VERSION ""

NS_ :

BS_:

BU_: RLPSU DPSU APSU PSB SHVU_RR vHS_B2 FCS EMCU SLB RCM CGW_CCU vDummy_HS_B ATS RLHV PFSU SGU ALBCU DSAU SWRC SHVU_FR RCS RRPSU BLTN_CAM SCM DLBCU OHCL RWPC RRHV WPC HOD ASAU

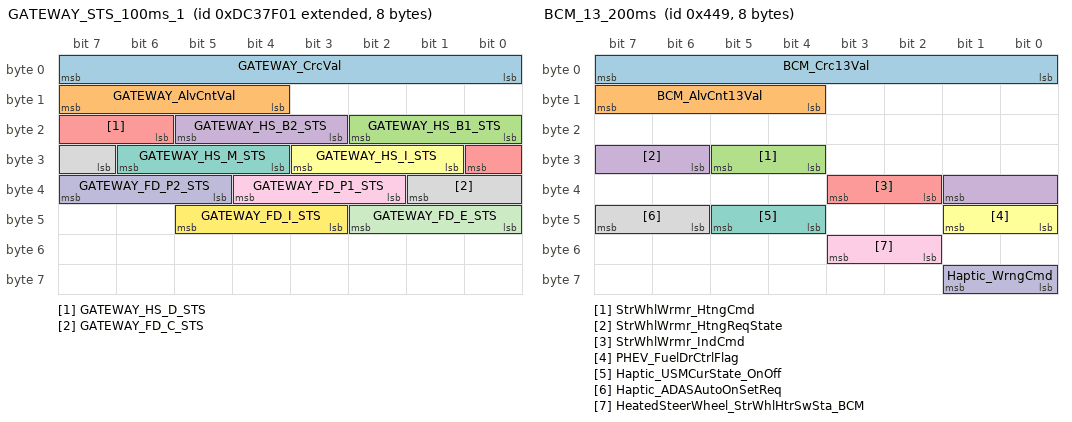
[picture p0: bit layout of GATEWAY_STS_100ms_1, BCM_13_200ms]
BO_ 2378399489 GATEWAY_STS_100ms_1: 8 CGW_CCU
 SG_ GATEWAY_CrcVal : 0|8@1+ (1,0) [0|0] ""  vHS_B2
 SG_ GATEWAY_AlvCntVal : 12|4@1+ (1,0) [0|0] ""  Vector__XXX
 SG_ GATEWAY_HS_B1_STS : 16|3@1+ (1,0) [0|0] ""  vHS_B2
 SG_ GATEWAY_HS_B2_STS : 19|3@1+ (1,0) [0|0] ""  vHS_B2
 SG_ GATEWAY_HS_D_STS : 22|3@1+ (1,0) [0|0] ""  vHS_B2
 SG_ GATEWAY_HS_I_STS : 25|3@1+ (1,0) [0|0] ""  Vector__XXX
 SG_ GATEWAY_HS_M_STS : 28|3@1+ (1,0) [0|0] ""  Vector__XXX
 SG_ GATEWAY_FD_C_STS : 31|3@1+ (1,0) [0|0] ""  Vector__XXX
 SG_ GATEWAY_FD_P1_STS : 34|3@1+ (1,0) [0|0] ""  Vector__XXX
 SG_ GATEWAY_FD_P2_STS : 37|3@1+ (1,0) [0|0] ""  Vector__XXX
 SG_ GATEWAY_FD_E_STS : 40|3@1+ (1,0) [0|0] ""  Vector__XXX
 SG_ GATEWAY_FD_I_STS : 43|3@1+ (1,0) [0|0] ""  vHS_B2

BO_ 1096 SWRC_01_200ms: 8 SWRC
 SG_ SWRC_Crc1Val : 0|8@1+ (1,0) [0|0] ""  Vector__XXX
 SG_ SWRC_AlvCnt1Val : 12|4@1+ (1,0) [0|0] ""  CGW_CCU
 SG_ Audio_VcRecSwSta : 16|2@1+ (1,0) [0|0] ""  CGW_CCU
 SG_ Audio_BluetoothPhnClSwSta : 18|2@1+ (1,0) [0|0] ""  CGW_CCU
 SG_ Audio_BluetoothPhnHangUpSwSta : 20|2@1+ (1,0) [0|0] ""  CGW_CCU
 SG_ Audio_ModSwSta : 22|2@1+ (1,0) [0|0] ""  CGW_CCU
 SG_ Audio_MutSwSta : 24|2@1+ (1,0) [0|0] ""  CGW_CCU
 SG_ Audio_SeekDnSwSta : 26|2@1+ (1,0) [0|0] ""  CGW_CCU
 SG_ Audio_SeekUpSwSta : 28|2@1+ (1,0) [0|0] ""  CGW_CCU
 SG_ Audio_VolDnSwSta : 30|2@1+ (1,0) [0|0] ""  CGW_CCU
 SG_ Audio_VolUpSwSta : 32|2@1+ (1,0) [0|0] ""  CGW_CCU
 SG_ Cluster_ModeSwSta : 34|2@1+ (1,0) [0|0] ""  CGW_CCU
 SG_ Cluster_ScrlDnSwSta : 36|2@1+ (1,0) [0|0] ""  CGW_CCU
 SG_ Cluster_ScrlOkSwSta : 38|2@1+ (1,0) [0|0] ""  CGW_CCU
 SG_ Cluster_ScrlUpSwSta : 40|2@1+ (1,0) [0|0] ""  CGW_CCU
 SG_ Audio_CustomSwSta : 44|2@1+ (1,0) [0|0] ""  CGW_CCU
 SG_ Cluster_ModeCCW : 46|2@1+ (1,0) [0|0] ""  CGW_CCU
 SG_ Cluster_TripDnSwSta : 48|2@1+ (1,0) [0|0] ""  CGW_CCU
 SG_ Cluster_TripUpSwSta : 50|2@1+ (1,0) [0|0] ""  CGW_CCU
 SG_ Cluster_TripOkSwSta : 52|2@1+ (1,0) [0|0] ""  CGW_CCU
 SG_ SWRC_OpticalSwSnstvtSta : 54|2@1+ (1,0) [0|0] ""  CGW_CCU
 SG_ SWRC_RhOpticalSwSta : 56|4@1+ (1,0) [0|0] ""  CGW_CCU
 SG_ Audio_CustomSw3Sta : 8|2@1+ (1,0) [0|0] ""  CGW_CCU

BO_ 1097 BCM_13_200ms: 8 CGW_CCU
 SG_ BCM_Crc13Val : 0|8@1+ (1,0) [0|0] ""  Vector__XXX
 SG_ BCM_AlvCnt13Val : 12|4@1+ (1,0) [0|0] ""  Vector__XXX
 SG_ StrWhlWrmr_HtngCmd : 28|2@1+ (1,0) [0|0] ""  Vector__XXX
 SG_ StrWhlWrmr_HtngReqState : 30|4@1+ (1,0) [0|0] ""  FCS
 SG_ StrWhlWrmr_IndCmd : 34|2@1+ (1,0) [0|0] ""  FCS
 SG_ PHEV_FuelDrCtrlFlag : 40|2@1+ (1,0) [0|0] ""  Vector__XXX
 SG_ Haptic_USMCurState_OnOff : 44|2@1+ (1,0) [0|0] ""  Vector__XXX
 SG_ Haptic_ADASAutoOnSetReq : 46|2@1+ (1,0) [0|0] ""  Vector__XXX
 SG_ HeatedSteerWheel_StrWhlHtrSwSta_BCM : 50|2@1+ (1,0) [0|0] ""  Vector__XXX
 SG_ Haptic_WrngCmd : 56|2@1+ (1,0) [0|0] ""  Vector__XXX

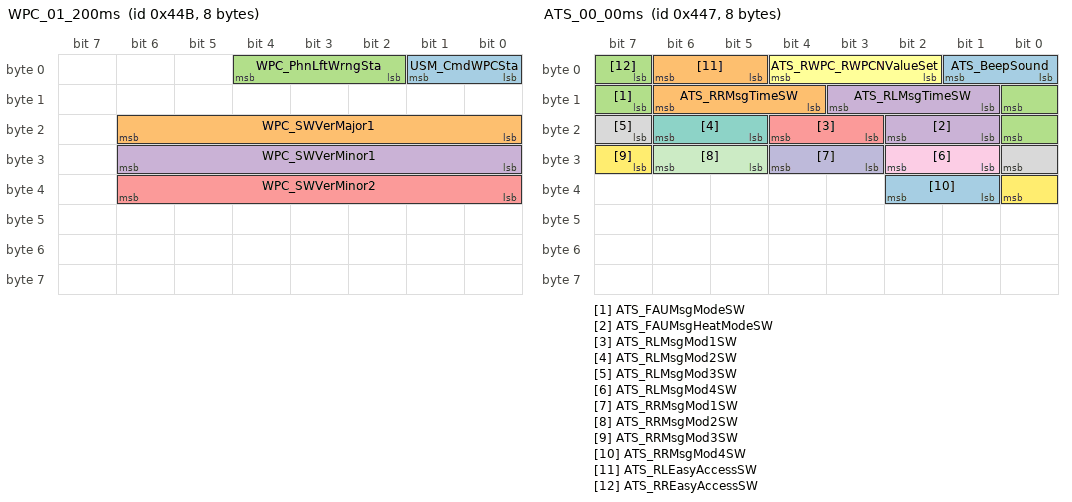
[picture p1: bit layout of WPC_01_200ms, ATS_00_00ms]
BO_ 1099 WPC_01_200ms: 8 WPC
 SG_ USM_CmdWPCSta : 0|2@1+ (1,0) [0|0] ""  CGW_CCU
 SG_ WPC_SWVerMajor1 : 16|7@1+ (1,0) [0|0] ""  CGW_CCU
 SG_ WPC_PhnLftWrngSta : 2|3@1+ (1,0) [0|0] ""  CGW_CCU
 SG_ WPC_SWVerMinor1 : 24|7@1+ (1,0) [0|0] ""  CGW_CCU
 SG_ WPC_SWVerMinor2 : 32|7@1+ (1,0) [0|0] ""  CGW_CCU

BO_ 1092 SMK_02_200ms: 8 CGW_CCU
 SG_ SMK_Crc2Val : 0|8@1+ (1,0) [0|0] ""  Vector__XXX
 SG_ SMK_AlvCnt2Val : 12|4@1+ (1,0) [0|0] ""  Vector__XXX
 SG_ SSB_StrtStpBtnSw1Sta : 16|2@1+ (1,0) [0|0] ""  Vector__XXX
 SG_ SSB_StrtStpBtnSw2Sta : 18|2@1+ (1,0) [0|0] ""  Vector__XXX
 SG_ SMK_TrmnlCtrlSta : 20|4@1+ (1,0) [0|0] ""  BLTN_CAM
 SG_ SMK_TrmnlMngrSta : 24|5@1+ (1,0) [0|0] ""  Vector__XXX
 SG_ SMK_AuthSta : 29|3@1+ (1,0) [0|0] ""  APSU,DPSU
 SG_ SMK_Ign1InSta : 32|2@1+ (1,0) [0|0] ""  Vector__XXX
 SG_ SMK_Ign1RlySta : 34|2@1+ (1,0) [0|0] ""  Vector__XXX
 SG_ SMK_Ign2InSta : 36|2@1+ (1,0) [0|0] ""  Vector__XXX
 SG_ SMK_Ign2RlySta : 38|2@1+ (1,0) [0|0] ""  Vector__XXX
 SG_ SMK_StrtFdbckSta : 40|2@1+ (1,0) [0|0] ""  Vector__XXX
 SG_ SMK_StrtrRlyOutSta : 42|2@1+ (1,0) [0|0] ""  Vector__XXX
 SG_ SMK_AccInSta : 44|2@1+ (1,0) [0|0] ""  Vector__XXX
 SG_ SMK_AccRlySta : 46|2@1+ (1,0) [0|0] ""  Vector__XXX
 SG_ SMK_CLUAccIndOnReq : 48|2@1+ (1,0) [0|0] ""  Vector__XXX
 SG_ SMK_VDModeActSta : 52|2@1+ (1,0) [0|0] ""  Vector__XXX
 SG_ SMK_TlEngRunSta : 56|2@1+ (1,0) [0|0] ""  APSU,RLHV,RRHV,SHVU_FR,SHVU_RR,DPSU,RRPSU,RLPSU,ATS,DSAU,ASAU
 SG_ SMK_TlCrnkModSta : 58|2@1+ (1,0) [0|0] ""  SCM,APSU,DPSU,RRPSU,RLPSU,ATS,DSAU,ASAU
 SG_ SMK_RmtKeyEngRunSta : 60|2@1+ (1,0) [0|0] ""  Vector__XXX
 SG_ SMK_RmtKeyCrnkModSta : 62|2@1+ (1,0) [0|0] ""  Vector__XXX

BO_ 1093 SMK_06_200ms: 8 CGW_CCU
 SG_ SMK_Crc6Val : 0|8@1+ (1,0) [0|0] ""  Vector__XXX
 SG_ SMK_AlvCnt6Val : 12|4@1+ (1,0) [0|0] ""  Vector__XXX
 SG_ Lamp_HzrdBlnkngSta : 16|3@1+ (1,0) [0|0] ""  Vector__XXX
 SG_ RSPA_LearntSta : 19|2@1+ (1,0) [0|0] ""  Vector__XXX
 SG_ Lamp_SmrtWlcmLtOnReq : 21|2@1+ (1,0) [0|0] ""  Vector__XXX
 SG_ Fob_BattStaInfo : 24|2@1+ (1,0) [0|0] ""  Vector__XXX
 SG_ Fob_FoundDrvWlcmArea : 26|2@1+ (1,0) [0|0] ""  Vector__XXX
 SG_ Fob_FoundAsstWlcmArea : 28|2@1+ (1,0) [0|0] ""  Vector__XXX
 SG_ Fob_FoundExtrnlArea : 30|2@1+ (1,0) [0|0] ""  Vector__XXX
 SG_ Fob_FoundIntArea : 32|2@1+ (1,0) [0|0] ""  Vector__XXX
 SG_ Fob_LearntSta : 34|2@1+ (1,0) [0|0] ""  Vector__XXX
 SG_ RSPA_RFSigErrSta : 36|2@1+ (1,0) [0|0] ""  Vector__XXX
 SG_ RSPA_CanErrSta : 38|2@1+ (1,0) [0|0] ""  Vector__XXX
 SG_ LFAnt_FltSta : 40|2@1+ (1,0) [0|0] ""  Vector__XXX
 SG_ LFAnt_SrchSta : 42|2@1+ (1,0) [0|0] ""  WPC,RWPC
 SG_ Auth_ISKLearnSta : 44|3@1+ (1,0) [0|0] ""  Vector__XXX
 SG_ RSPA_ModSta_SMK : 48|3@1+ (1,0) [0|0] ""  DPSU
 SG_ RSPA_FobBattSta : 51|3@1+ (1,0) [0|0] ""  Vector__XXX
 SG_ Fob_BtnReleasedSta : 54|2@1+ (1,0) [0|0] ""  Vector__XXX
 SG_ USM_SmrtTrnkTlgtModSta : 56|3@1+ (1,0) [0|0] ""  Vector__XXX
 SG_ USM_WALModSta : 59|3@1+ (1,0) [0|0] ""  Vector__XXX
 SG_ Fob_FoundWlcmArea : 62|2@1+ (1,0) [0|0] ""  Vector__XXX

BO_ 1094 SLB_01_200ms: 8 SLB
 SG_ SLB_PlyBckSta : 0|2@1+ (1,0) [0|0] ""  Vector__XXX

BO_ 1095 ATS_00_00ms: 8 ATS
 SG_ ATS_BeepSound : 0|2@1+ (1,0) [0|0] ""  CGW_CCU
 SG_ ATS_RRMsgTimeSW : 12|3@1+ (1,0) [0|0] ""  Vector__XXX
 SG_ ATS_FAUMsgModeSW : 15|2@1+ (1,0) [0|0] ""  ASAU
 SG_ ATS_FAUMsgHeatModeSW : 17|2@1+ (1,0) [0|0] ""  ASAU
 SG_ ATS_RLMsgMod1SW : 19|2@1+ (1,0) [0|0] ""  Vector__XXX
 SG_ ATS_RWPC_RWPCNValueSet : 2|3@1+ (1,0) [0|0] ""  RWPC
 SG_ ATS_RLMsgMod2SW : 21|2@1+ (1,0) [0|0] ""  Vector__XXX
 SG_ ATS_RLMsgMod3SW : 23|2@1+ (1,0) [0|0] ""  Vector__XXX
 SG_ ATS_RLMsgMod4SW : 25|2@1+ (1,0) [0|0] ""  Vector__XXX
 SG_ ATS_RRMsgMod1SW : 27|2@1+ (1,0) [0|0] ""  Vector__XXX
 SG_ ATS_RRMsgMod2SW : 29|2@1+ (1,0) [0|0] ""  Vector__XXX
 SG_ ATS_RRMsgMod3SW : 31|2@1+ (1,0) [0|0] ""  Vector__XXX
 SG_ ATS_RRMsgMod4SW : 33|2@1+ (1,0) [0|0] ""  Vector__XXX
 SG_ ATS_RLEasyAccessSW : 5|2@1+ (1,0) [0|0] ""  Vector__XXX
 SG_ ATS_RREasyAccessSW : 7|2@1+ (1,0) [0|0] ""  Vector__XXX
 SG_ ATS_RLMsgTimeSW : 9|3@1+ (1,0) [0|0] ""  Vector__XXX

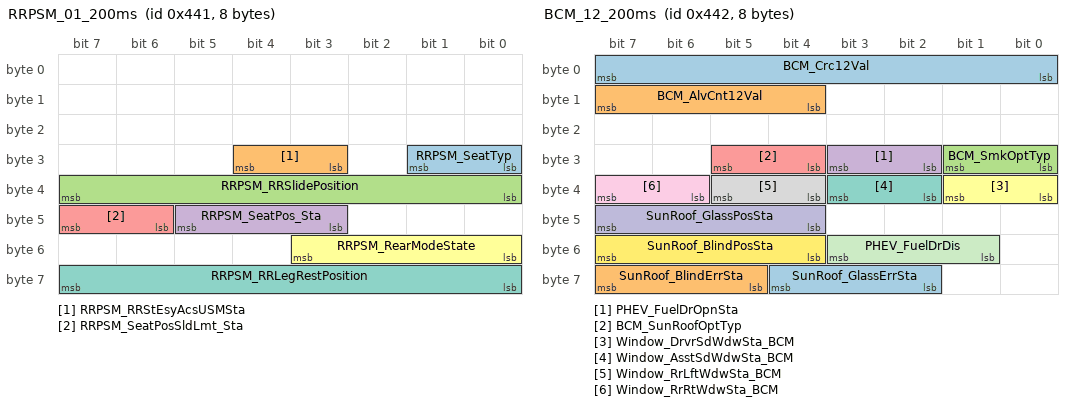
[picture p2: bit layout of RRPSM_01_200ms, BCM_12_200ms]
BO_ 1089 RRPSM_01_200ms: 8 RRPSU
 SG_ RRPSM_SeatTyp : 24|2@1+ (1,0) [0|0] ""  DPSU
 SG_ RRPSM_RRStEsyAcsUSMSta : 27|2@1+ (1,0) [0|0] ""  ATS,CGW_CCU
 SG_ RRPSM_RRSlidePosition : 32|8@1+ (1,0) [0|0] ""  Vector__XXX
 SG_ RRPSM_SeatPos_Sta : 43|3@1+ (1,0) [0|0] ""  Vector__XXX
 SG_ RRPSM_SeatPosSldLmt_Sta : 46|2@1+ (1,0) [0|0] ""  Vector__XXX
 SG_ RRPSM_RearModeState : 48|4@1+ (1,0) [0|0] ""  ATS,OHCL,CGW_CCU
 SG_ RRPSM_RRLegRestPosition : 56|8@1+ (1,0) [0|0] ""  Vector__XXX

BO_ 1090 BCM_12_200ms: 8 CGW_CCU
 SG_ BCM_Crc12Val : 0|8@1+ (1,0) [0|0] ""  Vector__XXX
 SG_ BCM_AlvCnt12Val : 12|4@1+ (1,0) [0|0] ""  Vector__XXX
 SG_ BCM_SmkOptTyp : 24|2@1+ (1,0) [0|0] ""  WPC,RWPC
 SG_ PHEV_FuelDrOpnSta : 26|2@1+ (1,0) [0|0] ""  Vector__XXX
 SG_ BCM_SunRoofOptTyp : 28|2@1+ (1,0) [0|0] ""  ATS
 SG_ Window_DrvrSdWdwSta_BCM : 32|2@1+ (1,0) [0|0] ""  Vector__XXX
 SG_ Window_AsstSdWdwSta_BCM : 34|2@1+ (1,0) [0|0] ""  Vector__XXX
 SG_ Window_RrLftWdwSta_BCM : 36|2@1+ (1,0) [0|0] ""  ATS
 SG_ Window_RrRtWdwSta_BCM : 38|2@1+ (1,0) [0|0] ""  ATS
 SG_ SunRoof_GlassPosSta : 44|4@1+ (1,0) [0|0] ""  Vector__XXX
 SG_ PHEV_FuelDrDis : 49|3@1+ (1,0) [0|0] ""  Vector__XXX
 SG_ SunRoof_BlindPosSta : 52|4@1+ (1,0) [0|0] ""  Vector__XXX
 SG_ SunRoof_GlassErrSta : 58|3@1+ (1,0) [0|0] ""  Vector__XXX
 SG_ SunRoof_BlindErrSta : 61|3@1+ (1,0) [0|0] ""  Vector__XXX

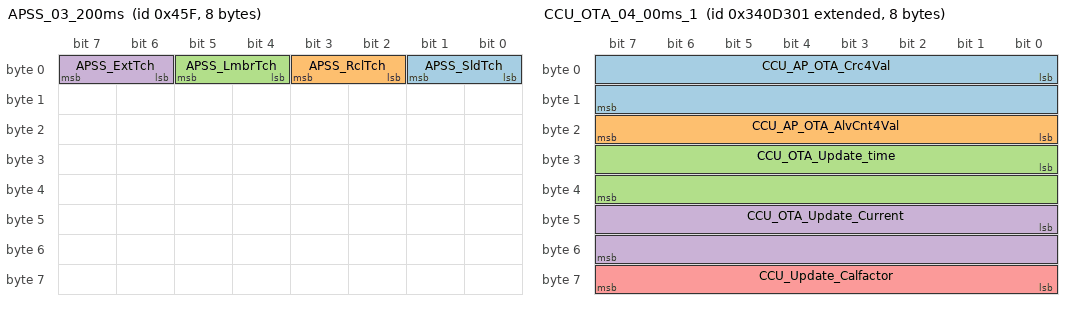
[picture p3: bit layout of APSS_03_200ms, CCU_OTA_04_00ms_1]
BO_ 1119 APSS_03_200ms: 8 APSU
 SG_ APSS_SldTch : 0|2@1+ (1,0) [0|0] ""  Vector__XXX
 SG_ APSS_RclTch : 2|2@1+ (1,0) [0|0] ""  Vector__XXX
 SG_ APSS_LmbrTch : 4|2@1+ (1,0) [0|0] ""  ALBCU,CGW_CCU
 SG_ APSS_ExtTch : 6|2@1+ (1,0) [0|0] ""  Vector__XXX

BO_ 1113 PFSU_01_00ms: 8 PFSU
 SG_ C_LH_Folding_State_PopUp : 0|3@1+ (1,0) [0|0] ""  APSU,CGW_CCU
 SG_ C_RH_Folding_State_PopUp : 3|3@1+ (1,0) [0|0] ""  APSU,CGW_CCU

BO_ 2202063617 CCU_OTA_04_00ms_1: 8 CGW_CCU
 SG_ CCU_AP_OTA_Crc4Val : 0|16@1+ (1,0) [0|0] ""  vDummy_HS_B
 SG_ CCU_AP_OTA_AlvCnt4Val : 16|8@1+ (1,0) [0|0] ""  vDummy_HS_B
 SG_ CCU_OTA_Update_time : 24|16@1+ (1,0) [0|0] ""  Vector__XXX
 SG_ CCU_OTA_Update_Current : 40|16@1+ (1,0) [0|0] ""  Vector__XXX
 SG_ CCU_Update_Calfactor : 56|8@1+ (1,0) [0|0] ""  Vector__XXX

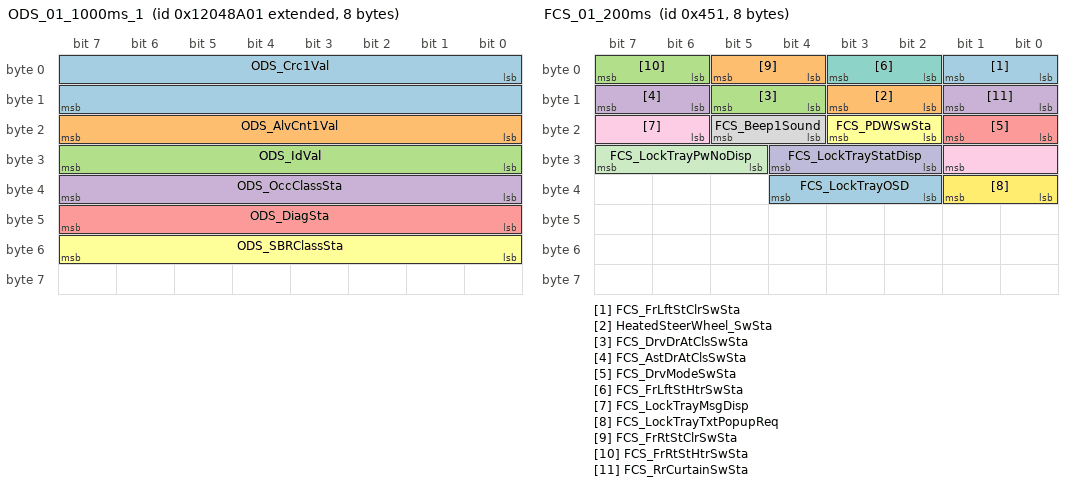
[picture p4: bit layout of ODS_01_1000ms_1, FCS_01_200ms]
BO_ 2449771009 ODS_01_1000ms_1: 8 CGW_CCU
 SG_ ODS_Crc1Val : 0|16@1+ (1,0) [0|0] ""  Vector__XXX
 SG_ ODS_AlvCnt1Val : 16|8@1+ (1,0) [0|0] ""  Vector__XXX
 SG_ ODS_IdVal : 24|8@1+ (1,0) [0|0] ""  Vector__XXX
 SG_ ODS_OccClassSta : 32|8@1+ (1,0) [0|0] ""  APSU,DPSU,ATS
 SG_ ODS_DiagSta : 40|8@1+ (1,0) [0|0] ""  Vector__XXX
 SG_ ODS_SBRClassSta : 48|8@1+ (1,0) [0|0] ""  Vector__XXX

BO_ 1111 PFSU_02_200ms: 8 PFSU
 SG_ C_LH_Folding_Position : 0|3@1+ (1,0) [0|0] ""  APSU,RLPSU,CGW_CCU
 SG_ PFSU_RH_ReclMtrPos : 10|2@1+ (1,0) [0|0] ""  Vector__XXX
 SG_ PFSU_RL_Folding_SW : 16|2@1+ (1,0) [0|0] ""  RLPSU
 SG_ PFSU_RR_Folding_SW : 18|2@1+ (1,0) [0|0] ""  RRPSU
 SG_ PFSU_RL_Unfolding_SW : 20|2@1+ (1,0) [0|0] ""  RLPSU
 SG_ PFSU_RR_Unfolding_SW : 22|2@1+ (1,0) [0|0] ""  RRPSU
 SG_ C_RH_Folding_Position : 3|3@1+ (1,0) [0|0] ""  APSU,RRPSU,CGW_CCU
 SG_ PFSU_RR_FoldingDis : 32|2@1+ (1,0) [0|0] ""  Vector__XXX
 SG_ PFSU_RR_UnfoldingDis : 34|2@1+ (1,0) [0|0] ""  Vector__XXX
 SG_ PFSU_RL_FoldingDis : 36|2@1+ (1,0) [0|0] ""  Vector__XXX
 SG_ PFSU_RL_UnfoldingDis : 38|2@1+ (1,0) [0|0] ""  Vector__XXX
 SG_ PFSU_RR_HrstFoldingDis : 40|2@1+ (1,0) [0|0] ""  Vector__XXX
 SG_ PFSU_RL_HrstFoldingDis : 42|2@1+ (1,0) [0|0] ""  CGW_CCU
 SG_ PFSU_RR_SlideFwdDis : 44|2@1+ (1,0) [0|0] ""  Vector__XXX
 SG_ PFSU_RR_SlidBwdDis : 46|2@1+ (1,0) [0|0] ""  Vector__XXX
 SG_ PFSU_RL_SlideFwdDis : 48|2@1+ (1,0) [0|0] ""  Vector__XXX
 SG_ PFSU_RL_SlideBwdDis : 50|2@1+ (1,0) [0|0] ""  Vector__XXX
 SG_ PFSU_Opt : 56|2@1+ (1,0) [0|0] ""  CGW_CCU
 SG_ PFSU_LH_ReclMtrPos : 8|2@1+ (1,0) [0|0] ""  Vector__XXX

BO_ 2449771010 ODS_01_1000ms_2: 8 CGW_CCU

BO_ 1105 FCS_01_200ms: 8 FCS
 SG_ FCS_FrLftStClrSwSta : 0|2@1+ (1,0) [0|0] ""  APSU,SHVU_FR
 SG_ HeatedSteerWheel_SwSta : 10|2@1+ (1,0) [0|0] ""  CGW_CCU
 SG_ FCS_DrvDrAtClsSwSta : 12|2@1+ (1,0) [0|0] ""  SHVU_FR,CGW_CCU
 SG_ FCS_AstDrAtClsSwSta : 14|2@1+ (1,0) [0|0] ""  SHVU_FR,CGW_CCU
 SG_ FCS_DrvModeSwSta : 16|2@1+ (1,0) [0|0] ""  SHVU_FR,CGW_CCU
 SG_ FCS_PDWSwSta : 18|2@1+ (1,0) [0|0] ""  CGW_CCU
 SG_ FCS_FrLftStHtrSwSta : 2|2@1+ (1,0) [0|0] ""  APSU,SHVU_FR
 SG_ FCS_Beep1Sound : 20|2@1+ (1,0) [0|0] ""  CGW_CCU
 SG_ FCS_LockTrayMsgDisp : 22|4@1+ (1,0) [0|0] ""  ATS
 SG_ FCS_LockTrayStatDisp : 26|3@1+ (1,0) [0|0] ""  ATS
 SG_ FCS_LockTrayPwNoDisp : 29|3@1+ (1,0) [0|0] ""  ATS
 SG_ FCS_LockTrayTxtPopupReq : 32|2@1+ (1,0) [0|0] ""  ATS
 SG_ FCS_LockTrayOSD : 34|3@1+ (1,0) [0|0] ""  ATS
 SG_ FCS_FrRtStClrSwSta : 4|2@1+ (1,0) [0|0] ""  APSU,SHVU_FR
 SG_ FCS_FrRtStHtrSwSta : 6|2@1+ (1,0) [0|0] ""  APSU,SHVU_FR
 SG_ FCS_RrCurtainSwSta : 8|2@1+ (1,0) [0|0] ""  Vector__XXX

BO_ 1107 RR_SHVU_01_200ms: 8 SHVU_FR
 SG_ RR_SHVU_SeatOptSta : 0|3@1+ (1,0) [0|0] ""  ASAU,ATS,CGW_CCU,ATS,CGW_CCU
 SG_ RR_SHVU_SeatHtOperSta : 3|4@1+ (1,0) [0|0] ""  ASAU,ATS,CGW_CCU,ATS,CGW_CCU

BO_ 1134 APSU_03_200ms: 8 APSU
 SG_ APSU_AstStSldFwdDis : 0|2@1+ (1,0) [0|0] ""  CGW_CCU
 SG_ APSU_AstStTiltDnDis : 10|2@1+ (1,0) [0|0] ""  CGW_CCU
 SG_ APSU_AstStHghtUpDis : 12|2@1+ (1,0) [0|0] ""  CGW_CCU
 SG_ APSU_AstStHghtDnDis : 14|2@1+ (1,0) [0|0] ""  CGW_CCU
 SG_ APSU_AstStLegUpDis : 16|2@1+ (1,0) [0|0] ""  Vector__XXX
 SG_ APSU_AstStLegtDnDis : 18|2@1+ (1,0) [0|0] ""  Vector__XXX
 SG_ APSU_AstStSldBckwdDis : 2|2@1+ (1,0) [0|0] ""  CGW_CCU
 SG_ APSU_AstStRlxTiltUpDis : 20|2@1+ (1,0) [0|0] ""  CGW_CCU
 SG_ APSU_AstStRlxTiltDnDis : 22|2@1+ (1,0) [0|0] ""  CGW_CCU
 SG_ APSU_AstStCushExtBckwdDis : 24|2@1+ (1,0) [0|0] ""  Vector__XXX
 SG_ APSU_AstStCushExtFwdDis : 26|2@1+ (1,0) [0|0] ""  Vector__XXX
 SG_ APSU_AstStLmbrDefDis : 32|2@1+ (1,0) [0|0] ""  ALBCU,CGW_CCU
 SG_ APSU_AstStLmbrLoDis : 34|2@1+ (1,0) [0|0] ""  ALBCU,CGW_CCU
 SG_ APSU_AstStLmbrMdlDis : 36|2@1+ (1,0) [0|0] ""  ALBCU,CGW_CCU
 SG_ APSU_AstStLmbrUpDis : 38|2@1+ (1,0) [0|0] ""  ALBCU,CGW_CCU
 SG_ APSU_AstStReclneFwdDis : 4|2@1+ (1,0) [0|0] ""  CGW_CCU
 SG_ APSU_LmbrSigSrcTyp : 44|2@1+ (1,0) [0|0] ""  ALBCU
 SG_ APSU_APSUOpt : 46|2@1+ (1,0) [0|0] ""  RLPSU,RRPSU
 SG_ APSU_AstStReclneBckwdDis : 6|2@1+ (1,0) [0|0] ""  CGW_CCU
 SG_ APSU_AstStTiltUpDis : 8|2@1+ (1,0) [0|0] ""  CGW_CCU

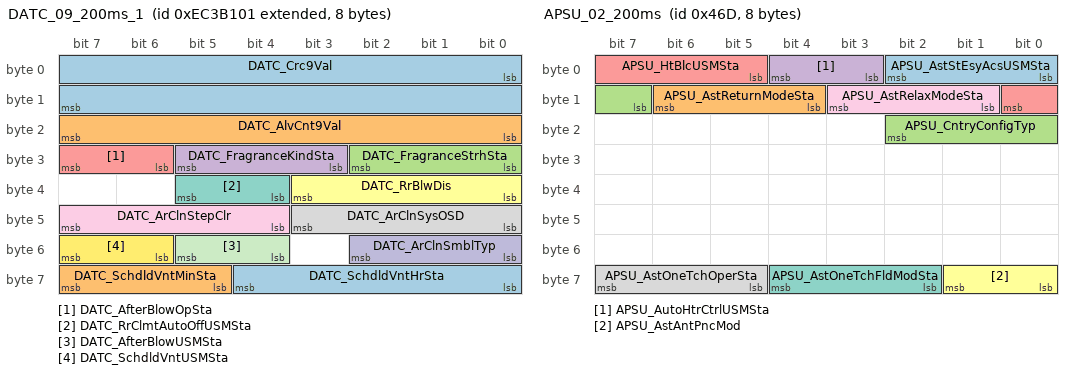
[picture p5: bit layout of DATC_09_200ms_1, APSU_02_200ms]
BO_ 2395189505 DATC_09_200ms_1: 8 CGW_CCU
 SG_ DATC_Crc9Val : 0|16@1+ (1,0) [0|0] ""  Vector__XXX
 SG_ DATC_AlvCnt9Val : 16|8@1+ (1,0) [0|0] ""  Vector__XXX
 SG_ DATC_FragranceStrhSta : 24|3@1+ (1,0) [0|0] ""  ATS
 SG_ DATC_FragranceKindSta : 27|3@1+ (1,0) [0|0] ""  ATS
 SG_ DATC_AfterBlowOpSta : 30|2@1+ (1,0) [0|0] ""  Vector__XXX
 SG_ DATC_RrBlwDis : 32|4@1+ (1,0) [0|0] ""  ATS
 SG_ DATC_RrClmtAutoOffUSMSta : 36|2@1+ (1,0) [0|0] ""  Vector__XXX
 SG_ DATC_ArClnSysOSD : 40|4@1+ (1,0) [0|0] ""  Vector__XXX
 SG_ DATC_ArClnStepClr : 44|4@1+ (1,0) [0|0] ""  ATS
 SG_ DATC_ArClnSmblTyp : 48|3@1+ (1,0) [0|0] ""  ATS
 SG_ DATC_AfterBlowUSMSta : 52|2@1+ (1,0) [0|0] ""  Vector__XXX
 SG_ DATC_SchdldVntUSMSta : 54|2@1+ (1,0) [0|0] ""  Vector__XXX
 SG_ DATC_SchdldVntHrSta : 56|5@1+ (1,0) [0|0] ""  Vector__XXX
 SG_ DATC_SchdldVntMinSta : 61|3@1+ (1,0) [0|0] ""  Vector__XXX

BO_ 1132 DLBCU_03_200ms: 8 DLBCU
 SG_ DLBCU_CushInfDis : 0|2@1+ (1,0) [0|0] ""  DPSU,CGW_CCU
 SG_ DLBCU_CushDefDis : 2|2@1+ (1,0) [0|0] ""  DPSU,CGW_CCU

BO_ 1133 APSU_02_200ms: 8 APSU
 SG_ APSU_AstStEsyAcsUSMSta : 0|3@1+ (1,0) [0|0] ""  ALBCU,CGW_CCU
 SG_ APSU_AstReturnModeSta : 12|3@1+ (1,0) [0|0] ""  CGW_CCU
 SG_ APSU_CntryConfigTyp : 15|4@1+ (1,0) [0|0] ""  Vector__XXX
 SG_ APSU_AutoHtrCtrlUSMSta : 3|2@1+ (1,0) [0|0] ""  Vector__XXX
 SG_ APSU_HtBlcUSMSta : 5|4@1+ (1,0) [0|0] ""  Vector__XXX
 SG_ APSU_AstAntPncMod : 56|2@1+ (1,0) [0|0] ""  RLPSU,RRPSU
 SG_ APSU_AstOneTchFldModSta : 58|3@1+ (1,0) [0|0] ""  RLPSU,RRPSU
 SG_ APSU_AstOneTchOperSta : 61|3@1+ (1,0) [0|0] ""  RLPSU,RRPSU
 SG_ APSU_AstRelaxModeSta : 9|3@1+ (1,0) [0|0] ""  CGW_CCU

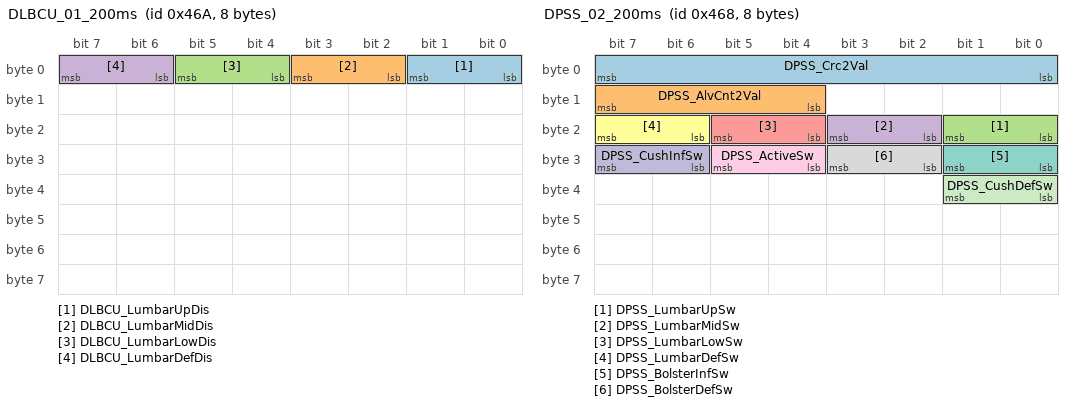
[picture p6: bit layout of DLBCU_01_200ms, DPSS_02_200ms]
BO_ 1130 DLBCU_01_200ms: 8 DLBCU
 SG_ DLBCU_LumbarUpDis : 0|2@1+ (1,0) [0|0] ""  DPSU,CGW_CCU
 SG_ DLBCU_LumbarMidDis : 2|2@1+ (1,0) [0|0] ""  DPSU,CGW_CCU
 SG_ DLBCU_LumbarLowDis : 4|2@1+ (1,0) [0|0] ""  DPSU,CGW_CCU
 SG_ DLBCU_LumbarDefDis : 6|2@1+ (1,0) [0|0] ""  DPSU,CGW_CCU

BO_ 1131 DLBCU_02_200ms: 8 DLBCU
 SG_ DLBCU_BolsterInfDis : 0|2@1+ (1,0) [0|0] ""  DPSU,CGW_CCU
 SG_ DLBCU_BolsterDefDis : 2|2@1+ (1,0) [0|0] ""  DPSU,CGW_CCU

BO_ 1128 DPSS_02_200ms: 8 DPSU
 SG_ DPSS_Crc2Val : 0|8@1+ (1,0) [0|0] ""  DLBCU
 SG_ DPSS_AlvCnt2Val : 12|4@1+ (1,0) [0|0] ""  DLBCU
 SG_ DPSS_LumbarUpSw : 16|2@1+ (1,0) [0|0] ""  DLBCU
 SG_ DPSS_LumbarMidSw : 18|2@1+ (1,0) [0|0] ""  DLBCU
 SG_ DPSS_LumbarLowSw : 20|2@1+ (1,0) [0|0] ""  DLBCU
 SG_ DPSS_LumbarDefSw : 22|2@1+ (1,0) [0|0] ""  DLBCU
 SG_ DPSS_BolsterInfSw : 24|2@1+ (1,0) [0|0] ""  DLBCU
 SG_ DPSS_BolsterDefSw : 26|2@1+ (1,0) [0|0] ""  DLBCU
 SG_ DPSS_ActiveSw : 28|2@1+ (1,0) [0|0] ""  DLBCU
 SG_ DPSS_CushInfSw : 30|2@1+ (1,0) [0|0] ""  DLBCU
 SG_ DPSS_CushDefSw : 32|2@1+ (1,0) [0|0] ""  DLBCU

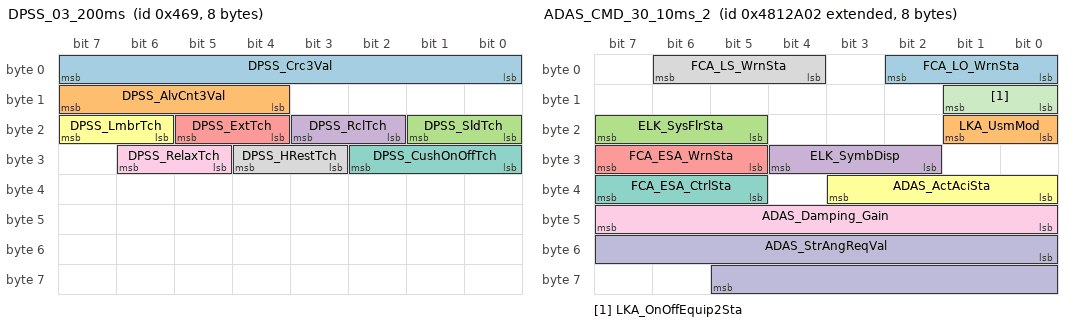
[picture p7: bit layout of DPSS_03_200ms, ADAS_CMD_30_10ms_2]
BO_ 1129 DPSS_03_200ms: 8 DPSU
 SG_ DPSS_Crc3Val : 0|8@1+ (1,0) [0|0] ""  CGW_CCU
 SG_ DPSS_AlvCnt3Val : 12|4@1+ (1,0) [0|0] ""  Vector__XXX
 SG_ DPSS_SldTch : 16|2@1+ (1,0) [0|0] ""  CGW_CCU
 SG_ DPSS_RclTch : 18|2@1+ (1,0) [0|0] ""  CGW_CCU
 SG_ DPSS_ExtTch : 20|2@1+ (1,0) [0|0] ""  CGW_CCU
 SG_ DPSS_LmbrTch : 22|2@1+ (1,0) [0|0] ""  CGW_CCU
 SG_ DPSS_CushOnOffTch : 24|3@1+ (1,0) [0|0] ""  CGW_CCU
 SG_ DPSS_HRestTch : 27|2@1+ (1,0) [0|0] ""  CGW_CCU
 SG_ DPSS_RelaxTch : 29|2@1+ (1,0) [0|0] ""  CGW_CCU

BO_ 2223057410 ADAS_CMD_30_10ms_2: 8 CGW_CCU
 SG_ FCA_LO_WrnSta : 0|3@1+ (1,0) [0|0] ""  SWRC
 SG_ LKA_UsmMod : 16|2@1+ (1,0) [0|0] ""  Vector__XXX
 SG_ ELK_SysFlrSta : 21|3@1+ (1,0) [0|0] ""  Vector__XXX
 SG_ ELK_SymbDisp : 26|3@1+ (1,0) [0|0] ""  Vector__XXX
 SG_ FCA_ESA_WrnSta : 29|3@1+ (1,0) [0|0] ""  SWRC
 SG_ ADAS_ActAciSta : 32|4@1+ (1,0) [0|0] ""  Vector__XXX
 SG_ FCA_ESA_CtrlSta : 37|3@1+ (1,0) [0|0] ""  Vector__XXX
 SG_ FCA_LS_WrnSta : 4|3@1+ (1,0) [0|0] ""  SWRC
 SG_ ADAS_Damping_Gain : 40|8@1+ (1,0) [0|0] ""  Vector__XXX
 SG_ ADAS_StrAngReqVal : 48|14@1- (0.1,0) [0|0] "Deg"  Vector__XXX
 SG_ LKA_OnOffEquip2Sta : 8|2@1+ (1,0) [0|0] ""  Vector__XXX

BO_ 1127 DPSS_01_200ms: 8 DPSU
 SG_ DPSS_Crc1Val : 0|8@1+ (1,0) [0|0] ""  Vector__XXX
 SG_ DPSS_AlvCnt1Val : 12|4@1+ (1,0) [0|0] ""  Vector__XXX
 SG_ DPSS_StExtFwdMvBtn : 16|2@1+ (1,0) [0|0] ""  Vector__XXX
 SG_ DPSS_StExtBwdMvBtn : 18|2@1+ (1,0) [0|0] ""  Vector__XXX
 SG_ DPSS_StSldFwdMvBtn : 20|2@1+ (1,0) [0|0] ""  Vector__XXX
 SG_ DPSS_StSldBwdMvBtn : 24|2@1+ (1,0) [0|0] ""  Vector__XXX
 SG_ DPSS_StRclFwdMvBtn : 26|2@1+ (1,0) [0|0] ""  Vector__XXX
 SG_ DPSS_StRclBwdMvBtn : 28|2@1+ (1,0) [0|0] ""  Vector__XXX
 SG_ DPSS_StHgtUpMvBtn : 30|2@1+ (1,0) [0|0] ""  Vector__XXX
 SG_ DPSS_StHgtDnMvBtn : 32|2@1+ (1,0) [0|0] ""  Vector__XXX
 SG_ DPSS_StTltUpMvBtn : 34|2@1+ (1,0) [0|0] ""  Vector__XXX
 SG_ DPSS_StTltDnMvBtn : 36|2@1+ (1,0) [0|0] ""  Vector__XXX
 SG_ DPSS_StHRestUpMvBtn : 38|2@1+ (1,0) [0|0] ""  Vector__XXX
 SG_ DPSS_StHRestDnMvBtn : 40|2@1+ (1,0) [0|0] ""  Vector__XXX
 SG_ DPSS_StHRestFwdMvBtn : 42|2@1+ (1,0) [0|0] ""  Vector__XXX
 SG_ DPSS_StHRestBwdMvBtn : 44|2@1+ (1,0) [0|0] ""  Vector__XXX
 SG_ DPSS_StLegUpMvBtn : 46|2@1+ (1,0) [0|0] ""  Vector__XXX
 SG_ DPSS_StLegDnMvBtn : 48|2@1+ (1,0) [0|0] ""  Vector__XXX
 SG_ DPSS_StRlxModeBtn : 50|2@1+ (1,0) [0|0] ""  Vector__XXX
 SG_ DPSS_StRlxReturnBtn : 52|2@1+ (1,0) [0|0] ""  Vector__XXX
 SG_ DPSS_StRlxTltUpMvBtn : 54|2@1+ (1,0) [0|0] ""  Vector__XXX
 SG_ DPSS_StRlxTltDnMvBtn : 56|2@1+ (1,0) [0|0] ""  Vector__XXX

BO_TX_BU_ 1107 : SHVU_FR,SHVU_RR,RRHV,RRPSU;
CM_ BO_ 2223057410 "[P] Periodic";
CM_ SG_ 2223057410 FCA_LO_WrnSta "FCA_LO_WarningStatus";
CM_ SG_ 2223057410 LKA_UsmMod "LKA_USM Mode ##2G##LDW_LKA-LKA11-CF_LKA_USM_Mode";
CM_ SG_ 2223057410 ELK_SysFlrSta "ELK System Failure State";
CM_ SG_ 2223057410 ELK_SymbDisp "ELK Symbol Display";
CM_ SG_ 2223057410 FCA_ESA_WrnSta "FCA w/ ESA HMI";
CM_ SG_ 2223057410 ADAS_ActAciSta "ADAS_ActiveAngleControlInterfaceStatus";
CM_ SG_ 2223057410 FCA_ESA_CtrlSta "FCA w/ ESA Control Status";
CM_ SG_ 2223057410 FCA_LS_WrnSta "FCA_LS_WarningStatus";
CM_ SG_ 2223057410 ADAS_Damping_Gain "ADAS_Damping_Gain";
CM_ SG_ 2223057410 ADAS_StrAngReqVal "ADAS_SteeringAngleRequestValue";
CM_ SG_ 2223057410 LKA_OnOffEquip2Sta "LKA On Off Equipment 2 State";
CM_ BO_ 1119 "[PE] Periodic and On Event";
CM_ SG_ 1119 APSS_SldTch "APSS_SlideTouch";
CM_ SG_ 1119 APSS_RclTch "APSS_ReclinerTouch";
CM_ SG_ 1119 APSS_LmbrTch "APSS_LumbarTouch";
CM_ SG_ 1119 APSS_ExtTch "APSS_ExtensionTouch";
CM_ BO_ 1133 "[PE] Periodic and On Event";
CM_ SG_ 1133 APSU_AstStEsyAcsUSMSta "USM_MovingValue";
CM_ SG_ 1133 APSU_CntryConfigTyp "APSU_ContryConfigurationType";
CM_ SG_ 1133 APSU_AutoHtrCtrlUSMSta "Auto Down Seat Heater (USM Setting)";
CM_ SG_ 1133 APSU_HtBlcUSMSta "Hetaer Balance Assistant USM R vaule";
CM_ BO_ 1134 "[PE] Periodic and On Event";
CM_ SG_ 1134 APSU_AstStSldFwdDis "APSU_AssistSlideForwardDisplay";
CM_ SG_ 1134 APSU_AstStTiltDnDis "APSU_AssistTiltDownSwitchDisplay";
CM_ SG_ 1134 APSU_AstStHghtUpDis "APSU_AssistHeightUpSwitchDisplay";
CM_ SG_ 1134 APSU_AstStHghtDnDis "APSU_AssistHeightDownSwitchDisplay";
CM_ SG_ 1134 APSU_AstStLegUpDis "APSU_AssistLegUpSwitchDisplay";
CM_ SG_ 1134 APSU_AstStLegtDnDis "APSU_AssistLegDownSwitchDisplay";
CM_ SG_ 1134 APSU_AstStSldBckwdDis "APSU_AssistSlideBackwardSwitchDisplay";
CM_ SG_ 1134 APSU_AstStRlxTiltUpDis "APSU_AssistRelaxTiltUpSwitchDisplay";
CM_ SG_ 1134 APSU_AstStRlxTiltDnDis "APSU_AssistRelaxTiltDownSwitchDisplay";
CM_ SG_ 1134 APSU_AstStCushExtBckwdDis "APSU_AssistCushionExtendedBackwardSwitchDisplay";
CM_ SG_ 1134 APSU_AstStCushExtFwdDis "APSU_AssistCushionExtendedForwardSwitchDisplay";
CM_ SG_ 1134 APSU_AstStLmbrDefDis "APSU_AssistLumbarDeFlateSwitchDisplay";
CM_ SG_ 1134 APSU_AstStLmbrLoDis "APSU_AssistLumbarLowSwitchDisplay";
CM_ SG_ 1134 APSU_AstStLmbrMdlDis "APSU_AssistLumbarMiddleSwitchDisplay";
CM_ SG_ 1134 APSU_AstStLmbrUpDis "APSU_AssistLumbarUpSwitchDisplay";
CM_ SG_ 1134 APSU_AstStReclneFwdDis "APSU_AssistSeatReclineForwardSwitchDisplay";
CM_ SG_ 1134 APSU_LmbrSigSrcTyp "Lumbar Switch Signal Source(TX)";
CM_ SG_ 1134 APSU_AstStReclneBckwdDis "APSU_AssistSeatReclineBackwardSwitchDisplay";
CM_ SG_ 1134 APSU_AstStTiltUpDis "APSU_AssistTiltUpSwitchDisplay";
CM_ BO_ 1095 "[EC] On Event and On Change";
CM_ SG_ 1095 ATS_BeepSound "ATS to AMP BEEP sound trigger";
CM_ SG_ 1095 ATS_RRMsgTimeSW "Rear Right Massage Time Button";
CM_ SG_ 1095 ATS_FAUMsgModeSW "Rear Right Foot Massage Mode Button";
CM_ SG_ 1095 ATS_FAUMsgHeatModeSW "Rear Right Foot Massage Heat Mode Button";
CM_ SG_ 1095 ATS_RLMsgMod1SW "Rear Left Massage Mode 1 Button";
CM_ SG_ 1095 ATS_RWPC_RWPCNValueSet "Rear Wireless Phone Charger ON/OFF Request";
CM_ SG_ 1095 ATS_RLMsgMod2SW "Rear Left Massage Mode 2 Button";
CM_ SG_ 1095 ATS_RLMsgMod3SW "Rear Left Massage Mode 3 Button";
CM_ SG_ 1095 ATS_RLMsgMod4SW "Rear Left Massage Mode 4 Button";
CM_ SG_ 1095 ATS_RRMsgMod1SW "Rear Right Massage Mode 1 Button";
CM_ SG_ 1095 ATS_RRMsgMod2SW "Rear Right Massage Mode 2 Button";
CM_ SG_ 1095 ATS_RRMsgMod3SW "Rear Right Massage Mode 3 Button";
CM_ SG_ 1095 ATS_RRMsgMod4SW "Rear Right Massage Mode 4 Button";
CM_ SG_ 1095 ATS_RLEasyAccessSW "ATS touch command for seat easy access (For Rear Left)";
CM_ SG_ 1095 ATS_RREasyAccessSW "ATS touch command for seat easy access (For Rear Right)";
CM_ SG_ 1095 ATS_RLMsgTimeSW "Rear Left Massage Time Button";
CM_ BO_ 1090 "[PE] Periodic and On Event";
CM_ SG_ 1090 BCM_Crc12Val "BCM_CyclicRedundancyCheck12Value";
CM_ SG_ 1090 BCM_AlvCnt12Val "BCM_AliveCounter12Value";
CM_ SG_ 1090 BCM_SmkOptTyp "BCM_SmkOptionType ##2G##BCM - BCMmsg17 - C_SMKOption";
CM_ SG_ 1090 PHEV_FuelDrOpnSta "PHEV_FuelDoorOpenStatus ##2G##BCM - BCMmsg20 - C_FuelDrSw";
CM_ SG_ 1090 BCM_SunRoofOptTyp "BCM_SunRoofOptionType";
CM_ SG_ 1090 Window_DrvrSdWdwSta_BCM "Window_DriverSideWindowStatus ##2G##BCM - BCMmsg22 - C_DrvWindowOpenState";
CM_ SG_ 1090 Window_AsstSdWdwSta_BCM "Window_AssistantSideWindowStatus ##2G##BCM - BCMmsg22 - C_AstWindowOpenState";
CM_ SG_ 1090 Window_RrLftWdwSta_BCM "Window_RearLeftWindowStatus ##2G##BCM - BCMmsg22 - C_RLWindowOpenState";
CM_ SG_ 1090 Window_RrRtWdwSta_BCM "Window_RearRightPowerWindowStatus ##2G##BCM - BCMmsg22 - C_RRWindowOpenState";
CM_ SG_ 1090 SunRoof_GlassPosSta "SunRoof_GlassPositionStatus";
CM_ SG_ 1090 PHEV_FuelDrDis "PHEV_FuelDoorDisplay ##2G##BCM - BCMmsg19 - C_PHEVFuelDrDisp";
CM_ SG_ 1090 SunRoof_BlindPosSta "SunRoof_BlindPositionStatus";
CM_ SG_ 1090 SunRoof_GlassErrSta "SunRoof_GlassErrorStatus";
CM_ SG_ 1090 SunRoof_BlindErrSta "SunRoof_BlindErrorStatus";
CM_ BO_ 1097 "[PE] Periodic and On Event";
CM_ SG_ 1097 BCM_Crc13Val "BCM_CyclicRedundancyCheck13Value";
CM_ SG_ 1097 BCM_AlvCnt13Val "BCM_AliveCounter13Value";
CM_ SG_ 1097 PHEV_FuelDrCtrlFlag "PHEV_FuelDoorOpenStatus ##2G##BCM - BCMmsg20 - C_FuelDrSw";
CM_ SG_ 1097 HeatedSteerWheel_StrWhlHtrSwSta_BCM "HeatedSteerWheel_SwitchStatus ##2G##BCM - BCMmsg24 - C_StrgWhlHeatedState";
CM_ BO_ 2202063617 "[EC] On Event and On Change";
CM_ SG_ 2202063617 CCU_OTA_Update_time "¾÷µ¥ÀÌÆ® ¿¹»ó½Ã°£";
CM_ SG_ 2202063617 CCU_OTA_Update_Current "Current consumption expected";
CM_ SG_ 2202063617 CCU_Update_Calfactor "Determination SOC setting";
CM_ BO_ 2395189505 "[PE] Periodic and On Event";
CM_ SG_ 2395189505 DATC_Crc9Val "DATC_CyclicRedundancyCheck9Value";
CM_ SG_ 2395189505 DATC_AlvCnt9Val "DATC_AliveCounter9Value";
CM_ SG_ 2395189505 DATC_FragranceStrhSta "Fragrance Strength State";
CM_ SG_ 2395189505 DATC_FragranceKindSta "Fragrance Kind State";
CM_ SG_ 2395189505 DATC_AfterBlowOpSta "DATC_AfterBlow Operation Status";
CM_ SG_ 2395189505 DATC_RrBlwDis "DATC_RearBlowerDisplay";
CM_ SG_ 2395189505 DATC_RrClmtAutoOffUSMSta "DATC_RearClimateAutoOffUSMState";
CM_ SG_ 2395189505 DATC_ArClnSysOSD "DATC_AirCleaningSystemOSD";
CM_ SG_ 2395189505 DATC_ArClnStepClr "DATC_AirCleaningStepColor";
CM_ SG_ 2395189505 DATC_ArClnSmblTyp "DATC_AirCleaningSymbolType";
CM_ SG_ 2395189505 DATC_AfterBlowUSMSta "DATC_AfterBlowUSMStatus";
CM_ SG_ 2395189505 DATC_SchdldVntUSMSta "DATC_ScheduledVentilationUSMStatus";
CM_ SG_ 2395189505 DATC_SchdldVntHrSta "DATC_ScheduledVentilationHourStatus";
CM_ SG_ 2395189505 DATC_SchdldVntMinSta "DATC_ScheduledVentilationMinutesStatus";
CM_ BO_ 1130 "[PE] Periodic and On Event";
CM_ SG_ 1130 DLBCU_LumbarUpDis "DLBCU_LumbarUppperDisplay";
CM_ SG_ 1130 DLBCU_LumbarMidDis "DLBCU_LumbarMidDisplay";
CM_ SG_ 1130 DLBCU_LumbarLowDis "DLBCU_LumbarLowerDisplay";
CM_ SG_ 1130 DLBCU_LumbarDefDis "DLBCU_LumbarDeflationDisplay";
CM_ BO_ 1131 "[PE] Periodic and On Event";
CM_ SG_ 1131 DLBCU_BolsterInfDis "DLBCU_BolsterInflationDisplay";
CM_ SG_ 1131 DLBCU_BolsterDefDis "DLBCU_BolsterDeflationDisplay";
CM_ BO_ 1132 "[PE] Periodic and On Event";
CM_ SG_ 1132 DLBCU_CushInfDis "DLBCU_CushionInflationDisplay";
CM_ SG_ 1132 DLBCU_CushDefDis "DLBCU_CushionDeflationDisplay";
CM_ BO_ 1127 "[PE] Periodic and On Event";
CM_ SG_ 1127 DPSS_Crc1Val "DPSS_CyclicRedundancyCheck1Value";
CM_ SG_ 1127 DPSS_AlvCnt1Val "DPSS_AliveCounter1Value";
CM_ SG_ 1127 DPSS_StExtFwdMvBtn "DPSS_ExtensionForwardMoveButton";
CM_ SG_ 1127 DPSS_StExtBwdMvBtn "DPSS_ExtensionBackwardMoveButton";
CM_ SG_ 1127 DPSS_StSldFwdMvBtn "DPSS_SlideForwardMoveButton";
CM_ SG_ 1127 DPSS_StSldBwdMvBtn "DPSS_SlideBackwardMoveButton";
CM_ SG_ 1127 DPSS_StRclFwdMvBtn "DPSS_ReclinerForwardMoveButton";
CM_ SG_ 1127 DPSS_StRclBwdMvBtn "DPSS_ReclinerBackwardMoveButton";
CM_ SG_ 1127 DPSS_StHgtUpMvBtn "DPSS_HeightUpMoveButton";
CM_ SG_ 1127 DPSS_StHgtDnMvBtn "DPSS_HeightDownMoveButton";
CM_ SG_ 1127 DPSS_StTltUpMvBtn "DPSS_TiltUpMoveButton";
CM_ SG_ 1127 DPSS_StTltDnMvBtn "DPSS_TiltDownMoveButton";
CM_ SG_ 1127 DPSS_StHRestUpMvBtn "DPSS_StHRestUpMvBtn";
CM_ SG_ 1127 DPSS_StHRestDnMvBtn "DPSS_StHRestDnMvBtn";
CM_ SG_ 1127 DPSS_StHRestFwdMvBtn "DPSS_StHRestFwdMvBtn";
CM_ SG_ 1127 DPSS_StHRestBwdMvBtn "DPSS_StHRestBwdMvBtn";
CM_ SG_ 1127 DPSS_StLegUpMvBtn "DPSS_LegUpMoveButton";
CM_ SG_ 1127 DPSS_StLegDnMvBtn "DPSS_LegDownMoveButton";
CM_ SG_ 1127 DPSS_StRlxModeBtn "DPSS_RelaxModeButton";
CM_ SG_ 1127 DPSS_StRlxReturnBtn "DPSS_RelaxReturnButton";
CM_ SG_ 1127 DPSS_StRlxTltUpMvBtn "DPSS_RelaxTiltUpMoveButton";
CM_ SG_ 1127 DPSS_StRlxTltDnMvBtn "DPSS_RelaxTiltDownMoveButton";
CM_ BO_ 1128 "[PE] Periodic and On Event";
CM_ SG_ 1128 DPSS_Crc2Val "DPSS_CyclicRedundancyCheck2Value";
CM_ SG_ 1128 DPSS_AlvCnt2Val "DPSS_AliveCounter2Value";
CM_ SG_ 1128 DPSS_LumbarUpSw "DPSS_LumbarUpMoveSwitch";
CM_ SG_ 1128 DPSS_LumbarMidSw "DPSS_LumbarMiddleSwitch";
CM_ SG_ 1128 DPSS_LumbarLowSw "DPSS_LumbarLowerSwitch";
CM_ SG_ 1128 DPSS_LumbarDefSw "DPSS_LumbarDeflationSwitch";
CM_ SG_ 1128 DPSS_BolsterInfSw "DPSS_BolsterInflationSwitch";
CM_ SG_ 1128 DPSS_BolsterDefSw "DPSS_BolsterDeflationSwitch";
CM_ SG_ 1128 DPSS_ActiveSw "DPSS_ActiveSwitch";
CM_ SG_ 1128 DPSS_CushInfSw "DPSS_Cush Support Inflation Switch";
CM_ SG_ 1128 DPSS_CushDefSw "DPSS_Cush Support Deflation Switch";
CM_ BO_ 1129 "[PE] Periodic and On Event";
CM_ SG_ 1129 DPSS_Crc3Val "DPSS_CyclicRedundancyCheck3Value";
CM_ SG_ 1129 DPSS_AlvCnt3Val "DPSS_AliveCounter3Value";
CM_ SG_ 1129 DPSS_SldTch "DPSS_SlideTouch";
CM_ SG_ 1129 DPSS_RclTch "DPSS_ReclinerTouch";
CM_ SG_ 1129 DPSS_ExtTch "DPSS_ExtensionTouch";
CM_ SG_ 1129 DPSS_LmbrTch "DPSS_LumbarTouch";
CM_ SG_ 1129 DPSS_CushOnOffTch "DPSS_CushOnOffTouch";
CM_ SG_ 1129 DPSS_HRestTch "DPSS_HeadResetTouch";
CM_ SG_ 1129 DPSS_RelaxTch "DPSS_RelaxTouch";
CM_ BO_ 1105 "[PE] Periodic and On Event";
CM_ SG_ 1105 FCS_FrLftStClrSwSta "FCS_FrontLeftSeatCoolerSwitchStatus";
CM_ SG_ 1105 HeatedSteerWheel_SwSta "HeatedSteerWheel_SwitchStatus";
CM_ SG_ 1105 FCS_FrLftStHtrSwSta "FCS_FrontLeftSeatHeaterSwitchStatus";
CM_ SG_ 1105 FCS_LockTrayMsgDisp "FCS_LockTrayMessageDisplacement";
CM_ SG_ 1105 FCS_LockTrayStatDisp "FCS_LockTrayStateDisplacement";
CM_ SG_ 1105 FCS_LockTrayPwNoDisp "FCS_LockTrayPasswordNumberDisplacement";
CM_ SG_ 1105 FCS_LockTrayTxtPopupReq "FCS_LockTrayTextPopupRequest";
CM_ SG_ 1105 FCS_LockTrayOSD "FCS_LockTrayOnScreenDisplacement";
CM_ SG_ 1105 FCS_FrRtStClrSwSta "FCS_FrontRightSeatCoolerSwitchStatus";
CM_ SG_ 1105 FCS_FrRtStHtrSwSta "FCS_FrontRightSeatHeaterSwitchStatus";
CM_ SG_ 1105 FCS_RrCurtainSwSta "FCS_RearCurtainSwitchFcsStatus";
CM_ BO_ 2378399489 "[P] Periodic";
CM_ SG_ 2378399489 GATEWAY_CrcVal "GATEWAY_CyclicRedundancyCheckValue";
CM_ SG_ 2378399489 GATEWAY_AlvCntVal "GATEWAY_AliveCounterValue";
CM_ BO_ 2449771009 "[P] Periodic";
CM_ SG_ 2449771009 ODS_Crc1Val "ODS_CyclicRedundancyCheck1Value";
CM_ SG_ 2449771009 ODS_AlvCnt1Val "ODS_AliveCounter1Value";
CM_ SG_ 2449771009 ODS_IdVal "ODS_IdValue ##2G##ODS - ODS13 - CR_Ods_ID";
CM_ SG_ 2449771009 ODS_OccClassSta "ODS_OccupantClassificationStatus ##2G##ODS - ODS11 - CR_Wcs_ClassStat";
CM_ SG_ 2449771009 ODS_DiagSta "ODS_SelfDiagnosticStatus ##2G##ODS - ODS11 - CR_Wcs_ErrStat";
CM_ SG_ 2449771009 ODS_SBRClassSta "ODS_SBRClassSta";
CM_ BO_ 2449771010 "[P] Periodic";
CM_ BO_ 1113 "[EC] On Event and On Change";
CM_ BO_ 1111 "[PE] Periodic and On Event";
CM_ SG_ 1111 PFSU_RH_ReclMtrPos "PFSU Rear Right Recliner Motor Posion Information";
CM_ SG_ 1111 PFSU_RL_Folding_SW "PFSU Rear Left Folding Switch";
CM_ SG_ 1111 PFSU_RR_Folding_SW "PFSU Rear Right Folding Switch";
CM_ SG_ 1111 PFSU_RL_Unfolding_SW "PFSU Rear Left Unfolding Switch";
CM_ SG_ 1111 PFSU_RR_Unfolding_SW "PFSU Rear Right Unfolding Switch";
CM_ SG_ 1111 PFSU_RR_FoldingDis "Third LH PSU Folding moving state: Folding";
CM_ SG_ 1111 PFSU_RR_UnfoldingDis "Third LH PSU Unfolding moving state: Unfolding";
CM_ SG_ 1111 PFSU_RL_FoldingDis "Third RH PSU Folding moving state: Folding";
CM_ SG_ 1111 PFSU_RL_UnfoldingDis "Third RH PSU Unfolding moving state: Unfolding";
CM_ SG_ 1111 PFSU_RR_HrstFoldingDis "Third RH H/rest Folding moving state: H/rest folding";
CM_ SG_ 1111 PFSU_RL_HrstFoldingDis "Third LH H/rest Folding moving state: H/rest folding";
CM_ SG_ 1111 PFSU_RR_SlideFwdDis "Third LH PSU Recliner FWD moving state";
CM_ SG_ 1111 PFSU_RR_SlidBwdDis "Third LH PSU Recliner BWD moving state";
CM_ SG_ 1111 PFSU_RL_SlideFwdDis "Third RH PSU Recliner FWD moving state";
CM_ SG_ 1111 PFSU_RL_SlideBwdDis "Third RH PSU Recliner BWD moving state";
CM_ SG_ 1111 PFSU_Opt "PFSU Option Information";
CM_ SG_ 1111 PFSU_LH_ReclMtrPos "PFSU Rear Left Recliner Motor Posion Information";
CM_ BO_ 1089 "[PE] Periodic and On Event";
CM_ SG_ 1089 RRPSM_RRStEsyAcsUSMSta "USM_MovingValue";
CM_ SG_ 1089 RRPSM_SeatPos_Sta "RRPSM_SeatPosition_State";
CM_ SG_ 1089 RRPSM_SeatPosSldLmt_Sta "RRPSM_SeatPositionSlideLimitState";
CM_ BO_ 1107 "[PE] Periodic and On Event";
CM_ SG_ 1107 RR_SHVU_SeatOptSta "Rear RH Seat Heater/Vent option info";
CM_ SG_ 1107 RR_SHVU_SeatHtOperSta "Rear RH Seat Heater/Vent current operation state";
CM_ BO_ 1094 "[PE] Periodic and On Event";
CM_ SG_ 1094 SLB_PlyBckSta "SLB_PlayBackStatus";
CM_ BO_ 1092 "[PE] Periodic and On Event";
CM_ SG_ 1092 SMK_Crc2Val "SMK_CyclicRedundancyCheck2Value";
CM_ SG_ 1092 SMK_AlvCnt2Val "SMK_AliveCounter2Value";
CM_ SG_ 1092 SSB_StrtStpBtnSw1Sta "SSB_StartStopButtonSwitch1Status ##2G##SMK - SMKmsg19 - C_SSBSW1";
CM_ SG_ 1092 SSB_StrtStpBtnSw2Sta "SSB_StartStopButtonSwitch2Status ##2G##SMK - SMKmsg19 - C_SSBSW2";
CM_ SG_ 1092 SMK_TrmnlCtrlSta "SMK_TerminalControlStatus ##2G##SMK - SMKmsg19 - C_TerminalControlState";
CM_ SG_ 1092 SMK_TrmnlMngrSta "SMK_TerminalManagerStatus ##2G##SMK - SMKmsg19 - C_TerminalsManagerState";
CM_ SG_ 1092 SMK_AuthSta "SMK_AuthentificationStatus ##2G##SMK - SMKmsg18 - C_AuthState";
CM_ SG_ 1092 SMK_Ign1InSta "SMK_Ign1InputStatus ##2G##SMK - SMKmsg19 - C_Ign1SMK";
CM_ SG_ 1092 SMK_Ign1RlySta "SMK_Ign1RelayStatus ##2G##SMK - SMKmsg19 - C_Ign1RelayState";
CM_ SG_ 1092 SMK_Ign2InSta "SMK_Ign2InputStatus ##2G##SMK - SMKmsg19 - C_Ign2SMK";
CM_ SG_ 1092 SMK_Ign2RlySta "SMK_Ign2RelayStatus ##2G##SMK - SMKmsg19 - C_Ign2RelayState";
CM_ SG_ 1092 SMK_StrtFdbckSta "SMK_StartFeedbackStatus ##2G##SMK - SMKmsg19 - C_StartFeedback";
CM_ SG_ 1092 SMK_StrtrRlyOutSta "SMK_StarterRelayOutputStatus ##2G##SMK - SMKmsg18 - C_StarterRlyState";
CM_ SG_ 1092 SMK_AccInSta "SMK_AccInputStatus ##2G##SMK - SMKmsg19 - C_AccSMK";
CM_ SG_ 1092 SMK_AccRlySta "SMK_AccRelayStatus ##2G##SMK - SMKmsg19 - C_AccRelayStatus";
CM_ SG_ 1092 SMK_CLUAccIndOnReq "SMK_ClusterACCIndicatorOnRequest ##2G##SMK - SMKmsg19 - C_AccINDforCLU";
CM_ SG_ 1092 SMK_VDModeActSta "SMK_VirtualDriverModeActState";
CM_ SG_ 1092 SMK_TlEngRunSta "SMK_TeleEngineRunStatus ##2G##SMK - SMKmsg18 - C_SMKTeleEngineRunning";
CM_ SG_ 1092 SMK_TlCrnkModSta "SMK_TeleCrankingModeStatus ##2G##SMK - SMKmsg18 - C_SMKTeleCrankingState";
CM_ SG_ 1092 SMK_RmtKeyEngRunSta "SMK_RemoteKeyEngineRunStatus";
CM_ SG_ 1092 SMK_RmtKeyCrnkModSta "SMK_RemoteKeyCrankingModeStatus";
CM_ BO_ 1093 "[PE] Periodic and On Event";
CM_ SG_ 1093 SMK_Crc6Val "SMK_CyclicRedundancyCheck6Value";
CM_ SG_ 1093 SMK_AlvCnt6Val "SMK_AliveCounter6Value";
CM_ SG_ 1093 Lamp_HzrdBlnkngSta "Lamp_HazardBlinkingStatus ##2G##SMK - SMKmsg17 - C_HazardFromSMK";
CM_ SG_ 1093 Lamp_SmrtWlcmLtOnReq "Lamp_SmartWelcomeLightOnRequest ##2G##SMK - SMKmsg17 - C_WlightOn";
CM_ SG_ 1093 Fob_BattStaInfo "Fob_BatteryStatusInformation ##2G##SMK - SMKmsg17 - C_FOBBatteryStatusInfo";
CM_ SG_ 1093 Fob_FoundDrvWlcmArea "Fob_FoundDriverWelcomeArea ##2G##SMK - SMKmsg17 - C_WelcomeFobFoundDrv";
CM_ SG_ 1093 Fob_FoundAsstWlcmArea "Fob_FoundAssistWelcomeArea ##2G##SMK - SMKmsg17 - C_WelcomeFobFoundAst";
CM_ SG_ 1093 Fob_FoundExtrnlArea "Fob_FoundExternalArea ##2G##SMK - SMKmsg18 - C_ExtFobPos";
CM_ SG_ 1093 Fob_FoundIntArea "Fob_FoundInternalArea ##2G##SMK - SMKmsg18 - C_IntFobPos";
CM_ SG_ 1093 Fob_LearntSta "Fob_LearntStatus ##2G##SMK - SMKmsg18 - C_FobLearntState";
CM_ SG_ 1093 RSPA_RFSigErrSta "RSPA_RFSignalErrorState";
CM_ SG_ 1093 RSPA_CanErrSta "RSPA_CANErrorState";
CM_ SG_ 1093 LFAnt_FltSta "LFAntenna_FaultSatus ##2G##SMK - SMKmsg18 - C_LFANTState";
CM_ SG_ 1093 LFAnt_SrchSta "LFAntenna_SearchingStatus ##2G##SMK - SMKmsg19 - C_LFSearchingOn";
CM_ SG_ 1093 Auth_ISKLearnSta "Fob_FoundAssistWelcomeArea ##2G##SMK - SMKmsg178 - C_IBUISKLearnState";
CM_ SG_ 1093 RSPA_ModSta_SMK "RSPA_ModeStatus ##2G##SMK - SMKmsg18 - C_SMKRSPAMode";
CM_ SG_ 1093 RSPA_FobBattSta "RSPA_FobBatteryStatus ##2G##SMK - SMKmsg18 - C_FobBATState";
CM_ SG_ 1093 USM_SmrtTrnkTlgtModSta "USM_SmartTunkTailgateModeStatus ##2G##SMK - SMKmsg20 - C_HfreeTrunkTgRValue";
CM_ SG_ 1093 USM_WALModSta "USM_WalkAwayLockModeStatus ##2G##SMK - SMKmsg20 - C_WALRValue";
CM_ SG_ 1093 Fob_FoundWlcmArea "Fob_FoundWlcmArea ##2G##SMK - SMKmsg17 -C_FobFoundWlcmArea";
CM_ BO_ 1096 "[PE] Periodic and On Event";
CM_ SG_ 1096 SWRC_Crc1Val "SWRC_CyclicRedundancyCheck1Value";
CM_ SG_ 1096 SWRC_AlvCnt1Val "SWRC_AliveCounter1Value";
CM_ SG_ 1096 Audio_VcRecSwSta "Audio_VoiceReconitionSwitchStatus";
CM_ SG_ 1096 Audio_BluetoothPhnClSwSta "Audio_BluetoothPhoneCallSwitchStatus";
CM_ SG_ 1096 Audio_BluetoothPhnHangUpSwSta "Audio_BluetoothPhoneHangUpSwitchStatus";
CM_ SG_ 1096 Audio_ModSwSta "Audio_ModeSwitchStatus";
CM_ SG_ 1096 Audio_MutSwSta "Audio_MuteSwitchStatus";
CM_ SG_ 1096 Audio_SeekDnSwSta "Audio_SeekDownSwitchStatus";
CM_ SG_ 1096 Audio_SeekUpSwSta "Audio_SeekUpSwitchStatus";
CM_ SG_ 1096 Audio_VolDnSwSta "Audio_VolumeDownSwitchStatus";
CM_ SG_ 1096 Audio_VolUpSwSta "Audio_VolumeUpSwitchStatus";
CM_ SG_ 1096 Cluster_ModeSwSta "Cluster_ModeSwitchStatus";
CM_ SG_ 1096 Cluster_ScrlDnSwSta "Cluster_ScrollDownSwitchStatus";
CM_ SG_ 1096 Cluster_ScrlOkSwSta "Cluster_ScrollOkSwitchStatus";
CM_ SG_ 1096 Cluster_ScrlUpSwSta "Cluster_ScrollUpSwitchStatus";
CM_ SG_ 1096 Audio_CustomSwSta "Audio_CustomSwitchStatus";
CM_ SG_ 1096 Cluster_ModeCCW "Cluster Menu Control (Back Key)";
CM_ SG_ 1096 Cluster_TripDnSwSta "Cluster_TripDnSwSta";
CM_ SG_ 1096 Cluster_TripUpSwSta "Cluster Menu Control (Up)";
CM_ SG_ 1096 Cluster_TripOkSwSta "Cluster_TripOkSwSta";
CM_ SG_ 1096 SWRC_OpticalSwSnstvtSta "SWRC_OpticalSwitchSensitivityStatus";
CM_ SG_ 1096 SWRC_RhOpticalSwSta "SWRC_RhOpticalSwitchStatus";
CM_ SG_ 1096 Audio_CustomSw3Sta "Audio_CustomSwitch 3rd Status";
CM_ BO_ 1099 "[PE] Periodic and On Event";
CM_ SG_ 1099 USM_CmdWPCSta "USM_CommandWPCStatus";
CM_ SG_ 1099 WPC_SWVerMajor1 "First Word(ASCII) in WPC S/W Ver";
CM_ SG_ 1099 WPC_PhnLftWrngSta "WPC_PhoneLeftWarningStatus";
CM_ SG_ 1099 WPC_SWVerMinor1 "Second Word(ASCII) in WPC S/W Ver";
CM_ SG_ 1099 WPC_SWVerMinor2 "Third Word(ASCII) in WPC S/W Ver";
BA_DEF_ BO_ "DiagState" ENUM "No","Yes" ;
BA_DEF_ BO_ "DiagResponse" ENUM "No","Yes" ;
BA_DEF_ BO_ "DiagRequest" ENUM "No","Yes" ;
BA_DEF_ BO_ "TpMessage" ENUM "No","Yes" ;
BA_DEF_ BO_ "UsrMsgIDSforwardDeviation" INT 0 100 ;
BA_DEF_ BO_ "UsrMsgIDSbackwardDeviation" INT 50 1000 ;
BA_DEF_ "BusType" STRING ;
BA_DEF_ "DBName" STRING ;
BA_DEF_ "Baudrate" INT 50000 1000000 ;
BA_DEF_ "GenEnvVarEndingDsp" STRING ;
BA_DEF_ "GenEnvVarEndingSnd" STRING ;
BA_DEF_ "GenEnvVarPrefix" STRING ;
BA_DEF_ "GenNWMApBusSleep" STRING ;
BA_DEF_ "GenNWMApCanNormal" STRING ;
BA_DEF_ "GenNWMApCanOff" STRING ;
BA_DEF_ "GenNWMApCanOn" STRING ;
BA_DEF_ "GenNWMApCanSleep" STRING ;
BA_DEF_ "GenNWMApCanWakeUp" STRING ;
BA_DEF_ "GenNWMGotoMode_Awake" STRING ;
BA_DEF_ "GenNWMGotoMode_BusSleep" STRING ;
BA_DEF_ "GenNWMSleepTime" INT 1375 1650 ;
BA_DEF_ "GenNWMTalkNM" STRING ;
BA_DEF_ "Manufacturer" STRING ;
BA_DEF_ "NmBaseAddress" HEX 0 2047 ;
BA_DEF_ "NmMessageCount" INT 0 128 ;
BA_DEF_ "NmType" STRING ;
BA_DEF_ "SamplePointMax" INT 50 85 ;
BA_DEF_ "SamplePointMin" INT 55 85 ;
BA_DEF_ "SyncJumpWidthMax" INT 1 8 ;
BA_DEF_ "SyncJumpWidthMin" INT 1 4 ;
BA_DEF_ "VersionDay" INT 1 31 ;
BA_DEF_ "VersionMonth" INT 1 12 ;
BA_DEF_ "VersionNumber" INT 0 999999 ;
BA_DEF_ "VersionNumberInternal" INT 0 9999 ;
BA_DEF_ "VersionWeek" INT 1 53 ;
BA_DEF_ "VersionYear" INT 0 9999 ;
BA_DEF_ BU_ "NmStationAddress" HEX 0 127 ;
BA_DEF_ BU_ "NmNode" ENUM "No","Yes" ;
BA_DEF_ BU_ "GenNodSleepTime" INT 1375 1650 ;
BA_DEF_ BU_ "ILUsed" ENUM "No","Yes" ;
BA_DEF_ BU_ "NmCAN" INT 1 2 ;
BA_DEF_ BU_ "NodeLayerModules" STRING ;
BA_DEF_ BU_ "NWM_Knoten" ENUM "No","Yes" ;
BA_DEF_ BO_ "GenMsgCycleTime" INT 0 2000 ;
BA_DEF_ BO_ "GenMsgStartDelayTime" INT 0 2000 ;
BA_DEF_ BO_ "GenMsgSendType" ENUM "Cyclic","NoMsgSendType" ;
BA_DEF_ BO_ "GenMsgCycleTimeFast" INT 0 500 ;
BA_DEF_ BO_ "GenMsgDelayTime" INT 0 20 ;
BA_DEF_ BO_ "GenMsgILSupport" ENUM "No","Yes" ;
BA_DEF_ BO_ "GenMsgNrOfRepetition" INT 0 3 ;
BA_DEF_ BO_ "NmMessage" ENUM "No","Yes" ;
BA_DEF_ BO_ "NWM-Botschaft" ENUM "No","Yes" ;
BA_DEF_ BO_ "TpTxIndex" INT 0 255 ;
BA_DEF_ BO_ "VFrameFormat" ENUM "StandardCAN","ExtendedCAN","reserved","reserved","reserved","reserved","reserved","reserved","reserved","reserved","reserved","reserved","reserved","reserved","StandardCAN_FD","ExtendedCAN_FD" ;
BA_DEF_ SG_ "UserSigValidity" ENUM "B+","ACC","IG","IG1","IG2","IG3","IG1 or IG2","IG1 or IG3","Undef" ;
BA_DEF_ SG_ "TimeoutValue" STRING ;
BA_DEF_ SG_ "UsrSigPurpose" ENUM "Undef","FN","DIAG","DIAG(Req)","DIAG(Res)","DIAG(Phy)","DEV","CCP(Req)","CCP(Res)","NM","TP" ;
BA_DEF_ SG_ "GenSigStartValue" INT 0 1215752192 ;
BA_DEF_ SG_ "NetworkRequest" ENUM "Yes","No" ;
BA_DEF_ SG_ "NetworkRequestHoldingTime" INT 0 65535 ;
BA_DEF_ SG_ "Description" STRING ;
BA_DEF_ SG_ "Version" STRING ;
BA_DEF_ SG_ "GenSigEnvVarType" ENUM "Int","Float","Undef" ;
BA_DEF_ SG_ "GenSigSendType" ENUM "Cyclic","OnWrite","OnWriteWithRepetition","OnChange","OnChangeWithRepetition","IfActive","IfActiveWithRepetition","NoSigSendType","OnChangeAndIfActive","OnChangeAndIfActiveWithRepetition" ;
BA_DEF_ SG_ "GwSigLatencyTime" INT 0 65536 ;
BA_DEF_ SG_ "GwSigMissingSourceType" ENUM "Undef","OldValue","DefaultValue","InitialValue" ;
BA_DEF_ SG_ "NWM-WakeupAllowed" ENUM "<n.a.>" ;
BA_DEF_ SG_ "RoutingFactor" INT 1 1215752192 ;
BA_DEF_REL_ BU_SG_REL_ "GenSigTimeoutTime" INT 0 7000 ;
BA_DEF_DEF_ "DiagState" "No" ;
BA_DEF_DEF_ "DiagResponse" "No" ;
BA_DEF_DEF_ "DiagRequest" "No" ;
BA_DEF_DEF_ "TpMessage" "No" ;
BA_DEF_DEF_ "UsrMsgIDSforwardDeviation" 10 ;
BA_DEF_DEF_ "UsrMsgIDSbackwardDeviation" 100 ;
BA_DEF_DEF_ "BusType" "CAN" ;
BA_DEF_DEF_ "DBName" "" ;
BA_DEF_DEF_ "Baudrate" 500000 ;
BA_DEF_DEF_ "GenEnvVarEndingDsp" "Dsp_" ;
BA_DEF_DEF_ "GenEnvVarEndingSnd" "_" ;
BA_DEF_DEF_ "GenEnvVarPrefix" "Env" ;
BA_DEF_DEF_ "GenNWMApBusSleep" "AppNmCanBusSleep()" ;
BA_DEF_DEF_ "GenNWMApCanNormal" "AppNmCanNormal()" ;
BA_DEF_DEF_ "GenNWMApCanOff" "ApplCanOffline()" ;
BA_DEF_DEF_ "GenNWMApCanOn" "ApplCanOnline()" ;
BA_DEF_DEF_ "GenNWMApCanSleep" "ApplNmCanSleep()" ;
BA_DEF_DEF_ "GenNWMApCanWakeUp" "ApplCanWakeUp()" ;
BA_DEF_DEF_ "GenNWMGotoMode_Awake" "GotoMode_Awake()" ;
BA_DEF_DEF_ "GenNWMGotoMode_BusSleep" "GotoMode_BusSleep()" ;
BA_DEF_DEF_ "GenNWMSleepTime" 1500 ;
BA_DEF_DEF_ "GenNWMTalkNM" "TalkNM()" ;
BA_DEF_DEF_ "Manufacturer" "HMC" ;
BA_DEF_DEF_ "NmBaseAddress" 1280 ;
BA_DEF_DEF_ "NmMessageCount" 128 ;
BA_DEF_DEF_ "NmType" "Vector" ;
BA_DEF_DEF_ "SamplePointMax" 80 ;
BA_DEF_DEF_ "SamplePointMin" 80 ;
BA_DEF_DEF_ "SyncJumpWidthMax" 3 ;
BA_DEF_DEF_ "SyncJumpWidthMin" 2 ;
BA_DEF_DEF_ "VersionDay" 1 ;
BA_DEF_DEF_ "VersionMonth" 1 ;
BA_DEF_DEF_ "VersionNumber" 0 ;
BA_DEF_DEF_ "VersionNumberInternal" 0 ;
BA_DEF_DEF_ "VersionWeek" 1 ;
BA_DEF_DEF_ "VersionYear" 0 ;
BA_DEF_DEF_ "NmStationAddress" 0 ;
BA_DEF_DEF_ "NmNode" "Yes" ;
BA_DEF_DEF_ "GenNodSleepTime" 1500 ;
BA_DEF_DEF_ "ILUsed" "Yes" ;
BA_DEF_DEF_ "NmCAN" 1 ;
BA_DEF_DEF_ "NodeLayerModules" "oseknm01.dll,CANoeILNLVector.dll" ;
BA_DEF_DEF_ "NWM_Knoten" "Yes" ;
BA_DEF_DEF_ "GenMsgCycleTime" 200 ;
BA_DEF_DEF_ "GenMsgStartDelayTime" 0 ;
BA_DEF_DEF_ "GenMsgSendType" "NoMsgSendType" ;
BA_DEF_DEF_ "GenMsgCycleTimeFast" 40 ;
BA_DEF_DEF_ "GenMsgDelayTime" 20 ;
BA_DEF_DEF_ "GenMsgILSupport" "Yes" ;
BA_DEF_DEF_ "GenMsgNrOfRepetition" 3 ;
BA_DEF_DEF_ "NmMessage" "No" ;
BA_DEF_DEF_ "NWM-Botschaft" "No" ;
BA_DEF_DEF_ "TpTxIndex" 0 ;
BA_DEF_DEF_ "VFrameFormat" "StandardCAN" ;
BA_DEF_DEF_ "UserSigValidity" "IG" ;
BA_DEF_DEF_ "TimeoutValue" "" ;
BA_DEF_DEF_ "UsrSigPurpose" "FN" ;
BA_DEF_DEF_ "GenSigStartValue" 0 ;
BA_DEF_DEF_ "NetworkRequest" "No" ;
BA_DEF_DEF_ "NetworkRequestHoldingTime" 0 ;
BA_DEF_DEF_ "Description" "" ;
BA_DEF_DEF_ "Version" "" ;
BA_DEF_DEF_ "GenSigEnvVarType" "Undef" ;
BA_DEF_DEF_ "GenSigSendType" "NoSigSendType" ;
BA_DEF_DEF_ "GwSigLatencyTime" 40 ;
BA_DEF_DEF_ "GwSigMissingSourceType" "Undef" ;
BA_DEF_DEF_ "NWM-WakeupAllowed" "<n.a.>" ;
BA_DEF_DEF_ "RoutingFactor" 1 ;
BA_DEF_DEF_REL_ "GenSigTimeoutTime" 500 ;
BA_ "DBName" "HS_B2";
BA_ "VersionYear" 1;
BA_ "VersionNumber" 211204;
BA_ "NmStationAddress" BU_ CGW_CCU 112;
BA_ "NmStationAddress" BU_ OHCL 84;
BA_ "NmStationAddress" BU_ PSB 65;
BA_ "NmStationAddress" BU_ APSU 49;
BA_ "NmStationAddress" BU_ ATS 80;
BA_ "NmStationAddress" BU_ RRPSU 29;
BA_ "NmStationAddress" BU_ RLPSU 28;
BA_ "NmStationAddress" BU_ SWRC 8;
BA_ "GenMsgSendType" BO_ 2223057410 0;
BA_ "GenMsgCycleTime" BO_ 2223057410 50;
BA_ "GenMsgCycleTimeFast" BO_ 2223057410 0;
BA_ "GenMsgNrOfRepetition" BO_ 2223057410 0;
BA_ "VFrameFormat" BO_ 2223057410 1;
BA_ "Description" SG_ 2223057410 FCA_LO_WrnSta "This signal indicates FCA-LO warning for display and sound.";
BA_ "UserSigValidity" SG_ 2223057410 FCA_LO_WrnSta 3;
BA_ "RoutingFactor" SG_ 2223057410 FCA_LO_WrnSta 5;
BA_ "Version" SG_ 2223057410 FCA_LO_WrnSta "17.11.00";
BA_ "Description" SG_ 2223057410 LKA_UsmMod "This signal indicates LKA USM Mode";
BA_ "UserSigValidity" SG_ 2223057410 LKA_UsmMod 3;
BA_ "RoutingFactor" SG_ 2223057410 LKA_UsmMod 5;
BA_ "Version" SG_ 2223057410 LKA_UsmMod "19.05.00";
BA_ "Description" SG_ 2223057410 ELK_SysFlrSta "ELK ÀÛµ¿ Á¦ÇÑ, °íÀå ÆË¾÷ ½ÅÈ£";
BA_ "UserSigValidity" SG_ 2223057410 ELK_SysFlrSta 3;
BA_ "RoutingFactor" SG_ 2223057410 ELK_SysFlrSta 5;
BA_ "Version" SG_ 2223057410 ELK_SysFlrSta "20.09.00";
BA_ "Description" SG_ 2223057410 ELK_SymbDisp "This signal describes warning symbol about ELK system (FCA-LO/LS, w/ ESA).";
BA_ "UserSigValidity" SG_ 2223057410 ELK_SymbDisp 3;
BA_ "RoutingFactor" SG_ 2223057410 ELK_SymbDisp 5;
BA_ "Version" SG_ 2223057410 ELK_SymbDisp "20.12.04";
BA_ "Description" SG_ 2223057410 FCA_ESA_WrnSta "FCA w/ ESA HMI";
BA_ "UserSigValidity" SG_ 2223057410 FCA_ESA_WrnSta 3;
BA_ "RoutingFactor" SG_ 2223057410 FCA_ESA_WrnSta 5;
BA_ "Version" SG_ 2223057410 FCA_ESA_WrnSta "18.08.06";
BA_ "Description" SG_ 2223057410 ADAS_ActAciSta "State for angle control";
BA_ "UserSigValidity" SG_ 2223057410 ADAS_ActAciSta 3;
BA_ "RoutingFactor" SG_ 2223057410 ADAS_ActAciSta 5;
BA_ "Version" SG_ 2223057410 ADAS_ActAciSta "19.11.03";
BA_ "Description" SG_ 2223057410 FCA_ESA_CtrlSta "FCA w/ ESA Control Status for ECS Control";
BA_ "UserSigValidity" SG_ 2223057410 FCA_ESA_CtrlSta 3;
BA_ "RoutingFactor" SG_ 2223057410 FCA_ESA_CtrlSta 5;
BA_ "Version" SG_ 2223057410 FCA_ESA_CtrlSta "18.10.00";
BA_ "Description" SG_ 2223057410 FCA_LS_WrnSta "This signal indicates FCA-LS warning for display and sound.";
BA_ "UserSigValidity" SG_ 2223057410 FCA_LS_WrnSta 3;
BA_ "RoutingFactor" SG_ 2223057410 FCA_LS_WrnSta 5;
BA_ "Version" SG_ 2223057410 FCA_LS_WrnSta "17.11.00";
BA_ "Description" SG_ 2223057410 ADAS_Damping_Gain "ADAS Damping Gain for MDPS";
BA_ "GenSigStartValue" SG_ 2223057410 ADAS_Damping_Gain 100;
BA_ "UserSigValidity" SG_ 2223057410 ADAS_Damping_Gain 3;
BA_ "RoutingFactor" SG_ 2223057410 ADAS_Damping_Gain 5;
BA_ "Version" SG_ 2223057410 ADAS_Damping_Gain "18.12.01";
BA_ "Description" SG_ 2223057410 ADAS_StrAngReqVal "Request angle control value";
BA_ "UserSigValidity" SG_ 2223057410 ADAS_StrAngReqVal 3;
BA_ "RoutingFactor" SG_ 2223057410 ADAS_StrAngReqVal 5;
BA_ "Version" SG_ 2223057410 ADAS_StrAngReqVal "19.08.05";
BA_ "Description" SG_ 2223057410 LKA_OnOffEquip2Sta "Signal to turn LKA function on and off in USM. When USM content for LKA function is just a toggle button, this signal can be used.";
BA_ "UserSigValidity" SG_ 2223057410 LKA_OnOffEquip2Sta 3;
BA_ "RoutingFactor" SG_ 2223057410 LKA_OnOffEquip2Sta 5;
BA_ "Version" SG_ 2223057410 LKA_OnOffEquip2Sta "20.12.00";
BA_ "NmStationAddress" BU_ HOD 74;
BA_ "NmStationAddress" BU_ FCS 33;
BA_ "NmStationAddress" BU_ DPSU 56;
BA_ "NmStationAddress" BU_ SHVU_FR 42;
BA_ "NmStationAddress" BU_ ALBCU 68;
BA_ "GenMsgSendType" BO_ 1119 0;
BA_ "GenSigSendType" SG_ 1119 APSS_SldTch 4;
BA_ "UserSigValidity" SG_ 1119 APSS_SldTch 3;
BA_ "NetworkRequest" SG_ 1119 APSS_SldTch 0;
BA_ "NetworkRequestHoldingTime" SG_ 1119 APSS_SldTch 5000;
BA_ "Version" SG_ 1119 APSS_SldTch "19.03.08";
BA_ "GenSigSendType" SG_ 1119 APSS_RclTch 4;
BA_ "UserSigValidity" SG_ 1119 APSS_RclTch 3;
BA_ "NetworkRequest" SG_ 1119 APSS_RclTch 0;
BA_ "NetworkRequestHoldingTime" SG_ 1119 APSS_RclTch 5000;
BA_ "Version" SG_ 1119 APSS_RclTch "19.03.08";
BA_ "GenSigSendType" SG_ 1119 APSS_LmbrTch 4;
BA_ "UserSigValidity" SG_ 1119 APSS_LmbrTch 3;
BA_REL_ "GenSigTimeoutTime" BU_SG_REL_ ALBCU SG_ 1119 APSS_LmbrTch 1500;
BA_REL_ "GenSigTimeoutTime" BU_SG_REL_ CGW_CCU SG_ 1119 APSS_LmbrTch 1500;
BA_ "NetworkRequest" SG_ 1119 APSS_LmbrTch 0;
BA_ "NetworkRequestHoldingTime" SG_ 1119 APSS_LmbrTch 5000;
BA_ "Version" SG_ 1119 APSS_LmbrTch "19.03.08";
BA_ "Description" SG_ 1119 APSS_ExtTch "ÅÍÄ¡ ½ºÀ§Ä¡ Á¤º¸";
BA_ "GenSigSendType" SG_ 1119 APSS_ExtTch 4;
BA_ "UserSigValidity" SG_ 1119 APSS_ExtTch 3;
BA_ "NetworkRequest" SG_ 1119 APSS_ExtTch 0;
BA_ "NetworkRequestHoldingTime" SG_ 1119 APSS_ExtTch 5000;
BA_ "Version" SG_ 1119 APSS_ExtTch "20.11.02";
BA_ "GenMsgSendType" BO_ 1133 0;
BA_ "GenSigSendType" SG_ 1133 APSU_AstStEsyAcsUSMSta 4;
BA_ "UserSigValidity" SG_ 1133 APSU_AstStEsyAcsUSMSta 0;
BA_REL_ "GenSigTimeoutTime" BU_SG_REL_ ALBCU SG_ 1133 APSU_AstStEsyAcsUSMSta 1500;
BA_REL_ "GenSigTimeoutTime" BU_SG_REL_ CGW_CCU SG_ 1133 APSU_AstStEsyAcsUSMSta 1500;
BA_ "NetworkRequest" SG_ 1133 APSU_AstStEsyAcsUSMSta 0;
BA_ "NetworkRequestHoldingTime" SG_ 1133 APSU_AstStEsyAcsUSMSta 5000;
BA_ "Version" SG_ 1133 APSU_AstStEsyAcsUSMSta "18.02.01";
BA_ "Description" SG_ 1133 APSU_AstReturnModeSta "APSU_AssistReturnModeState";
BA_ "GenSigSendType" SG_ 1133 APSU_AstReturnModeSta 4;
BA_ "UserSigValidity" SG_ 1133 APSU_AstReturnModeSta 0;
BA_REL_ "GenSigTimeoutTime" BU_SG_REL_ CGW_CCU SG_ 1133 APSU_AstReturnModeSta 1500;
BA_ "NetworkRequest" SG_ 1133 APSU_AstReturnModeSta 0;
BA_ "NetworkRequestHoldingTime" SG_ 1133 APSU_AstReturnModeSta 5000;
BA_ "Version" SG_ 1133 APSU_AstReturnModeSta "19.12.00";
BA_ "GenSigSendType" SG_ 1133 APSU_CntryConfigTyp 4;
BA_ "UserSigValidity" SG_ 1133 APSU_CntryConfigTyp 0;
BA_ "NetworkRequest" SG_ 1133 APSU_CntryConfigTyp 0;
BA_ "NetworkRequestHoldingTime" SG_ 1133 APSU_CntryConfigTyp 5000;
BA_ "Version" SG_ 1133 APSU_CntryConfigTyp "21.07.06";
BA_ "Description" SG_ 1133 APSU_AutoHtrCtrlUSMSta "-(Old)C_AstAutoHeatRValue";
BA_ "GenSigSendType" SG_ 1133 APSU_AutoHtrCtrlUSMSta 4;
BA_ "UserSigValidity" SG_ 1133 APSU_AutoHtrCtrlUSMSta 0;
BA_ "NetworkRequest" SG_ 1133 APSU_AutoHtrCtrlUSMSta 0;
BA_ "NetworkRequestHoldingTime" SG_ 1133 APSU_AutoHtrCtrlUSMSta 5000;
BA_ "Version" SG_ 1133 APSU_AutoHtrCtrlUSMSta "18.02.01";
BA_ "Description" SG_ 1133 APSU_HtBlcUSMSta "Hetaer Balance Assistant USM R vaule";
BA_ "GenSigSendType" SG_ 1133 APSU_HtBlcUSMSta 4;
BA_ "UserSigValidity" SG_ 1133 APSU_HtBlcUSMSta 0;
BA_ "Version" SG_ 1133 APSU_HtBlcUSMSta "18.07.03";
BA_ "Description" SG_ 1133 APSU_AstAntPncMod "¾ÈÆ¼-ÇÉÄ¡ µ¿ÀÛ »óÅÂ Á¤º¸

Anti-Pinch Mode Operating Status Information";
BA_ "GenSigSendType" SG_ 1133 APSU_AstAntPncMod 4;
BA_ "UserSigValidity" SG_ 1133 APSU_AstAntPncMod 0;
BA_REL_ "GenSigTimeoutTime" BU_SG_REL_ RLPSU SG_ 1133 APSU_AstAntPncMod 1500;
BA_REL_ "GenSigTimeoutTime" BU_SG_REL_ RRPSU SG_ 1133 APSU_AstAntPncMod 1500;
BA_ "Version" SG_ 1133 APSU_AstAntPncMod "20.12.04";
BA_ "Description" SG_ 1133 APSU_AstOneTchFldModSta "¸®Å¬¶óÀÌ´× / ¿øÅÍÄ¡Æúµå ¸ðµå Á¤º¸

Assist Reclining / One-Touch Folding Mode Status Information";
BA_ "GenSigSendType" SG_ 1133 APSU_AstOneTchFldModSta 4;
BA_ "UserSigValidity" SG_ 1133 APSU_AstOneTchFldModSta 0;
BA_REL_ "GenSigTimeoutTime" BU_SG_REL_ RLPSU SG_ 1133 APSU_AstOneTchFldModSta 1500;
BA_REL_ "GenSigTimeoutTime" BU_SG_REL_ RRPSU SG_ 1133 APSU_AstOneTchFldModSta 1500;
BA_ "Version" SG_ 1133 APSU_AstOneTchFldModSta "20.12.04";
BA_ "Description" SG_ 1133 APSU_AstOneTchOperSta "¿øÅÍÄ¡ µ¿ÀÛ °¡´É ¿©ºÎ ¹× µ¿ÀÛ ¿Ï·á »óÅÂ Á¤º¸

One-Touch Operating Status Information";
BA_ "GenSigSendType" SG_ 1133 APSU_AstOneTchOperSta 4;
BA_ "UserSigValidity" SG_ 1133 APSU_AstOneTchOperSta 0;
BA_REL_ "GenSigTimeoutTime" BU_SG_REL_ RLPSU SG_ 1133 APSU_AstOneTchOperSta 1500;
BA_REL_ "GenSigTimeoutTime" BU_SG_REL_ RRPSU SG_ 1133 APSU_AstOneTchOperSta 1500;
BA_ "Version" SG_ 1133 APSU_AstOneTchOperSta "20.12.04";
BA_ "Description" SG_ 1133 APSU_AstRelaxModeSta "APSU_AssistRelaxModeState";
BA_ "GenSigSendType" SG_ 1133 APSU_AstRelaxModeSta 4;
BA_ "UserSigValidity" SG_ 1133 APSU_AstRelaxModeSta 0;
BA_REL_ "GenSigTimeoutTime" BU_SG_REL_ CGW_CCU SG_ 1133 APSU_AstRelaxModeSta 1500;
BA_ "NetworkRequest" SG_ 1133 APSU_AstRelaxModeSta 0;
BA_ "NetworkRequestHoldingTime" SG_ 1133 APSU_AstRelaxModeSta 5000;
BA_ "Version" SG_ 1133 APSU_AstRelaxModeSta "19.12.00";
BA_ "GenMsgSendType" BO_ 1134 0;
BA_ "Description" SG_ 1134 APSU_AstStSldFwdDis "This signal is used to display the seat movement to AVN";
BA_ "GenSigSendType" SG_ 1134 APSU_AstStSldFwdDis 4;
BA_ "UserSigValidity" SG_ 1134 APSU_AstStSldFwdDis 1;
BA_REL_ "GenSigTimeoutTime" BU_SG_REL_ CGW_CCU SG_ 1134 APSU_AstStSldFwdDis 1500;
BA_ "NetworkRequest" SG_ 1134 APSU_AstStSldFwdDis 0;
BA_ "NetworkRequestHoldingTime" SG_ 1134 APSU_AstStSldFwdDis 5000;
BA_ "Version" SG_ 1134 APSU_AstStSldFwdDis "18.02.01";
BA_ "Description" SG_ 1134 APSU_AstStTiltDnDis "This signal is used to display the seat movement to AVN";
BA_ "GenSigSendType" SG_ 1134 APSU_AstStTiltDnDis 4;
BA_ "UserSigValidity" SG_ 1134 APSU_AstStTiltDnDis 1;
BA_REL_ "GenSigTimeoutTime" BU_SG_REL_ CGW_CCU SG_ 1134 APSU_AstStTiltDnDis 1500;
BA_ "NetworkRequest" SG_ 1134 APSU_AstStTiltDnDis 0;
BA_ "NetworkRequestHoldingTime" SG_ 1134 APSU_AstStTiltDnDis 5000;
BA_ "Version" SG_ 1134 APSU_AstStTiltDnDis "18.02.01";
BA_ "Description" SG_ 1134 APSU_AstStHghtUpDis "This signal is used to display the seat movement to AVN";
BA_ "GenSigSendType" SG_ 1134 APSU_AstStHghtUpDis 4;
BA_ "UserSigValidity" SG_ 1134 APSU_AstStHghtUpDis 1;
BA_REL_ "GenSigTimeoutTime" BU_SG_REL_ CGW_CCU SG_ 1134 APSU_AstStHghtUpDis 1500;
BA_ "NetworkRequest" SG_ 1134 APSU_AstStHghtUpDis 0;
BA_ "NetworkRequestHoldingTime" SG_ 1134 APSU_AstStHghtUpDis 5000;
BA_ "Version" SG_ 1134 APSU_AstStHghtUpDis "18.02.01";
BA_ "Description" SG_ 1134 APSU_AstStHghtDnDis "This signal is used to display the seat movement to AVN";
BA_ "GenSigSendType" SG_ 1134 APSU_AstStHghtDnDis 4;
BA_ "UserSigValidity" SG_ 1134 APSU_AstStHghtDnDis 1;
BA_REL_ "GenSigTimeoutTime" BU_SG_REL_ CGW_CCU SG_ 1134 APSU_AstStHghtDnDis 1500;
BA_ "NetworkRequest" SG_ 1134 APSU_AstStHghtDnDis 0;
BA_ "NetworkRequestHoldingTime" SG_ 1134 APSU_AstStHghtDnDis 5000;
BA_ "Version" SG_ 1134 APSU_AstStHghtDnDis "18.02.01";
BA_ "Description" SG_ 1134 APSU_AstStLegUpDis "This signal is used to display the seat movement to AVN";
BA_ "GenSigSendType" SG_ 1134 APSU_AstStLegUpDis 4;
BA_ "UserSigValidity" SG_ 1134 APSU_AstStLegUpDis 1;
BA_ "NetworkRequest" SG_ 1134 APSU_AstStLegUpDis 0;
BA_ "NetworkRequestHoldingTime" SG_ 1134 APSU_AstStLegUpDis 5000;
BA_ "Version" SG_ 1134 APSU_AstStLegUpDis "19.12.00";
BA_ "Description" SG_ 1134 APSU_AstStLegtDnDis "This signal is used to display the seat movement to AVN";
BA_ "GenSigSendType" SG_ 1134 APSU_AstStLegtDnDis 4;
BA_ "UserSigValidity" SG_ 1134 APSU_AstStLegtDnDis 1;
BA_ "NetworkRequest" SG_ 1134 APSU_AstStLegtDnDis 0;
BA_ "NetworkRequestHoldingTime" SG_ 1134 APSU_AstStLegtDnDis 5000;
BA_ "Version" SG_ 1134 APSU_AstStLegtDnDis "19.12.00";
BA_ "Description" SG_ 1134 APSU_AstStSldBckwdDis "This signal is used to display the seat movement to AVN";
BA_ "GenSigSendType" SG_ 1134 APSU_AstStSldBckwdDis 4;
BA_ "UserSigValidity" SG_ 1134 APSU_AstStSldBckwdDis 1;
BA_REL_ "GenSigTimeoutTime" BU_SG_REL_ CGW_CCU SG_ 1134 APSU_AstStSldBckwdDis 1500;
BA_ "NetworkRequest" SG_ 1134 APSU_AstStSldBckwdDis 0;
BA_ "NetworkRequestHoldingTime" SG_ 1134 APSU_AstStSldBckwdDis 5000;
BA_ "Version" SG_ 1134 APSU_AstStSldBckwdDis "18.02.01";
BA_ "Description" SG_ 1134 APSU_AstStRlxTiltUpDis "This signal is used to display the seat movement to AVN";
BA_ "GenSigSendType" SG_ 1134 APSU_AstStRlxTiltUpDis 4;
BA_ "UserSigValidity" SG_ 1134 APSU_AstStRlxTiltUpDis 1;
BA_REL_ "GenSigTimeoutTime" BU_SG_REL_ CGW_CCU SG_ 1134 APSU_AstStRlxTiltUpDis 1500;
BA_ "NetworkRequest" SG_ 1134 APSU_AstStRlxTiltUpDis 0;
BA_ "NetworkRequestHoldingTime" SG_ 1134 APSU_AstStRlxTiltUpDis 5000;
BA_ "Version" SG_ 1134 APSU_AstStRlxTiltUpDis "19.12.02";
BA_ "Description" SG_ 1134 APSU_AstStRlxTiltDnDis "This signal is used to display the seat movement to AVN";
BA_ "GenSigSendType" SG_ 1134 APSU_AstStRlxTiltDnDis 4;
BA_ "UserSigValidity" SG_ 1134 APSU_AstStRlxTiltDnDis 1;
BA_REL_ "GenSigTimeoutTime" BU_SG_REL_ CGW_CCU SG_ 1134 APSU_AstStRlxTiltDnDis 1500;
BA_ "NetworkRequest" SG_ 1134 APSU_AstStRlxTiltDnDis 0;
BA_ "NetworkRequestHoldingTime" SG_ 1134 APSU_AstStRlxTiltDnDis 5000;
BA_ "Version" SG_ 1134 APSU_AstStRlxTiltDnDis "19.12.02";
BA_ "Description" SG_ 1134 APSU_AstStCushExtBckwdDis "This signal is used to display the seat movement to AVN";
BA_ "GenSigSendType" SG_ 1134 APSU_AstStCushExtBckwdDis 4;
BA_ "UserSigValidity" SG_ 1134 APSU_AstStCushExtBckwdDis 1;
BA_ "NetworkRequest" SG_ 1134 APSU_AstStCushExtBckwdDis 0;
BA_ "NetworkRequestHoldingTime" SG_ 1134 APSU_AstStCushExtBckwdDis 5000;
BA_ "Version" SG_ 1134 APSU_AstStCushExtBckwdDis "20.11.02";
BA_ "Description" SG_ 1134 APSU_AstStCushExtFwdDis "This signal is used to display the seat movement to AVN";
BA_ "GenSigSendType" SG_ 1134 APSU_AstStCushExtFwdDis 4;
BA_ "UserSigValidity" SG_ 1134 APSU_AstStCushExtFwdDis 1;
BA_ "NetworkRequest" SG_ 1134 APSU_AstStCushExtFwdDis 0;
BA_ "NetworkRequestHoldingTime" SG_ 1134 APSU_AstStCushExtFwdDis 5000;
BA_ "Version" SG_ 1134 APSU_AstStCushExtFwdDis "20.11.02";
BA_ "Description" SG_ 1134 APSU_AstStLmbrDefDis "This signal is used to display the seat movement to AVN";
BA_ "GenSigSendType" SG_ 1134 APSU_AstStLmbrDefDis 4;
BA_ "UserSigValidity" SG_ 1134 APSU_AstStLmbrDefDis 1;
BA_REL_ "GenSigTimeoutTime" BU_SG_REL_ ALBCU SG_ 1134 APSU_AstStLmbrDefDis 1500;
BA_REL_ "GenSigTimeoutTime" BU_SG_REL_ CGW_CCU SG_ 1134 APSU_AstStLmbrDefDis 1500;
BA_ "NetworkRequest" SG_ 1134 APSU_AstStLmbrDefDis 0;
BA_ "NetworkRequestHoldingTime" SG_ 1134 APSU_AstStLmbrDefDis 5000;
BA_ "Version" SG_ 1134 APSU_AstStLmbrDefDis "18.02.01";
BA_ "Description" SG_ 1134 APSU_AstStLmbrLoDis "This signal is used to display the seat movement to AVN";
BA_ "GenSigSendType" SG_ 1134 APSU_AstStLmbrLoDis 4;
BA_ "UserSigValidity" SG_ 1134 APSU_AstStLmbrLoDis 1;
BA_REL_ "GenSigTimeoutTime" BU_SG_REL_ ALBCU SG_ 1134 APSU_AstStLmbrLoDis 1500;
BA_REL_ "GenSigTimeoutTime" BU_SG_REL_ CGW_CCU SG_ 1134 APSU_AstStLmbrLoDis 1500;
BA_ "NetworkRequest" SG_ 1134 APSU_AstStLmbrLoDis 0;
BA_ "NetworkRequestHoldingTime" SG_ 1134 APSU_AstStLmbrLoDis 5000;
BA_ "Version" SG_ 1134 APSU_AstStLmbrLoDis "18.02.01";
BA_ "Description" SG_ 1134 APSU_AstStLmbrMdlDis "This signal is used to display the seat movement to AVN";
BA_ "GenSigSendType" SG_ 1134 APSU_AstStLmbrMdlDis 4;
BA_ "UserSigValidity" SG_ 1134 APSU_AstStLmbrMdlDis 1;
BA_REL_ "GenSigTimeoutTime" BU_SG_REL_ ALBCU SG_ 1134 APSU_AstStLmbrMdlDis 1500;
BA_REL_ "GenSigTimeoutTime" BU_SG_REL_ CGW_CCU SG_ 1134 APSU_AstStLmbrMdlDis 1500;
BA_ "NetworkRequest" SG_ 1134 APSU_AstStLmbrMdlDis 0;
BA_ "NetworkRequestHoldingTime" SG_ 1134 APSU_AstStLmbrMdlDis 5000;
BA_ "Version" SG_ 1134 APSU_AstStLmbrMdlDis "18.02.01";
BA_ "Description" SG_ 1134 APSU_AstStLmbrUpDis "This signal is used to display the seat movement to AVN";
BA_ "GenSigSendType" SG_ 1134 APSU_AstStLmbrUpDis 4;
BA_ "UserSigValidity" SG_ 1134 APSU_AstStLmbrUpDis 1;
BA_REL_ "GenSigTimeoutTime" BU_SG_REL_ ALBCU SG_ 1134 APSU_AstStLmbrUpDis 1500;
BA_REL_ "GenSigTimeoutTime" BU_SG_REL_ CGW_CCU SG_ 1134 APSU_AstStLmbrUpDis 1500;
BA_ "NetworkRequest" SG_ 1134 APSU_AstStLmbrUpDis 0;
BA_ "NetworkRequestHoldingTime" SG_ 1134 APSU_AstStLmbrUpDis 5000;
BA_ "Version" SG_ 1134 APSU_AstStLmbrUpDis "18.02.01";
BA_ "Description" SG_ 1134 APSU_AstStReclneFwdDis "This signal is used to display the seat movement to AVN";
BA_ "GenSigSendType" SG_ 1134 APSU_AstStReclneFwdDis 4;
BA_ "UserSigValidity" SG_ 1134 APSU_AstStReclneFwdDis 1;
BA_REL_ "GenSigTimeoutTime" BU_SG_REL_ CGW_CCU SG_ 1134 APSU_AstStReclneFwdDis 1500;
BA_ "NetworkRequest" SG_ 1134 APSU_AstStReclneFwdDis 0;
BA_ "NetworkRequestHoldingTime" SG_ 1134 APSU_AstStReclneFwdDis 5000;
BA_ "Version" SG_ 1134 APSU_AstStReclneFwdDis "18.02.01";
BA_ "Description" SG_ 1134 APSU_LmbrSigSrcTyp "-(Old)C_APSULumbarOpt";
BA_ "GenSigSendType" SG_ 1134 APSU_LmbrSigSrcTyp 4;
BA_ "UserSigValidity" SG_ 1134 APSU_LmbrSigSrcTyp 0;
BA_REL_ "GenSigTimeoutTime" BU_SG_REL_ ALBCU SG_ 1134 APSU_LmbrSigSrcTyp 1500;
BA_ "NetworkRequest" SG_ 1134 APSU_LmbrSigSrcTyp 0;
BA_ "NetworkRequestHoldingTime" SG_ 1134 APSU_LmbrSigSrcTyp 5000;
BA_ "Version" SG_ 1134 APSU_LmbrSigSrcTyp "18.02.01";
BA_ "Description" SG_ 1134 APSU_APSUOpt "APSU Àû¿ë ¿É¼Ç ÆÇ´Ü ½ÅÈ£

APSU Option Status Information";
BA_ "GenSigSendType" SG_ 1134 APSU_APSUOpt 4;
BA_ "UserSigValidity" SG_ 1134 APSU_APSUOpt 0;
BA_REL_ "GenSigTimeoutTime" BU_SG_REL_ RLPSU SG_ 1134 APSU_APSUOpt 1500;
BA_REL_ "GenSigTimeoutTime" BU_SG_REL_ RRPSU SG_ 1134 APSU_APSUOpt 1500;
BA_ "Version" SG_ 1134 APSU_APSUOpt "20.12.04";
BA_ "Description" SG_ 1134 APSU_AstStReclneBckwdDis "This signal is used to display the seat movement to AVN";
BA_ "GenSigSendType" SG_ 1134 APSU_AstStReclneBckwdDis 4;
BA_ "UserSigValidity" SG_ 1134 APSU_AstStReclneBckwdDis 1;
BA_REL_ "GenSigTimeoutTime" BU_SG_REL_ CGW_CCU SG_ 1134 APSU_AstStReclneBckwdDis 1500;
BA_ "NetworkRequest" SG_ 1134 APSU_AstStReclneBckwdDis 0;
BA_ "NetworkRequestHoldingTime" SG_ 1134 APSU_AstStReclneBckwdDis 5000;
BA_ "Version" SG_ 1134 APSU_AstStReclneBckwdDis "18.02.01";
BA_ "Description" SG_ 1134 APSU_AstStTiltUpDis "This signal is used to display the seat movement to AVN";
BA_ "GenSigSendType" SG_ 1134 APSU_AstStTiltUpDis 4;
BA_ "UserSigValidity" SG_ 1134 APSU_AstStTiltUpDis 1;
BA_REL_ "GenSigTimeoutTime" BU_SG_REL_ CGW_CCU SG_ 1134 APSU_AstStTiltUpDis 1500;
BA_ "NetworkRequest" SG_ 1134 APSU_AstStTiltUpDis 0;
BA_ "NetworkRequestHoldingTime" SG_ 1134 APSU_AstStTiltUpDis 5000;
BA_ "Version" SG_ 1134 APSU_AstStTiltUpDis "18.02.01";
BA_ "NmStationAddress" BU_ ASAU 83;
BA_ "GenMsgCycleTime" BO_ 1095 0;
BA_ "Description" SG_ 1095 ATS_BeepSound "ATS to AMP BEEP sound trigger";
BA_ "GenSigSendType" SG_ 1095 ATS_BeepSound 4;
BA_ "UserSigValidity" SG_ 1095 ATS_BeepSound 3;
BA_REL_ "GenSigTimeoutTime" BU_SG_REL_ CGW_CCU SG_ 1095 ATS_BeepSound 0;
BA_ "RoutingFactor" SG_ 1095 ATS_BeepSound 0;
BA_ "Version" SG_ 1095 ATS_BeepSound "20.03.00";
BA_ "Description" SG_ 1095 ATS_RRMsgTimeSW "Rear Right Massage Time Button";
BA_ "GenSigSendType" SG_ 1095 ATS_RRMsgTimeSW 4;
BA_ "UserSigValidity" SG_ 1095 ATS_RRMsgTimeSW 3;
BA_ "RoutingFactor" SG_ 1095 ATS_RRMsgTimeSW 0;
BA_ "Version" SG_ 1095 ATS_RRMsgTimeSW "20.07.01";
BA_ "Description" SG_ 1095 ATS_FAUMsgModeSW "Rear Right Foot Massage Mode Button";
BA_ "GenSigSendType" SG_ 1095 ATS_FAUMsgModeSW 4;
BA_ "UserSigValidity" SG_ 1095 ATS_FAUMsgModeSW 3;
BA_REL_ "GenSigTimeoutTime" BU_SG_REL_ ASAU SG_ 1095 ATS_FAUMsgModeSW 0;
BA_ "RoutingFactor" SG_ 1095 ATS_FAUMsgModeSW 0;
BA_ "Version" SG_ 1095 ATS_FAUMsgModeSW "20.07.01";
BA_ "Description" SG_ 1095 ATS_FAUMsgHeatModeSW "Rear Right Foot Massage Heat Mode Button";
BA_ "GenSigSendType" SG_ 1095 ATS_FAUMsgHeatModeSW 4;
BA_ "UserSigValidity" SG_ 1095 ATS_FAUMsgHeatModeSW 3;
BA_REL_ "GenSigTimeoutTime" BU_SG_REL_ ASAU SG_ 1095 ATS_FAUMsgHeatModeSW 0;
BA_ "RoutingFactor" SG_ 1095 ATS_FAUMsgHeatModeSW 0;
BA_ "Version" SG_ 1095 ATS_FAUMsgHeatModeSW "20.07.01";
BA_ "Description" SG_ 1095 ATS_RLMsgMod1SW "Rear Left Massage Mode 1 Button";
BA_ "GenSigSendType" SG_ 1095 ATS_RLMsgMod1SW 4;
BA_ "UserSigValidity" SG_ 1095 ATS_RLMsgMod1SW 3;
BA_ "RoutingFactor" SG_ 1095 ATS_RLMsgMod1SW 0;
BA_ "Version" SG_ 1095 ATS_RLMsgMod1SW "20.12.05";
BA_ "NmStationAddress" BU_ RWPC 31;
BA_ "Description" SG_ 1095 ATS_RWPC_RWPCNValueSet "Rear Wireless Phone Charger ON/OFF Request";
BA_ "GenSigSendType" SG_ 1095 ATS_RWPC_RWPCNValueSet 4;
BA_ "UserSigValidity" SG_ 1095 ATS_RWPC_RWPCNValueSet 3;
BA_REL_ "GenSigTimeoutTime" BU_SG_REL_ RWPC SG_ 1095 ATS_RWPC_RWPCNValueSet 0;
BA_ "RoutingFactor" SG_ 1095 ATS_RWPC_RWPCNValueSet 0;
BA_ "Version" SG_ 1095 ATS_RWPC_RWPCNValueSet "20.03.00";
BA_ "Description" SG_ 1095 ATS_RLMsgMod2SW "Rear Left Massage Mode 2 Button";
BA_ "GenSigSendType" SG_ 1095 ATS_RLMsgMod2SW 4;
BA_ "UserSigValidity" SG_ 1095 ATS_RLMsgMod2SW 3;
BA_ "RoutingFactor" SG_ 1095 ATS_RLMsgMod2SW 0;
BA_ "Version" SG_ 1095 ATS_RLMsgMod2SW "20.12.05";
BA_ "Description" SG_ 1095 ATS_RLMsgMod3SW "Rear Left Massage Mode 3 Button";
BA_ "GenSigSendType" SG_ 1095 ATS_RLMsgMod3SW 4;
BA_ "UserSigValidity" SG_ 1095 ATS_RLMsgMod3SW 3;
BA_ "RoutingFactor" SG_ 1095 ATS_RLMsgMod3SW 0;
BA_ "Version" SG_ 1095 ATS_RLMsgMod3SW "20.12.05";
BA_ "Description" SG_ 1095 ATS_RLMsgMod4SW "Rear Left Massage Mode 4 Button";
BA_ "GenSigSendType" SG_ 1095 ATS_RLMsgMod4SW 4;
BA_ "UserSigValidity" SG_ 1095 ATS_RLMsgMod4SW 3;
BA_ "RoutingFactor" SG_ 1095 ATS_RLMsgMod4SW 0;
BA_ "Version" SG_ 1095 ATS_RLMsgMod4SW "20.12.05";
BA_ "Description" SG_ 1095 ATS_RRMsgMod1SW "Rear Right Massage Mode 1 Button";
BA_ "GenSigSendType" SG_ 1095 ATS_RRMsgMod1SW 4;
BA_ "UserSigValidity" SG_ 1095 ATS_RRMsgMod1SW 3;
BA_ "RoutingFactor" SG_ 1095 ATS_RRMsgMod1SW 0;
BA_ "Version" SG_ 1095 ATS_RRMsgMod1SW "20.12.05";
BA_ "Description" SG_ 1095 ATS_RRMsgMod2SW "Rear Right Massage Mode 2 Button";
BA_ "GenSigSendType" SG_ 1095 ATS_RRMsgMod2SW 4;
BA_ "UserSigValidity" SG_ 1095 ATS_RRMsgMod2SW 3;
BA_ "RoutingFactor" SG_ 1095 ATS_RRMsgMod2SW 0;
BA_ "Version" SG_ 1095 ATS_RRMsgMod2SW "20.12.05";
BA_ "Description" SG_ 1095 ATS_RRMsgMod3SW "Rear Right Massage Mode 3 Button";
BA_ "GenSigSendType" SG_ 1095 ATS_RRMsgMod3SW 4;
BA_ "UserSigValidity" SG_ 1095 ATS_RRMsgMod3SW 3;
BA_ "RoutingFactor" SG_ 1095 ATS_RRMsgMod3SW 0;
BA_ "Version" SG_ 1095 ATS_RRMsgMod3SW "20.12.05";
BA_ "Description" SG_ 1095 ATS_RRMsgMod4SW "Rear Right Massage Mode 4 Button";
BA_ "GenSigSendType" SG_ 1095 ATS_RRMsgMod4SW 4;
BA_ "UserSigValidity" SG_ 1095 ATS_RRMsgMod4SW 3;
BA_ "RoutingFactor" SG_ 1095 ATS_RRMsgMod4SW 0;
BA_ "Version" SG_ 1095 ATS_RRMsgMod4SW "20.12.05";
BA_ "Description" SG_ 1095 ATS_RLEasyAccessSW "ATS touch command for seat easy access (For Rear Left)";
BA_ "GenSigSendType" SG_ 1095 ATS_RLEasyAccessSW 4;
BA_ "UserSigValidity" SG_ 1095 ATS_RLEasyAccessSW 3;
BA_ "RoutingFactor" SG_ 1095 ATS_RLEasyAccessSW 0;
BA_ "Version" SG_ 1095 ATS_RLEasyAccessSW "20.05.02";
BA_ "Description" SG_ 1095 ATS_RREasyAccessSW "ATS touch command for seat easy access (For Rear Right)";
BA_ "GenSigSendType" SG_ 1095 ATS_RREasyAccessSW 4;
BA_ "UserSigValidity" SG_ 1095 ATS_RREasyAccessSW 3;
BA_ "RoutingFactor" SG_ 1095 ATS_RREasyAccessSW 0;
BA_ "Version" SG_ 1095 ATS_RREasyAccessSW "20.05.02";
BA_ "Description" SG_ 1095 ATS_RLMsgTimeSW "Rear Left Massage Time Button";
BA_ "GenSigSendType" SG_ 1095 ATS_RLMsgTimeSW 4;
BA_ "UserSigValidity" SG_ 1095 ATS_RLMsgTimeSW 3;
BA_ "RoutingFactor" SG_ 1095 ATS_RLMsgTimeSW 0;
BA_ "Version" SG_ 1095 ATS_RLMsgTimeSW "20.07.01";
BA_ "NmStationAddress" BU_ RRHV 53;
BA_ "NmStationAddress" BU_ SHVU_RR 43;
BA_ "NmStationAddress" BU_ RLHV 52;
BA_ "NmStationAddress" BU_ RCM 61;
BA_ "NmStationAddress" BU_ BLTN_CAM 72;
BA_ "NmStationAddress" BU_ SCM 7;
BA_ "NmStationAddress" BU_ DLBCU 64;
BA_ "NmStationAddress" BU_ SGU 62;
BA_ "NmStationAddress" BU_ DSAU 89;
BA_ "NmStationAddress" BU_ PFSU 45;
BA_ "NmStationAddress" BU_ WPC 30;
BA_ "GenMsgSendType" BO_ 1090 0;
BA_ "Description" SG_ 1090 BCM_Crc12Val "The data area for CRC calculation is based on the data length (DLC) of the message DB.

The CRC shall be calculated over the entire data block (excluding the CRC bytes) including the user data, alive counter and Data ID 

 

- CRC Polynomial (0x1D) , Initial Value : 0x00, XOR value : 0xFF, Data ID Mode : Both, Data ID : Message ID + 0xF800 

- The initial value is for CRC calculation and the message should be sent with the calculated result value. 

The mathematical expression to 8 bit CRC polynomial is given here. G(x) = x8 + x4 + x3 + x2 + 1";
BA_ "GenSigSendType" SG_ 1090 BCM_Crc12Val 4;
BA_ "GenSigStartValue" SG_ 1090 BCM_Crc12Val 255;
BA_ "UserSigValidity" SG_ 1090 BCM_Crc12Val 0;
BA_ "Version" SG_ 1090 BCM_Crc12Val "18.11.08";
BA_ "Description" SG_ 1090 BCM_AlvCnt12Val "For the first transmission request for a data element the counter shall be initialized with 0 and shall be incremented by 1

for every subsequent send request. When the counter reaches the maximum value(0xE), then it shall restart with 0 for the next send request";
BA_ "GenSigSendType" SG_ 1090 BCM_AlvCnt12Val 4;
BA_ "UserSigValidity" SG_ 1090 BCM_AlvCnt12Val 0;
BA_ "Version" SG_ 1090 BCM_AlvCnt12Val "18.11.08";
BA_ "Description" SG_ 1090 BCM_SmkOptTyp "-(Old)C_PICOption";
BA_ "GenSigSendType" SG_ 1090 BCM_SmkOptTyp 4;
BA_ "UserSigValidity" SG_ 1090 BCM_SmkOptTyp 0;
BA_REL_ "GenSigTimeoutTime" BU_SG_REL_ WPC SG_ 1090 BCM_SmkOptTyp 1500;
BA_REL_ "GenSigTimeoutTime" BU_SG_REL_ RWPC SG_ 1090 BCM_SmkOptTyp 1500;
BA_ "NetworkRequest" SG_ 1090 BCM_SmkOptTyp 0;
BA_ "NetworkRequestHoldingTime" SG_ 1090 BCM_SmkOptTyp 5000;
BA_ "Version" SG_ 1090 BCM_SmkOptTyp "17.12.00";
BA_ "Description" SG_ 1090 PHEV_FuelDrOpnSta "This signal means state of fuel door switch (Open/Close)



Fuel door switch located in fuel door, thus switch states means physical status of fuel door(Open/Close)







* Applied LF PHEV Fuel Door Control Workshop Result



Timeout Value



P-CAN(EMS) : 0x1, 



C-CAN(CLU) : 0x0";
BA_ "GenSigSendType" SG_ 1090 PHEV_FuelDrOpnSta 4;
BA_ "UserSigValidity" SG_ 1090 PHEV_FuelDrOpnSta 0;
BA_ "NetworkRequest" SG_ 1090 PHEV_FuelDrOpnSta 0;
BA_ "NetworkRequestHoldingTime" SG_ 1090 PHEV_FuelDrOpnSta 5000;
BA_ "Version" SG_ 1090 PHEV_FuelDrOpnSta "18.03.04";
BA_ "Description" SG_ 1090 BCM_SunRoofOptTyp "Option Signal for Sunroof system

(C_SunroofOpt)";
BA_ "GenSigSendType" SG_ 1090 BCM_SunRoofOptTyp 4;
BA_ "UserSigValidity" SG_ 1090 BCM_SunRoofOptTyp 0;
BA_REL_ "GenSigTimeoutTime" BU_SG_REL_ ATS SG_ 1090 BCM_SunRoofOptTyp 1500;
BA_ "Version" SG_ 1090 BCM_SunRoofOptTyp "18.09.00";
BA_ "GenSigSendType" SG_ 1090 Window_DrvrSdWdwSta_BCM 4;
BA_ "UserSigValidity" SG_ 1090 Window_DrvrSdWdwSta_BCM 0;
BA_ "NetworkRequest" SG_ 1090 Window_DrvrSdWdwSta_BCM 0;
BA_ "NetworkRequestHoldingTime" SG_ 1090 Window_DrvrSdWdwSta_BCM 5000;
BA_ "Version" SG_ 1090 Window_DrvrSdWdwSta_BCM "17.12.00";
BA_ "Description" SG_ 1090 Window_AsstSdWdwSta_BCM "-(Old)C_AstWdwStat";
BA_ "GenSigSendType" SG_ 1090 Window_AsstSdWdwSta_BCM 4;
BA_ "UserSigValidity" SG_ 1090 Window_AsstSdWdwSta_BCM 0;
BA_ "NetworkRequest" SG_ 1090 Window_AsstSdWdwSta_BCM 0;
BA_ "NetworkRequestHoldingTime" SG_ 1090 Window_AsstSdWdwSta_BCM 5000;
BA_ "Version" SG_ 1090 Window_AsstSdWdwSta_BCM "17.12.00";
BA_ "Description" SG_ 1090 Window_RrLftWdwSta_BCM "-(Old)C_RLWdwSta";
BA_ "GenSigSendType" SG_ 1090 Window_RrLftWdwSta_BCM 4;
BA_ "UserSigValidity" SG_ 1090 Window_RrLftWdwSta_BCM 0;
BA_REL_ "GenSigTimeoutTime" BU_SG_REL_ ATS SG_ 1090 Window_RrLftWdwSta_BCM 1500;
BA_ "NetworkRequest" SG_ 1090 Window_RrLftWdwSta_BCM 0;
BA_ "NetworkRequestHoldingTime" SG_ 1090 Window_RrLftWdwSta_BCM 5000;
BA_ "Version" SG_ 1090 Window_RrLftWdwSta_BCM "17.12.00";
BA_ "Description" SG_ 1090 Window_RrRtWdwSta_BCM "-(Old)C_RRWdwStat";
BA_ "GenSigSendType" SG_ 1090 Window_RrRtWdwSta_BCM 4;
BA_ "UserSigValidity" SG_ 1090 Window_RrRtWdwSta_BCM 0;
BA_REL_ "GenSigTimeoutTime" BU_SG_REL_ ATS SG_ 1090 Window_RrRtWdwSta_BCM 1500;
BA_ "NetworkRequest" SG_ 1090 Window_RrRtWdwSta_BCM 0;
BA_ "NetworkRequestHoldingTime" SG_ 1090 Window_RrRtWdwSta_BCM 5000;
BA_ "Version" SG_ 1090 Window_RrRtWdwSta_BCM "17.12.00";
BA_ "Description" SG_ 1090 SunRoof_GlassPosSta "This signal indicates Sunroof Glass Open/Close Status

(C_GlassPositionState)";
BA_ "GenSigSendType" SG_ 1090 SunRoof_GlassPosSta 4;
BA_ "GenSigStartValue" SG_ 1090 SunRoof_GlassPosSta 15;
BA_ "UserSigValidity" SG_ 1090 SunRoof_GlassPosSta 0;
BA_ "Version" SG_ 1090 SunRoof_GlassPosSta "18.09.00";
BA_ "Description" SG_ 1090 PHEV_FuelDrDis "PHEV Fuel Door Control CLU Display Message from BCM";
BA_ "GenSigSendType" SG_ 1090 PHEV_FuelDrDis 4;
BA_ "UserSigValidity" SG_ 1090 PHEV_FuelDrDis 0;
BA_ "NetworkRequest" SG_ 1090 PHEV_FuelDrDis 0;
BA_ "NetworkRequestHoldingTime" SG_ 1090 PHEV_FuelDrDis 5000;
BA_ "Version" SG_ 1090 PHEV_FuelDrDis "18.03.04";
BA_ "Description" SG_ 1090 SunRoof_BlindPosSta "This signal indicates Sunroof Blind Open/Close Status

(C_BlindPositionState)";
BA_ "GenSigSendType" SG_ 1090 SunRoof_BlindPosSta 4;
BA_ "GenSigStartValue" SG_ 1090 SunRoof_BlindPosSta 15;
BA_ "UserSigValidity" SG_ 1090 SunRoof_BlindPosSta 0;
BA_ "Version" SG_ 1090 SunRoof_BlindPosSta "18.09.00";
BA_ "Description" SG_ 1090 SunRoof_GlassErrSta "This signal indicates Sunroof Glass error Status

(C_GlassErrorState)";
BA_ "GenSigSendType" SG_ 1090 SunRoof_GlassErrSta 4;
BA_ "UserSigValidity" SG_ 1090 SunRoof_GlassErrSta 0;
BA_ "Version" SG_ 1090 SunRoof_GlassErrSta "18.09.00";
BA_ "Description" SG_ 1090 SunRoof_BlindErrSta "This signal indicates Sunroof Blind error Status

(C_BlindErrorState)";
BA_ "GenSigSendType" SG_ 1090 SunRoof_BlindErrSta 4;
BA_ "UserSigValidity" SG_ 1090 SunRoof_BlindErrSta 0;
BA_ "Version" SG_ 1090 SunRoof_BlindErrSta "18.09.00";
BA_ "GenMsgSendType" BO_ 1097 0;
BA_ "Description" SG_ 1097 BCM_Crc13Val "The data area for CRC calculation is based on the data length (DLC) of the message DB.

The CRC shall be calculated over the entire data block (excluding the CRC bytes) including the user data, alive counter and Data ID 

 

- CRC Polynomial (0x1D) , Initial Value : 0x00, XOR value : 0xFF, Data ID Mode : Both, Data ID : Message ID + 0xF800 

- The initial value is for CRC calculation and the message should be sent with the calculated result value. 

The mathematical expression to 8 bit CRC polynomial is given here. G(x) = x8 + x4 + x3 + x2 + 1";
BA_ "GenSigSendType" SG_ 1097 BCM_Crc13Val 4;
BA_ "GenSigStartValue" SG_ 1097 BCM_Crc13Val 255;
BA_ "UserSigValidity" SG_ 1097 BCM_Crc13Val 0;
BA_ "Version" SG_ 1097 BCM_Crc13Val "18.11.08";
BA_ "Description" SG_ 1097 BCM_AlvCnt13Val "For the first transmission request for a data element the counter shall be initialized with 0 and shall be incremented by 1

for every subsequent send request. When the counter reaches the maximum value(0xE), then it shall restart with 0 for the next send request";
BA_ "GenSigSendType" SG_ 1097 BCM_AlvCnt13Val 4;
BA_ "UserSigValidity" SG_ 1097 BCM_AlvCnt13Val 0;
BA_ "Version" SG_ 1097 BCM_AlvCnt13Val "18.11.08";
BA_ "Description" SG_ 1097 StrWhlWrmr_HtngCmd "Steering Wheel Warmer Command";
BA_ "GenSigSendType" SG_ 1097 StrWhlWrmr_HtngCmd 4;
BA_ "UserSigValidity" SG_ 1097 StrWhlWrmr_HtngCmd 0;
BA_ "NetworkRequest" SG_ 1097 StrWhlWrmr_HtngCmd 0;
BA_ "NetworkRequestHoldingTime" SG_ 1097 StrWhlWrmr_HtngCmd 5000;
BA_ "Version" SG_ 1097 StrWhlWrmr_HtngCmd "20.09.00";
BA_ "Description" SG_ 1097 StrWhlWrmr_HtngReqState "Response for Steering Wheel Warmer Request";
BA_ "GenSigSendType" SG_ 1097 StrWhlWrmr_HtngReqState 4;
BA_ "UserSigValidity" SG_ 1097 StrWhlWrmr_HtngReqState 0;
BA_REL_ "GenSigTimeoutTime" BU_SG_REL_ FCS SG_ 1097 StrWhlWrmr_HtngReqState 1500;
BA_ "NetworkRequest" SG_ 1097 StrWhlWrmr_HtngReqState 0;
BA_ "NetworkRequestHoldingTime" SG_ 1097 StrWhlWrmr_HtngReqState 5000;
BA_ "Version" SG_ 1097 StrWhlWrmr_HtngReqState "21.10.05";
BA_ "Description" SG_ 1097 StrWhlWrmr_IndCmd "Steering Wheel Warmer Indicator Command";
BA_ "GenSigSendType" SG_ 1097 StrWhlWrmr_IndCmd 4;
BA_ "UserSigValidity" SG_ 1097 StrWhlWrmr_IndCmd 0;
BA_REL_ "GenSigTimeoutTime" BU_SG_REL_ FCS SG_ 1097 StrWhlWrmr_IndCmd 1500;
BA_ "NetworkRequest" SG_ 1097 StrWhlWrmr_IndCmd 0;
BA_ "NetworkRequestHoldingTime" SG_ 1097 StrWhlWrmr_IndCmd 5000;
BA_ "Version" SG_ 1097 StrWhlWrmr_IndCmd "20.08.02";
BA_ "Description" SG_ 1097 PHEV_FuelDrCtrlFlag "This signal means that fuel door control logic is running or not.

(0x0 : Fuel Door Control Logic Not Running, 0x1 : Fuel Door Control Logic Running)



Fuel Door Control Logic determines whether fuel door opens or not

EMS refer to this signal to open FTIV.



* Applied LF PHEF Fuel Door Control WorkShop Result (141205)

Timeout Value

P-CAN(EMS) : 0x1

C-CAN(CLU) : 0x0





* Applied LF PHEV Fuel Door Control Workshop Result



Timeout Value



P-CAN(EMS) : 0x1, 



C-CAN(CLU) : 0x0";
BA_ "GenSigSendType" SG_ 1097 PHEV_FuelDrCtrlFlag 4;
BA_ "UserSigValidity" SG_ 1097 PHEV_FuelDrCtrlFlag 0;
BA_ "NetworkRequest" SG_ 1097 PHEV_FuelDrCtrlFlag 0;
BA_ "NetworkRequestHoldingTime" SG_ 1097 PHEV_FuelDrCtrlFlag 5000;
BA_ "Version" SG_ 1097 PHEV_FuelDrCtrlFlag "18.12.03";
BA_ "Description" SG_ 1097 Haptic_USMCurState_OnOff "Response for Haptic Steering Wheel Mode Status (On/Off Type)";
BA_ "GenSigSendType" SG_ 1097 Haptic_USMCurState_OnOff 4;
BA_ "UserSigValidity" SG_ 1097 Haptic_USMCurState_OnOff 0;
BA_ "NetworkRequest" SG_ 1097 Haptic_USMCurState_OnOff 0;
BA_ "NetworkRequestHoldingTime" SG_ 1097 Haptic_USMCurState_OnOff 5000;
BA_ "Version" SG_ 1097 Haptic_USMCurState_OnOff "21.03.06";
BA_ "Description" SG_ 1097 Haptic_ADASAutoOnSetReq "Request to Active Automatically for Warning of DRV Assist System";
BA_ "GenSigSendType" SG_ 1097 Haptic_ADASAutoOnSetReq 4;
BA_ "UserSigValidity" SG_ 1097 Haptic_ADASAutoOnSetReq 0;
BA_ "NetworkRequest" SG_ 1097 Haptic_ADASAutoOnSetReq 0;
BA_ "NetworkRequestHoldingTime" SG_ 1097 Haptic_ADASAutoOnSetReq 5000;
BA_ "Version" SG_ 1097 Haptic_ADASAutoOnSetReq "20.08.02";
BA_ "Description" SG_ 1097 HeatedSteerWheel_StrWhlHtrSwSta_BCM "This signal is used to sent information of current state of Steering Wheel Heated SW.";
BA_ "GenSigSendType" SG_ 1097 HeatedSteerWheel_StrWhlHtrSwSta_BCM 4;
BA_ "UserSigValidity" SG_ 1097 HeatedSteerWheel_StrWhlHtrSwSta_BCM 0;
BA_ "NetworkRequest" SG_ 1097 HeatedSteerWheel_StrWhlHtrSwSta_BCM 0;
BA_ "NetworkRequestHoldingTime" SG_ 1097 HeatedSteerWheel_StrWhlHtrSwSta_BCM 5000;
BA_ "Version" SG_ 1097 HeatedSteerWheel_StrWhlHtrSwSta_BCM "17.12.00";
BA_ "Description" SG_ 1097 Haptic_WrngCmd "Haptic Motor Command";
BA_ "GenSigSendType" SG_ 1097 Haptic_WrngCmd 4;
BA_ "UserSigValidity" SG_ 1097 Haptic_WrngCmd 0;
BA_ "NetworkRequest" SG_ 1097 Haptic_WrngCmd 0;
BA_ "NetworkRequestHoldingTime" SG_ 1097 Haptic_WrngCmd 5000;
BA_ "Version" SG_ 1097 Haptic_WrngCmd "21.10.05";
BA_ "NmNode" BU_ vDummy_HS_B 0;
BA_ "GenMsgCycleTime" BO_ 2202063617 0;
BA_ "VFrameFormat" BO_ 2202063617 1;
BA_ "Description" SG_ 2202063617 CCU_AP_OTA_Crc4Val "The data area for CRC calculation is based on the data length (DLC) of the message DB.

The CRC shall be calculated over the entire data block (excluding the CRC bytes) including the user data, alive counter and Data ID

 

- CRC Polynomial (0x1021) , Initial Value : 0xFFFF, XOR value : 0x0000, Data ID : Message ID + 0xF800 

- The initial value is for CRC calculation and the message should be sent with the calculated result value. 

- The mathematical expression to 16 bit CRC polynomial is given here. G(x) = x16 + x12 + x5 + 1";
BA_ "GenSigSendType" SG_ 2202063617 CCU_AP_OTA_Crc4Val 4;
BA_ "GenSigStartValue" SG_ 2202063617 CCU_AP_OTA_Crc4Val 65535;
BA_ "UserSigValidity" SG_ 2202063617 CCU_AP_OTA_Crc4Val 3;
BA_REL_ "GenSigTimeoutTime" BU_SG_REL_ vDummy_HS_B SG_ 2202063617 CCU_AP_OTA_Crc4Val 0;
BA_ "Version" SG_ 2202063617 CCU_AP_OTA_Crc4Val "19.12.07";
BA_ "Description" SG_ 2202063617 CCU_AP_OTA_AlvCnt4Val "For the first transmission request for a data element the counter shall be initialized with 0 and shall be incremented by 1 for every subsequent send request. 

When the counter reaches the maximum value(0xFF), then it shall restart with 0 for the next send request";
BA_ "GenSigSendType" SG_ 2202063617 CCU_AP_OTA_AlvCnt4Val 4;
BA_ "UserSigValidity" SG_ 2202063617 CCU_AP_OTA_AlvCnt4Val 3;
BA_REL_ "GenSigTimeoutTime" BU_SG_REL_ vDummy_HS_B SG_ 2202063617 CCU_AP_OTA_AlvCnt4Val 0;
BA_ "Version" SG_ 2202063617 CCU_AP_OTA_AlvCnt4Val "19.12.07";
BA_ "Description" SG_ 2202063617 CCU_OTA_Update_time "¾÷µ¥ÀÌÆ® ¿¹»ó½Ã°£";
BA_ "GenSigSendType" SG_ 2202063617 CCU_OTA_Update_time 4;
BA_ "UserSigValidity" SG_ 2202063617 CCU_OTA_Update_time 0;
BA_ "Version" SG_ 2202063617 CCU_OTA_Update_time "19.12.08";
BA_ "Description" SG_ 2202063617 CCU_OTA_Update_Current "¾÷µ¥ÀÌÆ®½Ã Ãß°¡ ¼Ò¸ðÀü·ù";
BA_ "GenSigSendType" SG_ 2202063617 CCU_OTA_Update_Current 4;
BA_ "UserSigValidity" SG_ 2202063617 CCU_OTA_Update_Current 0;
BA_ "Version" SG_ 2202063617 CCU_OTA_Update_Current "19.12.08";
BA_ "GenSigSendType" SG_ 2202063617 CCU_Update_Calfactor 4;
BA_ "UserSigValidity" SG_ 2202063617 CCU_Update_Calfactor 0;
BA_ "Version" SG_ 2202063617 CCU_Update_Calfactor "19.12.07";
BA_ "NmStationAddress" BU_ EMCU 17;
BA_ "NmStationAddress" BU_ RCS 70;
BA_ "GenMsgSendType" BO_ 2395189505 0;
BA_ "VFrameFormat" BO_ 2395189505 1;
BA_ "Description" SG_ 2395189505 DATC_Crc9Val "The data area for CRC calculation is based on the data length (DLC) of the message DB.

The CRC shall be calculated over the entire data block (excluding the CRC bytes) including the user data, alive counter and Data ID

 

- CRC Polynomial (0x1021) , Initial Value : 0xFFFF, XOR value : 0x0000, Data ID : Message ID + 0xF800 

- The initial value is for CRC calculation and the message should be sent with the calculated result value. 

- The mathematical expression to 16 bit CRC polynomial is given here. G(x) = x16 + x12 + x5 + 1";
BA_ "GenSigSendType" SG_ 2395189505 DATC_Crc9Val 4;
BA_ "GenSigStartValue" SG_ 2395189505 DATC_Crc9Val 65535;
BA_ "UserSigValidity" SG_ 2395189505 DATC_Crc9Val 3;
BA_ "Version" SG_ 2395189505 DATC_Crc9Val "18.11.08";
BA_ "Description" SG_ 2395189505 DATC_AlvCnt9Val "For the first transmission request for a data element the counter shall be initialized with 0 and shall be incremented by 1 for every subsequent send request. 

When the counter reaches the maximum value(0xFF), then it shall restart with 0 for the next send request";
BA_ "GenSigSendType" SG_ 2395189505 DATC_AlvCnt9Val 4;
BA_ "UserSigValidity" SG_ 2395189505 DATC_AlvCnt9Val 3;
BA_ "Version" SG_ 2395189505 DATC_AlvCnt9Val "18.11.08";
BA_ "Description" SG_ 2395189505 DATC_FragranceStrhSta "This signal indicate frangrance strength state";
BA_ "GenSigSendType" SG_ 2395189505 DATC_FragranceStrhSta 4;
BA_ "UserSigValidity" SG_ 2395189505 DATC_FragranceStrhSta 7;
BA_REL_ "GenSigTimeoutTime" BU_SG_REL_ ATS SG_ 2395189505 DATC_FragranceStrhSta 1500;
BA_ "Version" SG_ 2395189505 DATC_FragranceStrhSta "20.03.00";
BA_ "Description" SG_ 2395189505 DATC_FragranceKindSta "This signal indicate fragrance kind state.";
BA_ "GenSigSendType" SG_ 2395189505 DATC_FragranceKindSta 4;
BA_ "UserSigValidity" SG_ 2395189505 DATC_FragranceKindSta 7;
BA_REL_ "GenSigTimeoutTime" BU_SG_REL_ ATS SG_ 2395189505 DATC_FragranceKindSta 1500;
BA_ "Version" SG_ 2395189505 DATC_FragranceKindSta "20.03.00";
BA_ "Description" SG_ 2395189505 DATC_AfterBlowOpSta "Operating Status of AfterBlow";
BA_ "GenSigSendType" SG_ 2395189505 DATC_AfterBlowOpSta 4;
BA_ "UserSigValidity" SG_ 2395189505 DATC_AfterBlowOpSta 7;
BA_ "Version" SG_ 2395189505 DATC_AfterBlowOpSta "20.09.00";
BA_ "GenSigSendType" SG_ 2395189505 DATC_RrBlwDis 4;
BA_ "UserSigValidity" SG_ 2395189505 DATC_RrBlwDis 7;
BA_REL_ "GenSigTimeoutTime" BU_SG_REL_ ATS SG_ 2395189505 DATC_RrBlwDis 1500;
BA_ "Version" SG_ 2395189505 DATC_RrBlwDis "19.05.04";
BA_ "Description" SG_ 2395189505 DATC_RrClmtAutoOffUSMSta "This signal indicate Rear Climate Auto Off USM State.";
BA_ "GenSigSendType" SG_ 2395189505 DATC_RrClmtAutoOffUSMSta 4;
BA_ "UserSigValidity" SG_ 2395189505 DATC_RrClmtAutoOffUSMSta 7;
BA_ "Version" SG_ 2395189505 DATC_RrClmtAutoOffUSMSta "20.12.04";
BA_ "Description" SG_ 2395189505 DATC_ArClnSysOSD "This signal indicate the feature of OSD POP UP about Air Cleaning System.";
BA_ "GenSigSendType" SG_ 2395189505 DATC_ArClnSysOSD 4;
BA_ "UserSigValidity" SG_ 2395189505 DATC_ArClnSysOSD 7;
BA_ "Version" SG_ 2395189505 DATC_ArClnSysOSD "19.08.01";
BA_ "Description" SG_ 2395189505 DATC_ArClnStepClr "This signal indicate the information about Color of AirCleaning Symbol displaying in the AVN";
BA_ "GenSigSendType" SG_ 2395189505 DATC_ArClnStepClr 4;
BA_ "UserSigValidity" SG_ 2395189505 DATC_ArClnStepClr 7;
BA_REL_ "GenSigTimeoutTime" BU_SG_REL_ ATS SG_ 2395189505 DATC_ArClnStepClr 1500;
BA_ "Version" SG_ 2395189505 DATC_ArClnStepClr "19.02.03";
BA_ "Description" SG_ 2395189505 DATC_ArClnSmblTyp "This signal indicate the feature of Air Cleaning Symbol displaying in AVN";
BA_ "GenSigSendType" SG_ 2395189505 DATC_ArClnSmblTyp 4;
BA_ "UserSigValidity" SG_ 2395189505 DATC_ArClnSmblTyp 7;
BA_REL_ "GenSigTimeoutTime" BU_SG_REL_ ATS SG_ 2395189505 DATC_ArClnSmblTyp 1500;
BA_ "Version" SG_ 2395189505 DATC_ArClnSmblTyp "18.12.08";
BA_ "Description" SG_ 2395189505 DATC_AfterBlowUSMSta "This signal indicate activation status of USM setting menu about After Blow.";
BA_ "GenSigSendType" SG_ 2395189505 DATC_AfterBlowUSMSta 4;
BA_ "UserSigValidity" SG_ 2395189505 DATC_AfterBlowUSMSta 7;
BA_ "Version" SG_ 2395189505 DATC_AfterBlowUSMSta "19.10.06";
BA_ "Description" SG_ 2395189505 DATC_SchdldVntUSMSta "This signal indicate activation status of USM setting menu about Scheduled Ventilation";
BA_ "GenSigSendType" SG_ 2395189505 DATC_SchdldVntUSMSta 4;
BA_ "UserSigValidity" SG_ 2395189505 DATC_SchdldVntUSMSta 7;
BA_ "Version" SG_ 2395189505 DATC_SchdldVntUSMSta "19.08.08";
BA_ "Description" SG_ 2395189505 DATC_SchdldVntHrSta "This signal indicates the value corresponding to 'hour' among the set time values of the scheduled ventilation USM";
BA_ "GenSigSendType" SG_ 2395189505 DATC_SchdldVntHrSta 4;
BA_ "UserSigValidity" SG_ 2395189505 DATC_SchdldVntHrSta 7;
BA_ "Version" SG_ 2395189505 DATC_SchdldVntHrSta "19.08.08";
BA_ "Description" SG_ 2395189505 DATC_SchdldVntMinSta "This signal indicates the value corresponding to 'minutes' among the set time values of the scheduled ventilation USM.";
BA_ "GenSigSendType" SG_ 2395189505 DATC_SchdldVntMinSta 4;
BA_ "UserSigValidity" SG_ 2395189505 DATC_SchdldVntMinSta 7;
BA_ "Version" SG_ 2395189505 DATC_SchdldVntMinSta "19.08.08";
BA_ "GenMsgSendType" BO_ 1130 0;
BA_ "Description" SG_ 1130 DLBCU_LumbarUpDis "This signal is used to display the seat movement to AVN";
BA_ "GenSigSendType" SG_ 1130 DLBCU_LumbarUpDis 4;
BA_ "UserSigValidity" SG_ 1130 DLBCU_LumbarUpDis 1;
BA_REL_ "GenSigTimeoutTime" BU_SG_REL_ DPSU SG_ 1130 DLBCU_LumbarUpDis 1500;
BA_REL_ "GenSigTimeoutTime" BU_SG_REL_ CGW_CCU SG_ 1130 DLBCU_LumbarUpDis 1500;
BA_ "NetworkRequest" SG_ 1130 DLBCU_LumbarUpDis 0;
BA_ "NetworkRequestHoldingTime" SG_ 1130 DLBCU_LumbarUpDis 5000;
BA_ "Version" SG_ 1130 DLBCU_LumbarUpDis "18.03.07";
BA_ "Description" SG_ 1130 DLBCU_LumbarMidDis "This signal is used to display the seat movement to AVN";
BA_ "GenSigSendType" SG_ 1130 DLBCU_LumbarMidDis 4;
BA_ "UserSigValidity" SG_ 1130 DLBCU_LumbarMidDis 1;
BA_REL_ "GenSigTimeoutTime" BU_SG_REL_ DPSU SG_ 1130 DLBCU_LumbarMidDis 1500;
BA_REL_ "GenSigTimeoutTime" BU_SG_REL_ CGW_CCU SG_ 1130 DLBCU_LumbarMidDis 1500;
BA_ "NetworkRequest" SG_ 1130 DLBCU_LumbarMidDis 0;
BA_ "NetworkRequestHoldingTime" SG_ 1130 DLBCU_LumbarMidDis 5000;
BA_ "Version" SG_ 1130 DLBCU_LumbarMidDis "18.03.07";
BA_ "Description" SG_ 1130 DLBCU_LumbarLowDis "This signal is used to display the seat movement to AVN";
BA_ "GenSigSendType" SG_ 1130 DLBCU_LumbarLowDis 4;
BA_ "UserSigValidity" SG_ 1130 DLBCU_LumbarLowDis 1;
BA_REL_ "GenSigTimeoutTime" BU_SG_REL_ DPSU SG_ 1130 DLBCU_LumbarLowDis 1500;
BA_REL_ "GenSigTimeoutTime" BU_SG_REL_ CGW_CCU SG_ 1130 DLBCU_LumbarLowDis 1500;
BA_ "NetworkRequest" SG_ 1130 DLBCU_LumbarLowDis 0;
BA_ "NetworkRequestHoldingTime" SG_ 1130 DLBCU_LumbarLowDis 5000;
BA_ "Version" SG_ 1130 DLBCU_LumbarLowDis "18.03.07";
BA_ "Description" SG_ 1130 DLBCU_LumbarDefDis "This signal is used to display the seat movement to AVN";
BA_ "GenSigSendType" SG_ 1130 DLBCU_LumbarDefDis 4;
BA_ "UserSigValidity" SG_ 1130 DLBCU_LumbarDefDis 1;
BA_REL_ "GenSigTimeoutTime" BU_SG_REL_ DPSU SG_ 1130 DLBCU_LumbarDefDis 1500;
BA_REL_ "GenSigTimeoutTime" BU_SG_REL_ CGW_CCU SG_ 1130 DLBCU_LumbarDefDis 1500;
BA_ "NetworkRequest" SG_ 1130 DLBCU_LumbarDefDis 0;
BA_ "NetworkRequestHoldingTime" SG_ 1130 DLBCU_LumbarDefDis 5000;
BA_ "Version" SG_ 1130 DLBCU_LumbarDefDis "18.03.07";
BA_ "GenMsgSendType" BO_ 1131 0;
BA_ "Description" SG_ 1131 DLBCU_BolsterInfDis "This signal is used to display the seat movement to AVN";
BA_ "GenSigSendType" SG_ 1131 DLBCU_BolsterInfDis 4;
BA_ "UserSigValidity" SG_ 1131 DLBCU_BolsterInfDis 1;
BA_REL_ "GenSigTimeoutTime" BU_SG_REL_ DPSU SG_ 1131 DLBCU_BolsterInfDis 1500;
BA_REL_ "GenSigTimeoutTime" BU_SG_REL_ CGW_CCU SG_ 1131 DLBCU_BolsterInfDis 1500;
BA_ "NetworkRequest" SG_ 1131 DLBCU_BolsterInfDis 0;
BA_ "NetworkRequestHoldingTime" SG_ 1131 DLBCU_BolsterInfDis 5000;
BA_ "Version" SG_ 1131 DLBCU_BolsterInfDis "18.03.07";
BA_ "Description" SG_ 1131 DLBCU_BolsterDefDis "This signal is used to display the seat movement to AVN";
BA_ "GenSigSendType" SG_ 1131 DLBCU_BolsterDefDis 4;
BA_ "UserSigValidity" SG_ 1131 DLBCU_BolsterDefDis 1;
BA_REL_ "GenSigTimeoutTime" BU_SG_REL_ DPSU SG_ 1131 DLBCU_BolsterDefDis 1500;
BA_REL_ "GenSigTimeoutTime" BU_SG_REL_ CGW_CCU SG_ 1131 DLBCU_BolsterDefDis 1500;
BA_ "NetworkRequest" SG_ 1131 DLBCU_BolsterDefDis 0;
BA_ "NetworkRequestHoldingTime" SG_ 1131 DLBCU_BolsterDefDis 5000;
BA_ "Version" SG_ 1131 DLBCU_BolsterDefDis "18.03.07";
BA_ "GenMsgSendType" BO_ 1132 0;
BA_ "Description" SG_ 1132 DLBCU_CushInfDis "This signal is used to display the seat movement to AVN";
BA_ "GenSigSendType" SG_ 1132 DLBCU_CushInfDis 4;
BA_ "UserSigValidity" SG_ 1132 DLBCU_CushInfDis 1;
BA_REL_ "GenSigTimeoutTime" BU_SG_REL_ DPSU SG_ 1132 DLBCU_CushInfDis 1500;
BA_REL_ "GenSigTimeoutTime" BU_SG_REL_ CGW_CCU SG_ 1132 DLBCU_CushInfDis 1500;
BA_ "NetworkRequest" SG_ 1132 DLBCU_CushInfDis 0;
BA_ "NetworkRequestHoldingTime" SG_ 1132 DLBCU_CushInfDis 5000;
BA_ "Version" SG_ 1132 DLBCU_CushInfDis "18.03.07";
BA_ "Description" SG_ 1132 DLBCU_CushDefDis "This signal is used to display the seat movement to AVN";
BA_ "GenSigSendType" SG_ 1132 DLBCU_CushDefDis 4;
BA_ "UserSigValidity" SG_ 1132 DLBCU_CushDefDis 1;
BA_REL_ "GenSigTimeoutTime" BU_SG_REL_ DPSU SG_ 1132 DLBCU_CushDefDis 1500;
BA_REL_ "GenSigTimeoutTime" BU_SG_REL_ CGW_CCU SG_ 1132 DLBCU_CushDefDis 1500;
BA_ "NetworkRequest" SG_ 1132 DLBCU_CushDefDis 0;
BA_ "NetworkRequestHoldingTime" SG_ 1132 DLBCU_CushDefDis 5000;
BA_ "Version" SG_ 1132 DLBCU_CushDefDis "18.03.07";
BA_ "GenMsgSendType" BO_ 1127 0;
BA_ "Description" SG_ 1127 DPSS_Crc1Val "The data area for CRC calculation is based on the data length (DLC) of the message DB.

The CRC shall be calculated over the entire data block (excluding the CRC bytes) including the user data, alive counter and Data ID 

 

- CRC Polynomial (0x1D) , Initial Value : 0x00, XOR value : 0xFF, Data ID Mode : Both, Data ID : Message ID + 0xF800 

- The initial value is for CRC calculation and the message should be sent with the calculated result value. 

The mathematical expression to 8 bit CRC polynomial is given here. G(x) = x8 + x4 + x3 + x2 + 1";
BA_ "GenSigSendType" SG_ 1127 DPSS_Crc1Val 4;
BA_ "UserSigValidity" SG_ 1127 DPSS_Crc1Val 0;
BA_ "Version" SG_ 1127 DPSS_Crc1Val "21.09.03";
BA_ "Description" SG_ 1127 DPSS_AlvCnt1Val "For the first transmission request for a data element the counter shall be initialized with 0 and shall be incremented by 1

for every subsequent send request. When the counter reaches the maximum value(0xE), then it shall restart with 0 for the next send request";
BA_ "GenSigSendType" SG_ 1127 DPSS_AlvCnt1Val 4;
BA_ "UserSigValidity" SG_ 1127 DPSS_AlvCnt1Val 0;
BA_ "Version" SG_ 1127 DPSS_AlvCnt1Val "21.09.03";
BA_ "Description" SG_ 1127 DPSS_StExtFwdMvBtn "¿îÀü¼® Äí¼Ç ÀÍ½ºÅÙ¼Ç Æ÷¿öµå ¹öÆ°";
BA_ "GenSigSendType" SG_ 1127 DPSS_StExtFwdMvBtn 4;
BA_ "UserSigValidity" SG_ 1127 DPSS_StExtFwdMvBtn 0;
BA_ "NetworkRequest" SG_ 1127 DPSS_StExtFwdMvBtn 0;
BA_ "NetworkRequestHoldingTime" SG_ 1127 DPSS_StExtFwdMvBtn 5000;
BA_ "Version" SG_ 1127 DPSS_StExtFwdMvBtn "20.03.01";
BA_ "Description" SG_ 1127 DPSS_StExtBwdMvBtn "¿îÀü¼® Äí¼Ç ÀÍ½ºÅÙ¼Ç ¹é¿öµå ¹öÆ°";
BA_ "GenSigSendType" SG_ 1127 DPSS_StExtBwdMvBtn 4;
BA_ "UserSigValidity" SG_ 1127 DPSS_StExtBwdMvBtn 0;
BA_ "NetworkRequest" SG_ 1127 DPSS_StExtBwdMvBtn 0;
BA_ "NetworkRequestHoldingTime" SG_ 1127 DPSS_StExtBwdMvBtn 5000;
BA_ "Version" SG_ 1127 DPSS_StExtBwdMvBtn "20.03.01";
BA_ "Description" SG_ 1127 DPSS_StSldFwdMvBtn "¿îÀü¼® ½½¶óÀÌµå Æ÷¿öµå ¹öÆ°";
BA_ "GenSigSendType" SG_ 1127 DPSS_StSldFwdMvBtn 4;
BA_ "UserSigValidity" SG_ 1127 DPSS_StSldFwdMvBtn 0;
BA_ "NetworkRequest" SG_ 1127 DPSS_StSldFwdMvBtn 0;
BA_ "NetworkRequestHoldingTime" SG_ 1127 DPSS_StSldFwdMvBtn 5000;
BA_ "Version" SG_ 1127 DPSS_StSldFwdMvBtn "20.03.01";
BA_ "Description" SG_ 1127 DPSS_StSldBwdMvBtn "¿îÀü¼® ½½¶óÀÌµå ¹é¿öµå ¹öÆ°";
BA_ "GenSigSendType" SG_ 1127 DPSS_StSldBwdMvBtn 4;
BA_ "UserSigValidity" SG_ 1127 DPSS_StSldBwdMvBtn 0;
BA_ "NetworkRequest" SG_ 1127 DPSS_StSldBwdMvBtn 0;
BA_ "NetworkRequestHoldingTime" SG_ 1127 DPSS_StSldBwdMvBtn 5000;
BA_ "Version" SG_ 1127 DPSS_StSldBwdMvBtn "20.03.01";
BA_ "Description" SG_ 1127 DPSS_StRclFwdMvBtn "¿îÀü¼® ¸®Å¬¶óÀÌ³Ê Æ÷¿öµå ¹öÆ°";
BA_ "GenSigSendType" SG_ 1127 DPSS_StRclFwdMvBtn 4;
BA_ "UserSigValidity" SG_ 1127 DPSS_StRclFwdMvBtn 0;
BA_ "NetworkRequest" SG_ 1127 DPSS_StRclFwdMvBtn 0;
BA_ "NetworkRequestHoldingTime" SG_ 1127 DPSS_StRclFwdMvBtn 5000;
BA_ "Version" SG_ 1127 DPSS_StRclFwdMvBtn "20.03.01";
BA_ "Description" SG_ 1127 DPSS_StRclBwdMvBtn "¿îÀü¼® ¸®Å¬¶óÀÌ³Ê ¹é¿öµå ¹öÆ°";
BA_ "GenSigSendType" SG_ 1127 DPSS_StRclBwdMvBtn 4;
BA_ "UserSigValidity" SG_ 1127 DPSS_StRclBwdMvBtn 0;
BA_ "NetworkRequest" SG_ 1127 DPSS_StRclBwdMvBtn 0;
BA_ "NetworkRequestHoldingTime" SG_ 1127 DPSS_StRclBwdMvBtn 5000;
BA_ "Version" SG_ 1127 DPSS_StRclBwdMvBtn "20.03.01";
BA_ "Description" SG_ 1127 DPSS_StHgtUpMvBtn "¿îÀü¼® ÇÏÀÌÆ® ¾÷ ¹öÆ°";
BA_ "GenSigSendType" SG_ 1127 DPSS_StHgtUpMvBtn 4;
BA_ "UserSigValidity" SG_ 1127 DPSS_StHgtUpMvBtn 0;
BA_ "NetworkRequest" SG_ 1127 DPSS_StHgtUpMvBtn 0;
BA_ "NetworkRequestHoldingTime" SG_ 1127 DPSS_StHgtUpMvBtn 5000;
BA_ "Version" SG_ 1127 DPSS_StHgtUpMvBtn "20.03.01";
BA_ "Description" SG_ 1127 DPSS_StHgtDnMvBtn "¿îÀü¼® ÇÏÀÌÆ® ´Ù¿î ¹öÆ°";
BA_ "GenSigSendType" SG_ 1127 DPSS_StHgtDnMvBtn 4;
BA_ "UserSigValidity" SG_ 1127 DPSS_StHgtDnMvBtn 0;
BA_ "NetworkRequest" SG_ 1127 DPSS_StHgtDnMvBtn 0;
BA_ "NetworkRequestHoldingTime" SG_ 1127 DPSS_StHgtDnMvBtn 5000;
BA_ "Version" SG_ 1127 DPSS_StHgtDnMvBtn "20.03.01";
BA_ "Description" SG_ 1127 DPSS_StTltUpMvBtn "¿îÀü¼® Æ¿Æ® ¾÷ ¹öÆ°";
BA_ "GenSigSendType" SG_ 1127 DPSS_StTltUpMvBtn 4;
BA_ "UserSigValidity" SG_ 1127 DPSS_StTltUpMvBtn 0;
BA_ "NetworkRequest" SG_ 1127 DPSS_StTltUpMvBtn 0;
BA_ "NetworkRequestHoldingTime" SG_ 1127 DPSS_StTltUpMvBtn 5000;
BA_ "Version" SG_ 1127 DPSS_StTltUpMvBtn "20.03.01";
BA_ "Description" SG_ 1127 DPSS_StTltDnMvBtn "¿îÀü¼® Æ¿Æ® ´Ù¿î ¹öÆ°";
BA_ "GenSigSendType" SG_ 1127 DPSS_StTltDnMvBtn 4;
BA_ "UserSigValidity" SG_ 1127 DPSS_StTltDnMvBtn 0;
BA_ "NetworkRequest" SG_ 1127 DPSS_StTltDnMvBtn 0;
BA_ "NetworkRequestHoldingTime" SG_ 1127 DPSS_StTltDnMvBtn 5000;
BA_ "Version" SG_ 1127 DPSS_StTltDnMvBtn "20.03.01";
BA_ "Description" SG_ 1127 DPSS_StHRestUpMvBtn "¿îÀü¼® Çìµå·¹½ºÆ® UP ¹öÆ°";
BA_ "GenSigSendType" SG_ 1127 DPSS_StHRestUpMvBtn 4;
BA_ "UserSigValidity" SG_ 1127 DPSS_StHRestUpMvBtn 0;
BA_ "NetworkRequest" SG_ 1127 DPSS_StHRestUpMvBtn 0;
BA_ "NetworkRequestHoldingTime" SG_ 1127 DPSS_StHRestUpMvBtn 5000;
BA_ "Version" SG_ 1127 DPSS_StHRestUpMvBtn "20.03.01";
BA_ "Description" SG_ 1127 DPSS_StHRestDnMvBtn "¿îÀü¼® Çìµå·¹½ºÆ® DOWN ¹öÆ°";
BA_ "GenSigSendType" SG_ 1127 DPSS_StHRestDnMvBtn 4;
BA_ "UserSigValidity" SG_ 1127 DPSS_StHRestDnMvBtn 0;
BA_ "NetworkRequest" SG_ 1127 DPSS_StHRestDnMvBtn 0;
BA_ "NetworkRequestHoldingTime" SG_ 1127 DPSS_StHRestDnMvBtn 5000;
BA_ "Version" SG_ 1127 DPSS_StHRestDnMvBtn "20.03.01";
BA_ "Description" SG_ 1127 DPSS_StHRestFwdMvBtn "¿îÀü¼® Çìµå·¹½ºÆ® FWD ¹öÆ°";
BA_ "GenSigSendType" SG_ 1127 DPSS_StHRestFwdMvBtn 4;
BA_ "UserSigValidity" SG_ 1127 DPSS_StHRestFwdMvBtn 0;
BA_ "NetworkRequest" SG_ 1127 DPSS_StHRestFwdMvBtn 0;
BA_ "NetworkRequestHoldingTime" SG_ 1127 DPSS_StHRestFwdMvBtn 5000;
BA_ "Version" SG_ 1127 DPSS_StHRestFwdMvBtn "20.03.01";
BA_ "Description" SG_ 1127 DPSS_StHRestBwdMvBtn "¿îÀü¼® Çìµå·¹½ºÆ® BWD ¹öÆ°";
BA_ "GenSigSendType" SG_ 1127 DPSS_StHRestBwdMvBtn 4;
BA_ "UserSigValidity" SG_ 1127 DPSS_StHRestBwdMvBtn 0;
BA_ "NetworkRequest" SG_ 1127 DPSS_StHRestBwdMvBtn 0;
BA_ "NetworkRequestHoldingTime" SG_ 1127 DPSS_StHRestBwdMvBtn 5000;
BA_ "Version" SG_ 1127 DPSS_StHRestBwdMvBtn "20.03.01";
BA_ "Description" SG_ 1127 DPSS_StLegUpMvBtn "¿îÀü¼® ·¹±×·¹½ºÆ® ¾÷ ¹öÆ°";
BA_ "GenSigSendType" SG_ 1127 DPSS_StLegUpMvBtn 4;
BA_ "UserSigValidity" SG_ 1127 DPSS_StLegUpMvBtn 0;
BA_ "NetworkRequest" SG_ 1127 DPSS_StLegUpMvBtn 0;
BA_ "NetworkRequestHoldingTime" SG_ 1127 DPSS_StLegUpMvBtn 5000;
BA_ "Version" SG_ 1127 DPSS_StLegUpMvBtn "20.03.01";
BA_ "Description" SG_ 1127 DPSS_StLegDnMvBtn "¿îÀü¼® ·¹±×·¹½ºÆ® ´Ù¿î ¹öÆ°";
BA_ "GenSigSendType" SG_ 1127 DPSS_StLegDnMvBtn 4;
BA_ "UserSigValidity" SG_ 1127 DPSS_StLegDnMvBtn 0;
BA_ "NetworkRequest" SG_ 1127 DPSS_StLegDnMvBtn 0;
BA_ "NetworkRequestHoldingTime" SG_ 1127 DPSS_StLegDnMvBtn 5000;
BA_ "Version" SG_ 1127 DPSS_StLegDnMvBtn "20.03.01";
BA_ "Description" SG_ 1127 DPSS_StRlxModeBtn "¿îÀü¼® ¸±·º½º ¸ðµå ¹öÆ°";
BA_ "GenSigSendType" SG_ 1127 DPSS_StRlxModeBtn 4;
BA_ "UserSigValidity" SG_ 1127 DPSS_StRlxModeBtn 0;
BA_ "NetworkRequest" SG_ 1127 DPSS_StRlxModeBtn 0;
BA_ "NetworkRequestHoldingTime" SG_ 1127 DPSS_StRlxModeBtn 5000;
BA_ "Version" SG_ 1127 DPSS_StRlxModeBtn "20.03.01";
BA_ "Description" SG_ 1127 DPSS_StRlxReturnBtn "¿îÀü¼® ¸±·º½º ¸®ÅÏ ¹öÆ°";
BA_ "GenSigSendType" SG_ 1127 DPSS_StRlxReturnBtn 4;
BA_ "UserSigValidity" SG_ 1127 DPSS_StRlxReturnBtn 0;
BA_ "NetworkRequest" SG_ 1127 DPSS_StRlxReturnBtn 0;
BA_ "NetworkRequestHoldingTime" SG_ 1127 DPSS_StRlxReturnBtn 5000;
BA_ "Version" SG_ 1127 DPSS_StRlxReturnBtn "20.03.01";
BA_ "Description" SG_ 1127 DPSS_StRlxTltUpMvBtn "¿îÀü¼® ¸±·º½º Æ¿Æ® ¾÷ ¹öÆ°";
BA_ "GenSigSendType" SG_ 1127 DPSS_StRlxTltUpMvBtn 4;
BA_ "UserSigValidity" SG_ 1127 DPSS_StRlxTltUpMvBtn 0;
BA_ "NetworkRequest" SG_ 1127 DPSS_StRlxTltUpMvBtn 0;
BA_ "NetworkRequestHoldingTime" SG_ 1127 DPSS_StRlxTltUpMvBtn 5000;
BA_ "Version" SG_ 1127 DPSS_StRlxTltUpMvBtn "21.11.01";
BA_ "Description" SG_ 1127 DPSS_StRlxTltDnMvBtn "¿îÀü¼® ¸±·º½º Æ¿Æ® ´Ù¿î ¹öÆ°";
BA_ "GenSigSendType" SG_ 1127 DPSS_StRlxTltDnMvBtn 4;
BA_ "UserSigValidity" SG_ 1127 DPSS_StRlxTltDnMvBtn 0;
BA_ "NetworkRequest" SG_ 1127 DPSS_StRlxTltDnMvBtn 0;
BA_ "NetworkRequestHoldingTime" SG_ 1127 DPSS_StRlxTltDnMvBtn 5000;
BA_ "Version" SG_ 1127 DPSS_StRlxTltDnMvBtn "21.11.01";
BA_ "GenMsgSendType" BO_ 1128 0;
BA_ "Description" SG_ 1128 DPSS_Crc2Val "The data area for CRC calculation is based on the data length (DLC) of the message DB.

The CRC shall be calculated over the entire data block (excluding the CRC bytes) including the user data, alive counter and Data ID 

 

- CRC Polynomial (0x1D) , Initial Value : 0x00, XOR value : 0xFF, Data ID Mode : Both, Data ID : Message ID + 0xF800 

- The initial value is for CRC calculation and the message should be sent with the calculated result value. 

The mathematical expression to 8 bit CRC polynomial is given here. G(x) = x8 + x4 + x3 + x2 + 1";
BA_ "GenSigSendType" SG_ 1128 DPSS_Crc2Val 4;
BA_ "GenSigStartValue" SG_ 1128 DPSS_Crc2Val 255;
BA_ "UserSigValidity" SG_ 1128 DPSS_Crc2Val 0;
BA_REL_ "GenSigTimeoutTime" BU_SG_REL_ DLBCU SG_ 1128 DPSS_Crc2Val 1500;
BA_ "Version" SG_ 1128 DPSS_Crc2Val "19.01.01";
BA_ "Description" SG_ 1128 DPSS_AlvCnt2Val "For the first transmission request for a data element the counter shall be initialized with 0 and shall be incremented by 1

for every subsequent send request. When the counter reaches the maximum value(0xE), then it shall restart with 0 for the next send request";
BA_ "GenSigSendType" SG_ 1128 DPSS_AlvCnt2Val 4;
BA_ "UserSigValidity" SG_ 1128 DPSS_AlvCnt2Val 0;
BA_REL_ "GenSigTimeoutTime" BU_SG_REL_ DLBCU SG_ 1128 DPSS_AlvCnt2Val 1500;
BA_ "Version" SG_ 1128 DPSS_AlvCnt2Val "19.01.01";
BA_ "Description" SG_ 1128 DPSS_LumbarUpSw "¿îÀü¼® ·³¹ö ¾÷ ½ºÀ§Ä¡";
BA_ "GenSigSendType" SG_ 1128 DPSS_LumbarUpSw 4;
BA_ "UserSigValidity" SG_ 1128 DPSS_LumbarUpSw 0;
BA_REL_ "GenSigTimeoutTime" BU_SG_REL_ DLBCU SG_ 1128 DPSS_LumbarUpSw 1500;
BA_ "NetworkRequest" SG_ 1128 DPSS_LumbarUpSw 0;
BA_ "NetworkRequestHoldingTime" SG_ 1128 DPSS_LumbarUpSw 5000;
BA_ "Version" SG_ 1128 DPSS_LumbarUpSw "20.03.01";
BA_ "Description" SG_ 1128 DPSS_LumbarMidSw "¿îÀü¼® ·³¹ö ¹Ìµé ½ºÀ§Ä¡";
BA_ "GenSigSendType" SG_ 1128 DPSS_LumbarMidSw 4;
BA_ "UserSigValidity" SG_ 1128 DPSS_LumbarMidSw 0;
BA_REL_ "GenSigTimeoutTime" BU_SG_REL_ DLBCU SG_ 1128 DPSS_LumbarMidSw 1500;
BA_ "NetworkRequest" SG_ 1128 DPSS_LumbarMidSw 0;
BA_ "NetworkRequestHoldingTime" SG_ 1128 DPSS_LumbarMidSw 5000;
BA_ "Version" SG_ 1128 DPSS_LumbarMidSw "20.03.01";
BA_ "Description" SG_ 1128 DPSS_LumbarLowSw "¿îÀü¼® ·³¹ö ÇÏ´Ü ¹öÆ°";
BA_ "GenSigSendType" SG_ 1128 DPSS_LumbarLowSw 4;
BA_ "UserSigValidity" SG_ 1128 DPSS_LumbarLowSw 0;
BA_REL_ "GenSigTimeoutTime" BU_SG_REL_ DLBCU SG_ 1128 DPSS_LumbarLowSw 1500;
BA_ "NetworkRequest" SG_ 1128 DPSS_LumbarLowSw 0;
BA_ "NetworkRequestHoldingTime" SG_ 1128 DPSS_LumbarLowSw 5000;
BA_ "Version" SG_ 1128 DPSS_LumbarLowSw "20.03.01";
BA_ "Description" SG_ 1128 DPSS_LumbarDefSw "¿îÀü¼® ·³¹ö µðÇÃ·¹ÀÌ¼Ç ¹öÆ°";
BA_ "GenSigSendType" SG_ 1128 DPSS_LumbarDefSw 4;
BA_ "UserSigValidity" SG_ 1128 DPSS_LumbarDefSw 0;
BA_REL_ "GenSigTimeoutTime" BU_SG_REL_ DLBCU SG_ 1128 DPSS_LumbarDefSw 1500;
BA_ "NetworkRequest" SG_ 1128 DPSS_LumbarDefSw 0;
BA_ "NetworkRequestHoldingTime" SG_ 1128 DPSS_LumbarDefSw 5000;
BA_ "Version" SG_ 1128 DPSS_LumbarDefSw "20.03.01";
BA_ "Description" SG_ 1128 DPSS_BolsterInfSw "¿îÀü¼® º¼½ºÅÍ Èí±â ¹öÆ°";
BA_ "GenSigSendType" SG_ 1128 DPSS_BolsterInfSw 4;
BA_ "UserSigValidity" SG_ 1128 DPSS_BolsterInfSw 0;
BA_REL_ "GenSigTimeoutTime" BU_SG_REL_ DLBCU SG_ 1128 DPSS_BolsterInfSw 1500;
BA_ "NetworkRequest" SG_ 1128 DPSS_BolsterInfSw 0;
BA_ "NetworkRequestHoldingTime" SG_ 1128 DPSS_BolsterInfSw 5000;
BA_ "Version" SG_ 1128 DPSS_BolsterInfSw "20.03.01";
BA_ "Description" SG_ 1128 DPSS_BolsterDefSw "¿îÀü¼® º¼½ºÅÍ ¹è±â ¹öÆ°";
BA_ "GenSigSendType" SG_ 1128 DPSS_BolsterDefSw 4;
BA_ "UserSigValidity" SG_ 1128 DPSS_BolsterDefSw 0;
BA_REL_ "GenSigTimeoutTime" BU_SG_REL_ DLBCU SG_ 1128 DPSS_BolsterDefSw 1500;
BA_ "NetworkRequest" SG_ 1128 DPSS_BolsterDefSw 0;
BA_ "NetworkRequestHoldingTime" SG_ 1128 DPSS_BolsterDefSw 5000;
BA_ "Version" SG_ 1128 DPSS_BolsterDefSw "20.03.01";
BA_ "Description" SG_ 1128 DPSS_ActiveSw "¿îÀü¼® Äí¼Ç º¼½ºÅÍ Á¶Àý ½ºÀ§Ä¡";
BA_ "GenSigSendType" SG_ 1128 DPSS_ActiveSw 4;
BA_ "UserSigValidity" SG_ 1128 DPSS_ActiveSw 0;
BA_REL_ "GenSigTimeoutTime" BU_SG_REL_ DLBCU SG_ 1128 DPSS_ActiveSw 1500;
BA_ "NetworkRequest" SG_ 1128 DPSS_ActiveSw 0;
BA_ "NetworkRequestHoldingTime" SG_ 1128 DPSS_ActiveSw 5000;
BA_ "Version" SG_ 1128 DPSS_ActiveSw "20.03.01";
BA_ "Description" SG_ 1128 DPSS_CushInfSw "¿îÀü¼® Äí¼Ç°ø¾ÐÁ¶Àý Èí±â ¹öÆ°";
BA_ "GenSigSendType" SG_ 1128 DPSS_CushInfSw 4;
BA_ "UserSigValidity" SG_ 1128 DPSS_CushInfSw 0;
BA_REL_ "GenSigTimeoutTime" BU_SG_REL_ DLBCU SG_ 1128 DPSS_CushInfSw 1500;
BA_ "NetworkRequest" SG_ 1128 DPSS_CushInfSw 0;
BA_ "NetworkRequestHoldingTime" SG_ 1128 DPSS_CushInfSw 5000;
BA_ "Version" SG_ 1128 DPSS_CushInfSw "20.03.01";
BA_ "Description" SG_ 1128 DPSS_CushDefSw "¿îÀü¼® Äí¼Ç °ø¾Ð Á¶Àý ¹è±â ¹öÆ°";
BA_ "GenSigSendType" SG_ 1128 DPSS_CushDefSw 4;
BA_ "UserSigValidity" SG_ 1128 DPSS_CushDefSw 0;
BA_REL_ "GenSigTimeoutTime" BU_SG_REL_ DLBCU SG_ 1128 DPSS_CushDefSw 1500;
BA_ "NetworkRequest" SG_ 1128 DPSS_CushDefSw 0;
BA_ "NetworkRequestHoldingTime" SG_ 1128 DPSS_CushDefSw 5000;
BA_ "Version" SG_ 1128 DPSS_CushDefSw "20.03.01";
BA_ "GenMsgSendType" BO_ 1129 0;
BA_ "Description" SG_ 1129 DPSS_Crc3Val "The data area for CRC calculation is based on the data length (DLC) of the message DB.

The CRC shall be calculated over the entire data block (excluding the CRC bytes) including the user data, alive counter and Data ID 

 

- CRC Polynomial (0x1D) , Initial Value : 0x00, XOR value : 0xFF, Data ID Mode : Both, Data ID : Message ID + 0xF800 

- The initial value is for CRC calculation and the message should be sent with the calculated result value. 

The mathematical expression to 8 bit CRC polynomial is given here. G(x) = x8 + x4 + x3 + x2 + 1";
BA_ "GenSigSendType" SG_ 1129 DPSS_Crc3Val 4;
BA_ "GenSigStartValue" SG_ 1129 DPSS_Crc3Val 255;
BA_ "UserSigValidity" SG_ 1129 DPSS_Crc3Val 3;
BA_REL_ "GenSigTimeoutTime" BU_SG_REL_ CGW_CCU SG_ 1129 DPSS_Crc3Val 1500;
BA_ "Version" SG_ 1129 DPSS_Crc3Val "19.01.01";
BA_ "Description" SG_ 1129 DPSS_AlvCnt3Val "For the first transmission request for a data element the counter shall be initialized with 0 and shall be incremented by 1

for every subsequent send request. When the counter reaches the maximum value(0xE), then it shall restart with 0 for the next send request";
BA_ "GenSigSendType" SG_ 1129 DPSS_AlvCnt3Val 4;
BA_ "UserSigValidity" SG_ 1129 DPSS_AlvCnt3Val 3;
BA_ "Version" SG_ 1129 DPSS_AlvCnt3Val "19.01.01";
BA_ "Description" SG_ 1129 DPSS_SldTch "ÅÍÄ¡ ½ºÀ§Ä¡ Á¤º¸";
BA_ "GenSigSendType" SG_ 1129 DPSS_SldTch 4;
BA_ "UserSigValidity" SG_ 1129 DPSS_SldTch 3;
BA_REL_ "GenSigTimeoutTime" BU_SG_REL_ CGW_CCU SG_ 1129 DPSS_SldTch 1500;
BA_ "NetworkRequest" SG_ 1129 DPSS_SldTch 0;
BA_ "NetworkRequestHoldingTime" SG_ 1129 DPSS_SldTch 5000;
BA_ "Version" SG_ 1129 DPSS_SldTch "19.01.01";
BA_ "Description" SG_ 1129 DPSS_RclTch "ÅÍÄ¡ ½ºÀ§Ä¡ Á¤º¸";
BA_ "GenSigSendType" SG_ 1129 DPSS_RclTch 4;
BA_ "UserSigValidity" SG_ 1129 DPSS_RclTch 3;
BA_REL_ "GenSigTimeoutTime" BU_SG_REL_ CGW_CCU SG_ 1129 DPSS_RclTch 1500;
BA_ "NetworkRequest" SG_ 1129 DPSS_RclTch 0;
BA_ "NetworkRequestHoldingTime" SG_ 1129 DPSS_RclTch 5000;
BA_ "Version" SG_ 1129 DPSS_RclTch "19.01.01";
BA_ "Description" SG_ 1129 DPSS_ExtTch "ÅÍÄ¡ ½ºÀ§Ä¡ Á¤º¸";
BA_ "GenSigSendType" SG_ 1129 DPSS_ExtTch 4;
BA_ "UserSigValidity" SG_ 1129 DPSS_ExtTch 3;
BA_REL_ "GenSigTimeoutTime" BU_SG_REL_ CGW_CCU SG_ 1129 DPSS_ExtTch 1500;
BA_ "NetworkRequest" SG_ 1129 DPSS_ExtTch 0;
BA_ "NetworkRequestHoldingTime" SG_ 1129 DPSS_ExtTch 5000;
BA_ "Version" SG_ 1129 DPSS_ExtTch "19.01.01";
BA_ "Description" SG_ 1129 DPSS_LmbrTch "ÅÍÄ¡ ½ºÀ§Ä¡ Á¤º¸";
BA_ "GenSigSendType" SG_ 1129 DPSS_LmbrTch 4;
BA_ "UserSigValidity" SG_ 1129 DPSS_LmbrTch 3;
BA_REL_ "GenSigTimeoutTime" BU_SG_REL_ CGW_CCU SG_ 1129 DPSS_LmbrTch 1500;
BA_ "NetworkRequest" SG_ 1129 DPSS_LmbrTch 0;
BA_ "NetworkRequestHoldingTime" SG_ 1129 DPSS_LmbrTch 5000;
BA_ "Version" SG_ 1129 DPSS_LmbrTch "19.01.01";
BA_ "Description" SG_ 1129 DPSS_CushOnOffTch "ÅÍÄ¡ ½ºÀ§Ä¡ Á¤º¸";
BA_ "GenSigSendType" SG_ 1129 DPSS_CushOnOffTch 4;
BA_ "UserSigValidity" SG_ 1129 DPSS_CushOnOffTch 3;
BA_REL_ "GenSigTimeoutTime" BU_SG_REL_ CGW_CCU SG_ 1129 DPSS_CushOnOffTch 1500;
BA_ "NetworkRequest" SG_ 1129 DPSS_CushOnOffTch 0;
BA_ "NetworkRequestHoldingTime" SG_ 1129 DPSS_CushOnOffTch 5000;
BA_ "Version" SG_ 1129 DPSS_CushOnOffTch "19.09.00";
BA_ "Description" SG_ 1129 DPSS_HRestTch "Çìµå·¹½ºÆ® ½ºÀ§Ä¡ ÅÍÄ¡ Á¤º¸";
BA_ "GenSigSendType" SG_ 1129 DPSS_HRestTch 4;
BA_ "UserSigValidity" SG_ 1129 DPSS_HRestTch 3;
BA_REL_ "GenSigTimeoutTime" BU_SG_REL_ CGW_CCU SG_ 1129 DPSS_HRestTch 1500;
BA_ "NetworkRequest" SG_ 1129 DPSS_HRestTch 0;
BA_ "NetworkRequestHoldingTime" SG_ 1129 DPSS_HRestTch 5000;
BA_ "Version" SG_ 1129 DPSS_HRestTch "19.11.09";
BA_ "Description" SG_ 1129 DPSS_RelaxTch "ÅÍÄ¡ ½ºÀ§Ä¡ Á¤º¸";
BA_ "GenSigSendType" SG_ 1129 DPSS_RelaxTch 4;
BA_ "UserSigValidity" SG_ 1129 DPSS_RelaxTch 3;
BA_REL_ "GenSigTimeoutTime" BU_SG_REL_ CGW_CCU SG_ 1129 DPSS_RelaxTch 1500;
BA_ "NetworkRequest" SG_ 1129 DPSS_RelaxTch 0;
BA_ "NetworkRequestHoldingTime" SG_ 1129 DPSS_RelaxTch 5000;
BA_ "Version" SG_ 1129 DPSS_RelaxTch "21.07.05";
BA_ "GenMsgSendType" BO_ 1105 0;
BA_ "GenSigSendType" SG_ 1105 FCS_FrLftStClrSwSta 4;
BA_ "UserSigValidity" SG_ 1105 FCS_FrLftStClrSwSta 7;
BA_REL_ "GenSigTimeoutTime" BU_SG_REL_ APSU SG_ 1105 FCS_FrLftStClrSwSta 1500;
BA_REL_ "GenSigTimeoutTime" BU_SG_REL_ SHVU_FR SG_ 1105 FCS_FrLftStClrSwSta 1500;
BA_ "NetworkRequest" SG_ 1105 FCS_FrLftStClrSwSta 0;
BA_ "NetworkRequestHoldingTime" SG_ 1105 FCS_FrLftStClrSwSta 5000;
BA_ "Version" SG_ 1105 FCS_FrLftStClrSwSta "19.11.05";
BA_ "GenSigSendType" SG_ 1105 HeatedSteerWheel_SwSta 4;
BA_ "UserSigValidity" SG_ 1105 HeatedSteerWheel_SwSta 7;
BA_REL_ "GenSigTimeoutTime" BU_SG_REL_ CGW_CCU SG_ 1105 HeatedSteerWheel_SwSta 1500;
BA_ "NetworkRequest" SG_ 1105 HeatedSteerWheel_SwSta 0;
BA_ "NetworkRequestHoldingTime" SG_ 1105 HeatedSteerWheel_SwSta 5000;
BA_ "Version" SG_ 1105 HeatedSteerWheel_SwSta "19.11.05";
BA_ "Description" SG_ 1105 FCS_DrvDrAtClsSwSta "FCS_DriveDoorAutoClosingSwitchStatus";
BA_ "GenSigSendType" SG_ 1105 FCS_DrvDrAtClsSwSta 4;
BA_ "UserSigValidity" SG_ 1105 FCS_DrvDrAtClsSwSta 0;
BA_REL_ "GenSigTimeoutTime" BU_SG_REL_ SHVU_FR SG_ 1105 FCS_DrvDrAtClsSwSta 1500;
BA_REL_ "GenSigTimeoutTime" BU_SG_REL_ CGW_CCU SG_ 1105 FCS_DrvDrAtClsSwSta 1500;
BA_ "NetworkRequest" SG_ 1105 FCS_DrvDrAtClsSwSta 0;
BA_ "NetworkRequestHoldingTime" SG_ 1105 FCS_DrvDrAtClsSwSta 5000;
BA_ "Version" SG_ 1105 FCS_DrvDrAtClsSwSta "19.11.05";
BA_ "Description" SG_ 1105 FCS_AstDrAtClsSwSta "FCS_AssistDoorAutoClosingSwitchStatus";
BA_ "GenSigSendType" SG_ 1105 FCS_AstDrAtClsSwSta 4;
BA_ "UserSigValidity" SG_ 1105 FCS_AstDrAtClsSwSta 0;
BA_REL_ "GenSigTimeoutTime" BU_SG_REL_ SHVU_FR SG_ 1105 FCS_AstDrAtClsSwSta 1500;
BA_REL_ "GenSigTimeoutTime" BU_SG_REL_ CGW_CCU SG_ 1105 FCS_AstDrAtClsSwSta 1500;
BA_ "NetworkRequest" SG_ 1105 FCS_AstDrAtClsSwSta 0;
BA_ "NetworkRequestHoldingTime" SG_ 1105 FCS_AstDrAtClsSwSta 5000;
BA_ "Version" SG_ 1105 FCS_AstDrAtClsSwSta "19.11.05";
BA_ "Description" SG_ 1105 FCS_DrvModeSwSta "FCS_DriveModeSwitchStatus";
BA_ "GenSigSendType" SG_ 1105 FCS_DrvModeSwSta 4;
BA_ "UserSigValidity" SG_ 1105 FCS_DrvModeSwSta 3;
BA_REL_ "GenSigTimeoutTime" BU_SG_REL_ SHVU_FR SG_ 1105 FCS_DrvModeSwSta 1500;
BA_REL_ "GenSigTimeoutTime" BU_SG_REL_ CGW_CCU SG_ 1105 FCS_DrvModeSwSta 1500;
BA_ "NetworkRequest" SG_ 1105 FCS_DrvModeSwSta 0;
BA_ "NetworkRequestHoldingTime" SG_ 1105 FCS_DrvModeSwSta 5000;
BA_ "Version" SG_ 1105 FCS_DrvModeSwSta "19.11.05";
BA_ "Description" SG_ 1105 FCS_PDWSwSta "FCS_ParkingAssistSystemSwitchStatus";
BA_ "GenSigSendType" SG_ 1105 FCS_PDWSwSta 4;
BA_ "UserSigValidity" SG_ 1105 FCS_PDWSwSta 3;
BA_REL_ "GenSigTimeoutTime" BU_SG_REL_ CGW_CCU SG_ 1105 FCS_PDWSwSta 1500;
BA_ "NetworkRequest" SG_ 1105 FCS_PDWSwSta 0;
BA_ "NetworkRequestHoldingTime" SG_ 1105 FCS_PDWSwSta 5000;
BA_ "Version" SG_ 1105 FCS_PDWSwSta "19.11.05";
BA_ "GenSigSendType" SG_ 1105 FCS_FrLftStHtrSwSta 4;
BA_ "UserSigValidity" SG_ 1105 FCS_FrLftStHtrSwSta 7;
BA_REL_ "GenSigTimeoutTime" BU_SG_REL_ APSU SG_ 1105 FCS_FrLftStHtrSwSta 1500;
BA_REL_ "GenSigTimeoutTime" BU_SG_REL_ SHVU_FR SG_ 1105 FCS_FrLftStHtrSwSta 1500;
BA_ "NetworkRequest" SG_ 1105 FCS_FrLftStHtrSwSta 0;
BA_ "NetworkRequestHoldingTime" SG_ 1105 FCS_FrLftStHtrSwSta 5000;
BA_ "Version" SG_ 1105 FCS_FrLftStHtrSwSta "19.11.05";
BA_ "Description" SG_ 1105 FCS_Beep1Sound "Play floor console thouch switch beep sound";
BA_ "GenSigSendType" SG_ 1105 FCS_Beep1Sound 4;
BA_ "UserSigValidity" SG_ 1105 FCS_Beep1Sound 3;
BA_REL_ "GenSigTimeoutTime" BU_SG_REL_ CGW_CCU SG_ 1105 FCS_Beep1Sound 1500;
BA_ "NetworkRequest" SG_ 1105 FCS_Beep1Sound 0;
BA_ "NetworkRequestHoldingTime" SG_ 1105 FCS_Beep1Sound 5000;
BA_ "Version" SG_ 1105 FCS_Beep1Sound "20.12.02";
BA_ "Description" SG_ 1105 FCS_LockTrayMsgDisp "This signal indicates ATS message displacement of Lock tray password settings.";
BA_ "GenSigSendType" SG_ 1105 FCS_LockTrayMsgDisp 4;
BA_ "UserSigValidity" SG_ 1105 FCS_LockTrayMsgDisp 1;
BA_REL_ "GenSigTimeoutTime" BU_SG_REL_ ATS SG_ 1105 FCS_LockTrayMsgDisp 1500;
BA_ "Version" SG_ 1105 FCS_LockTrayMsgDisp "21.01.02";
BA_ "Description" SG_ 1105 FCS_LockTrayStatDisp "This signal indicate ATS state displacement of Lock tray present conditions.";
BA_ "GenSigSendType" SG_ 1105 FCS_LockTrayStatDisp 4;
BA_ "UserSigValidity" SG_ 1105 FCS_LockTrayStatDisp 1;
BA_REL_ "GenSigTimeoutTime" BU_SG_REL_ ATS SG_ 1105 FCS_LockTrayStatDisp 1500;
BA_ "Version" SG_ 1105 FCS_LockTrayStatDisp "21.01.02";
BA_ "Description" SG_ 1105 FCS_LockTrayPwNoDisp "This signal indicate ATS input password state of Lock tray password number.";
BA_ "GenSigSendType" SG_ 1105 FCS_LockTrayPwNoDisp 4;
BA_ "UserSigValidity" SG_ 1105 FCS_LockTrayPwNoDisp 1;
BA_REL_ "GenSigTimeoutTime" BU_SG_REL_ ATS SG_ 1105 FCS_LockTrayPwNoDisp 1500;
BA_ "Version" SG_ 1105 FCS_LockTrayPwNoDisp "21.01.06";
BA_ "Description" SG_ 1105 FCS_LockTrayTxtPopupReq "This signal indicate ATS OSD of Lock tray text pop-up request on.";
BA_ "GenSigSendType" SG_ 1105 FCS_LockTrayTxtPopupReq 4;
BA_ "UserSigValidity" SG_ 1105 FCS_LockTrayTxtPopupReq 1;
BA_REL_ "GenSigTimeoutTime" BU_SG_REL_ ATS SG_ 1105 FCS_LockTrayTxtPopupReq 1500;
BA_ "Version" SG_ 1105 FCS_LockTrayTxtPopupReq "21.01.02";
BA_ "Description" SG_ 1105 FCS_LockTrayOSD "This signal indicate ATS OSD of Locktray text message when event done.";
BA_ "GenSigSendType" SG_ 1105 FCS_LockTrayOSD 4;
BA_ "UserSigValidity" SG_ 1105 FCS_LockTrayOSD 1;
BA_REL_ "GenSigTimeoutTime" BU_SG_REL_ ATS SG_ 1105 FCS_LockTrayOSD 1500;
BA_ "Version" SG_ 1105 FCS_LockTrayOSD "21.01.02";
BA_ "GenSigSendType" SG_ 1105 FCS_FrRtStClrSwSta 4;
BA_ "UserSigValidity" SG_ 1105 FCS_FrRtStClrSwSta 7;
BA_REL_ "GenSigTimeoutTime" BU_SG_REL_ APSU SG_ 1105 FCS_FrRtStClrSwSta 1500;
BA_REL_ "GenSigTimeoutTime" BU_SG_REL_ SHVU_FR SG_ 1105 FCS_FrRtStClrSwSta 1500;
BA_ "NetworkRequest" SG_ 1105 FCS_FrRtStClrSwSta 0;
BA_ "NetworkRequestHoldingTime" SG_ 1105 FCS_FrRtStClrSwSta 5000;
BA_ "Version" SG_ 1105 FCS_FrRtStClrSwSta "19.11.05";
BA_ "GenSigSendType" SG_ 1105 FCS_FrRtStHtrSwSta 4;
BA_ "UserSigValidity" SG_ 1105 FCS_FrRtStHtrSwSta 7;
BA_REL_ "GenSigTimeoutTime" BU_SG_REL_ APSU SG_ 1105 FCS_FrRtStHtrSwSta 1500;
BA_REL_ "GenSigTimeoutTime" BU_SG_REL_ SHVU_FR SG_ 1105 FCS_FrRtStHtrSwSta 1500;
BA_ "NetworkRequest" SG_ 1105 FCS_FrRtStHtrSwSta 0;
BA_ "NetworkRequestHoldingTime" SG_ 1105 FCS_FrRtStHtrSwSta 5000;
BA_ "Version" SG_ 1105 FCS_FrRtStHtrSwSta "19.11.05";
BA_ "GenSigSendType" SG_ 1105 FCS_RrCurtainSwSta 4;
BA_ "UserSigValidity" SG_ 1105 FCS_RrCurtainSwSta 7;
BA_ "NetworkRequest" SG_ 1105 FCS_RrCurtainSwSta 0;
BA_ "NetworkRequestHoldingTime" SG_ 1105 FCS_RrCurtainSwSta 5000;
BA_ "Version" SG_ 1105 FCS_RrCurtainSwSta "19.11.05";
BA_ "GenMsgSendType" BO_ 2378399489 0;
BA_ "GenMsgCycleTime" BO_ 2378399489 100;
BA_ "GenMsgCycleTimeFast" BO_ 2378399489 0;
BA_ "GenMsgNrOfRepetition" BO_ 2378399489 0;
BA_ "VFrameFormat" BO_ 2378399489 1;
BA_ "NmNode" BU_ vHS_B2 0;
BA_ "Description" SG_ 2378399489 GATEWAY_CrcVal "The data area for CRC calculation is based on the data length (DLC) of the message DB.

The CRC shall be calculated over the entire data block (excluding the CRC bytes) including the user data, alive counter and Data ID 

 

- CRC Polynomial (0x1D) , Initial Value : 0x00, XOR value : 0xFF, Data ID Mode : Both, Data ID : Message ID + 0xF800 

- The initial value is for CRC calculation and the message should be sent with the calculated result value. 

The mathematical expression to 8 bit CRC polynomial is given here. G(x) = x8 + x4 + x3 + x2 + 1";
BA_ "GenSigStartValue" SG_ 2378399489 GATEWAY_CrcVal 255;
BA_ "UserSigValidity" SG_ 2378399489 GATEWAY_CrcVal 0;
BA_REL_ "GenSigTimeoutTime" BU_SG_REL_ vHS_B2 SG_ 2378399489 GATEWAY_CrcVal 1500;
BA_ "Version" SG_ 2378399489 GATEWAY_CrcVal "18.11.08";
BA_ "Description" SG_ 2378399489 GATEWAY_AlvCntVal "For the first transmission request for a data element the counter shall be initialized with 0 and shall be incremented by 1

for every subsequent send request. When the counter reaches the maximum value(0xE), then it shall restart with 0 for the next send request";
BA_ "UserSigValidity" SG_ 2378399489 GATEWAY_AlvCntVal 0;
BA_ "Version" SG_ 2378399489 GATEWAY_AlvCntVal "18.11.08";
BA_ "UserSigValidity" SG_ 2378399489 GATEWAY_HS_B1_STS 0;
BA_REL_ "GenSigTimeoutTime" BU_SG_REL_ vHS_B2 SG_ 2378399489 GATEWAY_HS_B1_STS 1500;
BA_ "Version" SG_ 2378399489 GATEWAY_HS_B1_STS "21.06.12";
BA_ "UserSigValidity" SG_ 2378399489 GATEWAY_HS_B2_STS 0;
BA_REL_ "GenSigTimeoutTime" BU_SG_REL_ vHS_B2 SG_ 2378399489 GATEWAY_HS_B2_STS 1500;
BA_ "Version" SG_ 2378399489 GATEWAY_HS_B2_STS "21.06.12";
BA_ "UserSigValidity" SG_ 2378399489 GATEWAY_HS_D_STS 0;
BA_REL_ "GenSigTimeoutTime" BU_SG_REL_ vHS_B2 SG_ 2378399489 GATEWAY_HS_D_STS 1500;
BA_ "Version" SG_ 2378399489 GATEWAY_HS_D_STS "19.01.12";
BA_ "UserSigValidity" SG_ 2378399489 GATEWAY_HS_I_STS 0;
BA_ "Version" SG_ 2378399489 GATEWAY_HS_I_STS "17.11.00";
BA_ "UserSigValidity" SG_ 2378399489 GATEWAY_HS_M_STS 0;
BA_ "Version" SG_ 2378399489 GATEWAY_HS_M_STS "21.06.12";
BA_ "UserSigValidity" SG_ 2378399489 GATEWAY_FD_C_STS 0;
BA_ "Version" SG_ 2378399489 GATEWAY_FD_C_STS "17.11.00";
BA_ "UserSigValidity" SG_ 2378399489 GATEWAY_FD_P1_STS 0;
BA_ "Version" SG_ 2378399489 GATEWAY_FD_P1_STS "21.06.12";
BA_ "UserSigValidity" SG_ 2378399489 GATEWAY_FD_P2_STS 0;
BA_ "Version" SG_ 2378399489 GATEWAY_FD_P2_STS "21.06.12";
BA_ "UserSigValidity" SG_ 2378399489 GATEWAY_FD_E_STS 0;
BA_ "Version" SG_ 2378399489 GATEWAY_FD_E_STS "17.11.00";
BA_ "UserSigValidity" SG_ 2378399489 GATEWAY_FD_I_STS 0;
BA_REL_ "GenSigTimeoutTime" BU_SG_REL_ vHS_B2 SG_ 2378399489 GATEWAY_FD_I_STS 1500;
BA_ "Version" SG_ 2378399489 GATEWAY_FD_I_STS "20.03.01";
BA_ "NmStationAddress" BU_ SLB 27;
BA_ "GenMsgSendType" BO_ 2449771009 0;
BA_ "GenMsgCycleTime" BO_ 2449771009 1000;
BA_ "GenMsgCycleTimeFast" BO_ 2449771009 0;
BA_ "GenMsgNrOfRepetition" BO_ 2449771009 0;
BA_ "VFrameFormat" BO_ 2449771009 1;
BA_ "Description" SG_ 2449771009 ODS_Crc1Val "The data area for CRC calculation is based on the data length (DLC) of the message DB.

The CRC shall be calculated over the entire data block (excluding the CRC bytes) including the user data, alive counter and Data ID

 

- CRC Polynomial (0x1021) , Initial Value : 0xFFFF, XOR value : 0x0000, Data ID : Message ID + 0xF800 

- The initial value is for CRC calculation and the message should be sent with the calculated result value. 

- The mathematical expression to 16 bit CRC polynomial is given here. G(x) = x16 + x12 + x5 + 1";
BA_ "GenSigStartValue" SG_ 2449771009 ODS_Crc1Val 65535;
BA_ "UserSigValidity" SG_ 2449771009 ODS_Crc1Val 3;
BA_ "Version" SG_ 2449771009 ODS_Crc1Val "18.11.08";
BA_ "Description" SG_ 2449771009 ODS_AlvCnt1Val "For the first transmission request for a data element the counter shall be initialized with 0 and shall be incremented by 1 for every subsequent send request. 

When the counter reaches the maximum value(0xFF), then it shall restart with 0 for the next send request";
BA_ "UserSigValidity" SG_ 2449771009 ODS_AlvCnt1Val 3;
BA_ "Version" SG_ 2449771009 ODS_AlvCnt1Val "18.11.08";
BA_ "Description" SG_ 2449771009 ODS_IdVal "Information of Vehicle seat ID as defined by customer.



¡Ø Initial Value °ª(0x0) ¹«½Ã (Àü»ê ½Ã½ºÅÛ µî·Ï Â÷ ÀÓÀÇ·Î 0x0°ª µî·Ï)

: Initial(Start) Value : Current Value";
BA_ "UserSigValidity" SG_ 2449771009 ODS_IdVal 3;
BA_ "Version" SG_ 2449771009 ODS_IdVal "17.12.02";
BA_ "Description" SG_ 2449771009 ODS_OccClassSta "Signal Value Table : reference with ODS Communiction instruction";
BA_ "GenSigStartValue" SG_ 2449771009 ODS_OccClassSta 4;
BA_ "UserSigValidity" SG_ 2449771009 ODS_OccClassSta 3;
BA_REL_ "GenSigTimeoutTime" BU_SG_REL_ APSU SG_ 2449771009 ODS_OccClassSta 5000;
BA_REL_ "GenSigTimeoutTime" BU_SG_REL_ DPSU SG_ 2449771009 ODS_OccClassSta 5000;
BA_REL_ "GenSigTimeoutTime" BU_SG_REL_ ATS SG_ 2449771009 ODS_OccClassSta 5000;
BA_ "Version" SG_ 2449771009 ODS_OccClassSta "17.12.02";
BA_ "Description" SG_ 2449771009 ODS_DiagSta "CR_WCS_Errstat signal describes PODS-G & BOSE system error that is diagnosed by itself. Each Type set Diagnostic Status explains 3 kinds of fault.

[PODS-G]

Bit 1 : If ODS Have some errors, ODS set the bit, sends the ALR Defect signal to ACU and notifies the fault.

Bit 2 : If ODS Have some errors, ODS set the bit, sends the ECU Defect signal to ACU and notifies the fault.

Bit 5 : If ODS Have some errors, ODS set the bit, sends the EOL Error signal to ACU and notifies the fault.



[BOSE]

Bit 1 : If ODS Have some errors, ODS set the bit, sends the Mat Defect signal to ACU and notifies the fault.

Bit 2 : If ODS Have some errors, ODS set the bit, sends the ECU Defect signal to ACU and notifies the fault.

Bit 6 : If ODS Have some errors, ODS set the bit, sends the Algo Cut-off Error signal to ACU and notifies the fault.";
BA_ "UserSigValidity" SG_ 2449771009 ODS_DiagSta 3;
BA_ "Version" SG_ 2449771009 ODS_DiagSta "17.12.02";
BA_ "Description" SG_ 2449771009 ODS_SBRClassSta "Refer to Signal Value table";
BA_ "UserSigValidity" SG_ 2449771009 ODS_SBRClassSta 3;
BA_ "Version" SG_ 2449771009 ODS_SBRClassSta "19.05.02";
BA_ "GenMsgSendType" BO_ 2449771010 0;
BA_ "GenMsgCycleTime" BO_ 2449771010 1000;
BA_ "GenMsgCycleTimeFast" BO_ 2449771010 0;
BA_ "GenMsgNrOfRepetition" BO_ 2449771010 0;
BA_ "VFrameFormat" BO_ 2449771010 1;
BA_ "GenMsgCycleTime" BO_ 1113 0;
BA_ "Description" SG_ 1113 C_LH_Folding_State_PopUp "AVN Á¶ÀÛ ½ÅÈ£¿¡ µû¸¥ 3¿­ LHÃø ½ÃÆ® ¹é µ¿ÀÛ ¿Ï·á Á¤º¸ (AVN ÆË¾÷ Ç¥½Ã ½ÅÈ£)

 - 3rd LH seat Moving Finish / Mode-Fail signal";
BA_ "GenSigSendType" SG_ 1113 C_LH_Folding_State_PopUp 4;
BA_ "UserSigValidity" SG_ 1113 C_LH_Folding_State_PopUp 0;
BA_REL_ "GenSigTimeoutTime" BU_SG_REL_ APSU SG_ 1113 C_LH_Folding_State_PopUp 0;
BA_REL_ "GenSigTimeoutTime" BU_SG_REL_ CGW_CCU SG_ 1113 C_LH_Folding_State_PopUp 0;
BA_ "NetworkRequest" SG_ 1113 C_LH_Folding_State_PopUp 0;
BA_ "NetworkRequestHoldingTime" SG_ 1113 C_LH_Folding_State_PopUp 5000;
BA_ "Version" SG_ 1113 C_LH_Folding_State_PopUp "18.03.05";
BA_ "Description" SG_ 1113 C_RH_Folding_State_PopUp "AVN Á¶ÀÛ ½ÅÈ£¿¡ µû¸¥ 3¿­ RHÃø ½ÃÆ® ¹é µ¿ÀÛ ¿Ï·á Á¤º¸ (AVN ÆË¾÷ Ç¥½Ã ½ÅÈ£)

 - 3rd RH seat Moving Finish / Mode-Fail signal";
BA_ "GenSigSendType" SG_ 1113 C_RH_Folding_State_PopUp 4;
BA_ "UserSigValidity" SG_ 1113 C_RH_Folding_State_PopUp 0;
BA_REL_ "GenSigTimeoutTime" BU_SG_REL_ APSU SG_ 1113 C_RH_Folding_State_PopUp 0;
BA_REL_ "GenSigTimeoutTime" BU_SG_REL_ CGW_CCU SG_ 1113 C_RH_Folding_State_PopUp 0;
BA_ "NetworkRequest" SG_ 1113 C_RH_Folding_State_PopUp 0;
BA_ "NetworkRequestHoldingTime" SG_ 1113 C_RH_Folding_State_PopUp 5000;
BA_ "Version" SG_ 1113 C_RH_Folding_State_PopUp "18.03.05";
BA_ "GenMsgSendType" BO_ 1111 0;
BA_ "Description" SG_ 1111 C_LH_Folding_Position "3¿­ LH ½ÃÆ® ¹é ÇöÀç À§Ä¡ »óÅÂ Á¤º¸ ¼Û½Å

 - Seat Position Information signal for 3rd LH seat";
BA_ "GenSigSendType" SG_ 1111 C_LH_Folding_Position 4;
BA_ "UserSigValidity" SG_ 1111 C_LH_Folding_Position 0;
BA_REL_ "GenSigTimeoutTime" BU_SG_REL_ APSU SG_ 1111 C_LH_Folding_Position 1500;
BA_REL_ "GenSigTimeoutTime" BU_SG_REL_ RLPSU SG_ 1111 C_LH_Folding_Position 1500;
BA_REL_ "GenSigTimeoutTime" BU_SG_REL_ CGW_CCU SG_ 1111 C_LH_Folding_Position 1500;
BA_ "NetworkRequest" SG_ 1111 C_LH_Folding_Position 0;
BA_ "NetworkRequestHoldingTime" SG_ 1111 C_LH_Folding_Position 5000;
BA_ "Version" SG_ 1111 C_LH_Folding_Position "18.03.05";
BA_ "Description" SG_ 1111 PFSU_RH_ReclMtrPos "3¿­ RH ¸®Å¬¶óÀÌ³Ê Á¸¿¡ ´ëÇÑ Á¤º¸ Àü´Þ";
BA_ "GenSigSendType" SG_ 1111 PFSU_RH_ReclMtrPos 4;
BA_ "UserSigValidity" SG_ 1111 PFSU_RH_ReclMtrPos 0;
BA_ "NetworkRequest" SG_ 1111 PFSU_RH_ReclMtrPos 0;
BA_ "NetworkRequestHoldingTime" SG_ 1111 PFSU_RH_ReclMtrPos 5000;
BA_ "Version" SG_ 1111 PFSU_RH_ReclMtrPos "19.07.05";
BA_ "Description" SG_ 1111 PFSU_RL_Folding_SW "3¿­ Left Æúµù ½ºÀ§Ä¡¸¦ ¿¬µ¿ µ¿ÀÛ À§ÇØ 2¿­ Left¿¡ Àü´Þ

- 3rd LH Seat folding Information to 2nd LH Seat";
BA_ "GenSigSendType" SG_ 1111 PFSU_RL_Folding_SW 4;
BA_ "UserSigValidity" SG_ 1111 PFSU_RL_Folding_SW 0;
BA_REL_ "GenSigTimeoutTime" BU_SG_REL_ RLPSU SG_ 1111 PFSU_RL_Folding_SW 1500;
BA_ "NetworkRequest" SG_ 1111 PFSU_RL_Folding_SW 0;
BA_ "NetworkRequestHoldingTime" SG_ 1111 PFSU_RL_Folding_SW 5000;
BA_ "Version" SG_ 1111 PFSU_RL_Folding_SW "18.05.00";
BA_ "Description" SG_ 1111 PFSU_RR_Folding_SW "3¿­ Right Æúµù ½ºÀ§Ä¡¸¦ ¿¬µ¿ µ¿ÀÛ À§ÇØ 2¿­ Right¿¡ Àü´Þ

- 3rd RH Seat folding Information to 2nd RH Seat";
BA_ "GenSigSendType" SG_ 1111 PFSU_RR_Folding_SW 4;
BA_ "UserSigValidity" SG_ 1111 PFSU_RR_Folding_SW 0;
BA_REL_ "GenSigTimeoutTime" BU_SG_REL_ RRPSU SG_ 1111 PFSU_RR_Folding_SW 1500;
BA_ "NetworkRequest" SG_ 1111 PFSU_RR_Folding_SW 0;
BA_ "NetworkRequestHoldingTime" SG_ 1111 PFSU_RR_Folding_SW 5000;
BA_ "Version" SG_ 1111 PFSU_RR_Folding_SW "18.05.00";
BA_ "Description" SG_ 1111 PFSU_RL_Unfolding_SW "3¿­ Left ¾ðÆúµù ½ºÀ§Ä¡¸¦ ¿¬µ¿ µ¿ÀÛ À§ÇØ 2¿­ Left¿¡ Àü´Þ

- 3rd LH Seat unfolding Information to 2nd LH Seat";
BA_ "GenSigSendType" SG_ 1111 PFSU_RL_Unfolding_SW 4;
BA_ "UserSigValidity" SG_ 1111 PFSU_RL_Unfolding_SW 0;
BA_REL_ "GenSigTimeoutTime" BU_SG_REL_ RLPSU SG_ 1111 PFSU_RL_Unfolding_SW 1500;
BA_ "NetworkRequest" SG_ 1111 PFSU_RL_Unfolding_SW 0;
BA_ "NetworkRequestHoldingTime" SG_ 1111 PFSU_RL_Unfolding_SW 5000;
BA_ "Version" SG_ 1111 PFSU_RL_Unfolding_SW "18.05.00";
BA_ "Description" SG_ 1111 PFSU_RR_Unfolding_SW "3¿­ Right ¾ðÆúµù ½ºÀ§Ä¡¸¦ ¿¬µ¿ µ¿ÀÛ À§ÇØ 2¿­ Right¿¡ Àü´Þ

- 3rd RH Seat unfolding Information to 2nd RH Seat";
BA_ "GenSigSendType" SG_ 1111 PFSU_RR_Unfolding_SW 4;
BA_ "UserSigValidity" SG_ 1111 PFSU_RR_Unfolding_SW 0;
BA_REL_ "GenSigTimeoutTime" BU_SG_REL_ RRPSU SG_ 1111 PFSU_RR_Unfolding_SW 1500;
BA_ "NetworkRequest" SG_ 1111 PFSU_RR_Unfolding_SW 0;
BA_ "NetworkRequestHoldingTime" SG_ 1111 PFSU_RR_Unfolding_SW 5000;
BA_ "Version" SG_ 1111 PFSU_RR_Unfolding_SW "18.05.00";
BA_ "Description" SG_ 1111 C_RH_Folding_Position "3¿­ RH ½ÃÆ® ¹é ÇöÀç À§Ä¡ »óÅÂ Á¤º¸ ¼Û½Å

 - Seat Position Information signal for 3rd RH seat";
BA_ "GenSigSendType" SG_ 1111 C_RH_Folding_Position 4;
BA_ "UserSigValidity" SG_ 1111 C_RH_Folding_Position 0;
BA_REL_ "GenSigTimeoutTime" BU_SG_REL_ APSU SG_ 1111 C_RH_Folding_Position 1500;
BA_REL_ "GenSigTimeoutTime" BU_SG_REL_ RRPSU SG_ 1111 C_RH_Folding_Position 1500;
BA_REL_ "GenSigTimeoutTime" BU_SG_REL_ CGW_CCU SG_ 1111 C_RH_Folding_Position 1500;
BA_ "NetworkRequest" SG_ 1111 C_RH_Folding_Position 0;
BA_ "NetworkRequestHoldingTime" SG_ 1111 C_RH_Folding_Position 5000;
BA_ "Version" SG_ 1111 C_RH_Folding_Position "18.03.05";
BA_ "Description" SG_ 1111 PFSU_RR_FoldingDis "Third LH PSU Folding moving state: Folding";
BA_ "GenSigSendType" SG_ 1111 PFSU_RR_FoldingDis 4;
BA_ "UserSigValidity" SG_ 1111 PFSU_RR_FoldingDis 0;
BA_ "Version" SG_ 1111 PFSU_RR_FoldingDis "18.09.01";
BA_ "Description" SG_ 1111 PFSU_RR_UnfoldingDis "Third LH PSU Unfolding moving state: Unfolding";
BA_ "GenSigSendType" SG_ 1111 PFSU_RR_UnfoldingDis 4;
BA_ "UserSigValidity" SG_ 1111 PFSU_RR_UnfoldingDis 0;
BA_ "Version" SG_ 1111 PFSU_RR_UnfoldingDis "18.09.01";
BA_ "Description" SG_ 1111 PFSU_RL_FoldingDis "Third RH PSU Folding moving state: Folding";
BA_ "GenSigSendType" SG_ 1111 PFSU_RL_FoldingDis 4;
BA_ "UserSigValidity" SG_ 1111 PFSU_RL_FoldingDis 0;
BA_ "Version" SG_ 1111 PFSU_RL_FoldingDis "18.09.01";
BA_ "Description" SG_ 1111 PFSU_RL_UnfoldingDis "Third RH PSU Unfolding moving state: Unfolding";
BA_ "GenSigSendType" SG_ 1111 PFSU_RL_UnfoldingDis 4;
BA_ "UserSigValidity" SG_ 1111 PFSU_RL_UnfoldingDis 0;
BA_ "Version" SG_ 1111 PFSU_RL_UnfoldingDis "18.09.01";
BA_ "Description" SG_ 1111 PFSU_RR_HrstFoldingDis "Third RH H/rest Folding moving state: H/rest folding";
BA_ "GenSigSendType" SG_ 1111 PFSU_RR_HrstFoldingDis 4;
BA_ "UserSigValidity" SG_ 1111 PFSU_RR_HrstFoldingDis 0;
BA_ "Version" SG_ 1111 PFSU_RR_HrstFoldingDis "18.09.01";
BA_ "Description" SG_ 1111 PFSU_RL_HrstFoldingDis "Third LH H/rest Folding moving state: H/rest folding";
BA_ "GenSigSendType" SG_ 1111 PFSU_RL_HrstFoldingDis 4;
BA_ "UserSigValidity" SG_ 1111 PFSU_RL_HrstFoldingDis 0;
BA_REL_ "GenSigTimeoutTime" BU_SG_REL_ CGW_CCU SG_ 1111 PFSU_RL_HrstFoldingDis 1500;
BA_ "Version" SG_ 1111 PFSU_RL_HrstFoldingDis "18.09.01";
BA_ "Description" SG_ 1111 PFSU_RR_SlideFwdDis "Third LH PSU Recliner FWD moving state";
BA_ "GenSigSendType" SG_ 1111 PFSU_RR_SlideFwdDis 4;
BA_ "UserSigValidity" SG_ 1111 PFSU_RR_SlideFwdDis 0;
BA_ "Version" SG_ 1111 PFSU_RR_SlideFwdDis "18.09.01";
BA_ "Description" SG_ 1111 PFSU_RR_SlidBwdDis "Third LH PSU Recliner BWD moving state";
BA_ "GenSigSendType" SG_ 1111 PFSU_RR_SlidBwdDis 4;
BA_ "UserSigValidity" SG_ 1111 PFSU_RR_SlidBwdDis 0;
BA_ "Version" SG_ 1111 PFSU_RR_SlidBwdDis "18.09.01";
BA_ "Description" SG_ 1111 PFSU_RL_SlideFwdDis "Third RH PSU Recliner FWD moving state";
BA_ "GenSigSendType" SG_ 1111 PFSU_RL_SlideFwdDis 4;
BA_ "UserSigValidity" SG_ 1111 PFSU_RL_SlideFwdDis 0;
BA_ "Version" SG_ 1111 PFSU_RL_SlideFwdDis "18.09.01";
BA_ "Description" SG_ 1111 PFSU_RL_SlideBwdDis "Third RH PSU Recliner BWD moving state";
BA_ "GenSigSendType" SG_ 1111 PFSU_RL_SlideBwdDis 4;
BA_ "UserSigValidity" SG_ 1111 PFSU_RL_SlideBwdDis 0;
BA_ "Version" SG_ 1111 PFSU_RL_SlideBwdDis "18.09.01";
BA_ "Description" SG_ 1111 PFSU_Opt "PFSU Option Information";
BA_ "GenSigSendType" SG_ 1111 PFSU_Opt 4;
BA_ "UserSigValidity" SG_ 1111 PFSU_Opt 0;
BA_REL_ "GenSigTimeoutTime" BU_SG_REL_ CGW_CCU SG_ 1111 PFSU_Opt 1500;
BA_ "Version" SG_ 1111 PFSU_Opt "18.09.01";
BA_ "Description" SG_ 1111 PFSU_LH_ReclMtrPos "3¿­ LH ¸®Å¬¶óÀÌ³Ê Á¸¿¡ ´ëÇÑ Á¤º¸ Àü´Þ";
BA_ "GenSigSendType" SG_ 1111 PFSU_LH_ReclMtrPos 4;
BA_ "UserSigValidity" SG_ 1111 PFSU_LH_ReclMtrPos 0;
BA_ "NetworkRequest" SG_ 1111 PFSU_LH_ReclMtrPos 0;
BA_ "NetworkRequestHoldingTime" SG_ 1111 PFSU_LH_ReclMtrPos 5000;
BA_ "Version" SG_ 1111 PFSU_LH_ReclMtrPos "19.07.05";
BA_ "GenMsgSendType" BO_ 1089 0;
BA_ "GenSigSendType" SG_ 1089 RRPSM_SeatTyp 4;
BA_ "UserSigValidity" SG_ 1089 RRPSM_SeatTyp 0;
BA_REL_ "GenSigTimeoutTime" BU_SG_REL_ DPSU SG_ 1089 RRPSM_SeatTyp 1500;
BA_ "NetworkRequest" SG_ 1089 RRPSM_SeatTyp 0;
BA_ "NetworkRequestHoldingTime" SG_ 1089 RRPSM_SeatTyp 5000;
BA_ "Version" SG_ 1089 RRPSM_SeatTyp "21.03.11";
BA_ "GenSigSendType" SG_ 1089 RRPSM_RRStEsyAcsUSMSta 4;
BA_ "UserSigValidity" SG_ 1089 RRPSM_RRStEsyAcsUSMSta 0;
BA_REL_ "GenSigTimeoutTime" BU_SG_REL_ ATS SG_ 1089 RRPSM_RRStEsyAcsUSMSta 1500;
BA_REL_ "GenSigTimeoutTime" BU_SG_REL_ CGW_CCU SG_ 1089 RRPSM_RRStEsyAcsUSMSta 1500;
BA_ "NetworkRequest" SG_ 1089 RRPSM_RRStEsyAcsUSMSta 0;
BA_ "NetworkRequestHoldingTime" SG_ 1089 RRPSM_RRStEsyAcsUSMSta 5000;
BA_ "Version" SG_ 1089 RRPSM_RRStEsyAcsUSMSta "19.10.07";
BA_ "Description" SG_ 1089 RRPSM_RRSlidePosition "ASSIST SEAT SLIDE POSITION (UNIT: mm)";
BA_ "GenSigSendType" SG_ 1089 RRPSM_RRSlidePosition 4;
BA_ "UserSigValidity" SG_ 1089 RRPSM_RRSlidePosition 0;
BA_ "NetworkRequest" SG_ 1089 RRPSM_RRSlidePosition 0;
BA_ "NetworkRequestHoldingTime" SG_ 1089 RRPSM_RRSlidePosition 5000;
BA_ "Version" SG_ 1089 RRPSM_RRSlidePosition "19.08.08";
BA_ "Description" SG_ 1089 RRPSM_SeatPos_Sta "The signal indicates the state of  Rear Right seat Meomry State";
BA_ "GenSigSendType" SG_ 1089 RRPSM_SeatPos_Sta 4;
BA_ "UserSigValidity" SG_ 1089 RRPSM_SeatPos_Sta 0;
BA_ "Version" SG_ 1089 RRPSM_SeatPos_Sta "20.03.00";
BA_ "Description" SG_ 1089 RRPSM_SeatPosSldLmt_Sta "RRPSM Slide end Position and limit Initialize State information";
BA_ "GenSigSendType" SG_ 1089 RRPSM_SeatPosSldLmt_Sta 4;
BA_ "UserSigValidity" SG_ 1089 RRPSM_SeatPosSldLmt_Sta 0;
BA_ "NetworkRequest" SG_ 1089 RRPSM_SeatPosSldLmt_Sta 0;
BA_ "NetworkRequestHoldingTime" SG_ 1089 RRPSM_SeatPosSldLmt_Sta 5000;
BA_ "Version" SG_ 1089 RRPSM_SeatPosSldLmt_Sta "20.03.00";
BA_ "Description" SG_ 1089 RRPSM_RearModeState "Rear Seat State For One Touch Mode";
BA_ "GenSigSendType" SG_ 1089 RRPSM_RearModeState 4;
BA_ "UserSigValidity" SG_ 1089 RRPSM_RearModeState 0;
BA_REL_ "GenSigTimeoutTime" BU_SG_REL_ ATS SG_ 1089 RRPSM_RearModeState 1500;
BA_REL_ "GenSigTimeoutTime" BU_SG_REL_ OHCL SG_ 1089 RRPSM_RearModeState 1500;
BA_REL_ "GenSigTimeoutTime" BU_SG_REL_ CGW_CCU SG_ 1089 RRPSM_RearModeState 1500;
BA_ "NetworkRequest" SG_ 1089 RRPSM_RearModeState 0;
BA_ "NetworkRequestHoldingTime" SG_ 1089 RRPSM_RearModeState 5000;
BA_ "Version" SG_ 1089 RRPSM_RearModeState "20.11.02";
BA_ "Description" SG_ 1089 RRPSM_RRLegRestPosition "Rear SEAT Leg Rest UP/DOWN POSITION (UNIT: ¨¬)";
BA_ "GenSigSendType" SG_ 1089 RRPSM_RRLegRestPosition 4;
BA_ "UserSigValidity" SG_ 1089 RRPSM_RRLegRestPosition 0;
BA_ "NetworkRequest" SG_ 1089 RRPSM_RRLegRestPosition 0;
BA_ "NetworkRequestHoldingTime" SG_ 1089 RRPSM_RRLegRestPosition 5000;
BA_ "Version" SG_ 1089 RRPSM_RRLegRestPosition "20.09.00";
BA_ "GenMsgSendType" BO_ 1107 0;
BA_ "Description" SG_ 1107 RR_SHVU_SeatOptSta "ÈÄ¼® RH ½ÃÆ®¿¡ Àû¿ëµÈ È÷ÅÍ/ÅëÇ³ ¿É¼Ç »ç¾ç";
BA_ "GenSigSendType" SG_ 1107 RR_SHVU_SeatOptSta 4;
BA_ "UserSigValidity" SG_ 1107 RR_SHVU_SeatOptSta 3;
BA_REL_ "GenSigTimeoutTime" BU_SG_REL_ ASAU SG_ 1107 RR_SHVU_SeatOptSta 1500;
BA_REL_ "GenSigTimeoutTime" BU_SG_REL_ ATS SG_ 1107 RR_SHVU_SeatOptSta 1500;
BA_REL_ "GenSigTimeoutTime" BU_SG_REL_ CGW_CCU SG_ 1107 RR_SHVU_SeatOptSta 1500;
BA_REL_ "GenSigTimeoutTime" BU_SG_REL_ ATS SG_ 1107 RR_SHVU_SeatOptSta 1500;
BA_REL_ "GenSigTimeoutTime" BU_SG_REL_ CGW_CCU SG_ 1107 RR_SHVU_SeatOptSta 1500;
BA_ "NetworkRequest" SG_ 1107 RR_SHVU_SeatOptSta 0;
BA_ "NetworkRequestHoldingTime" SG_ 1107 RR_SHVU_SeatOptSta 5000;
BA_ "Version" SG_ 1107 RR_SHVU_SeatOptSta "17.12.03";
BA_ "Description" SG_ 1107 RR_SHVU_SeatHtOperSta "ÈÄ¼® RH ½ÃÆ® ÇöÀç ÀÛµ¿ ÁßÀÎ È÷ÅÍ/ÅëÇ³ ´Ü¼ö »óÅÂ";
BA_ "GenSigSendType" SG_ 1107 RR_SHVU_SeatHtOperSta 4;
BA_ "UserSigValidity" SG_ 1107 RR_SHVU_SeatHtOperSta 3;
BA_REL_ "GenSigTimeoutTime" BU_SG_REL_ ASAU SG_ 1107 RR_SHVU_SeatHtOperSta 1500;
BA_REL_ "GenSigTimeoutTime" BU_SG_REL_ ATS SG_ 1107 RR_SHVU_SeatHtOperSta 1500;
BA_REL_ "GenSigTimeoutTime" BU_SG_REL_ CGW_CCU SG_ 1107 RR_SHVU_SeatHtOperSta 1500;
BA_REL_ "GenSigTimeoutTime" BU_SG_REL_ ATS SG_ 1107 RR_SHVU_SeatHtOperSta 1500;
BA_REL_ "GenSigTimeoutTime" BU_SG_REL_ CGW_CCU SG_ 1107 RR_SHVU_SeatHtOperSta 1500;
BA_ "NetworkRequest" SG_ 1107 RR_SHVU_SeatHtOperSta 0;
BA_ "NetworkRequestHoldingTime" SG_ 1107 RR_SHVU_SeatHtOperSta 5000;
BA_ "Version" SG_ 1107 RR_SHVU_SeatHtOperSta "21.09.07";
BA_ "GenMsgSendType" BO_ 1094 0;
BA_ "Description" SG_ 1094 SLB_PlyBckSta "This signal indicates the playback status (IMS)";
BA_ "GenSigSendType" SG_ 1094 SLB_PlyBckSta 4;
BA_ "UserSigValidity" SG_ 1094 SLB_PlyBckSta 0;
BA_ "NetworkRequest" SG_ 1094 SLB_PlyBckSta 0;
BA_ "NetworkRequestHoldingTime" SG_ 1094 SLB_PlyBckSta 5000;
BA_ "Version" SG_ 1094 SLB_PlyBckSta "17.11.00";
BA_ "GenMsgSendType" BO_ 1092 0;
BA_ "Description" SG_ 1092 SMK_Crc2Val "The data area for CRC calculation is based on the data length (DLC) of the message DB.

The CRC shall be calculated over the entire data block (excluding the CRC bytes) including the user data, alive counter and Data ID 

 

- CRC Polynomial (0x1D) , Initial Value : 0x00, XOR value : 0xFF, Data ID Mode : Both, Data ID : Message ID + 0xF800 

- The initial value is for CRC calculation and the message should be sent with the calculated result value. 

The mathematical expression to 8 bit CRC polynomial is given here. G(x) = x8 + x4 + x3 + x2 + 1";
BA_ "GenSigSendType" SG_ 1092 SMK_Crc2Val 4;
BA_ "GenSigStartValue" SG_ 1092 SMK_Crc2Val 255;
BA_ "UserSigValidity" SG_ 1092 SMK_Crc2Val 0;
BA_ "Version" SG_ 1092 SMK_Crc2Val "18.11.08";
BA_ "Description" SG_ 1092 SMK_AlvCnt2Val "For the first transmission request for a data element the counter shall be initialized with 0 and shall be incremented by 1

for every subsequent send request. When the counter reaches the maximum value(0xE), then it shall restart with 0 for the next send request";
BA_ "GenSigSendType" SG_ 1092 SMK_AlvCnt2Val 4;
BA_ "UserSigValidity" SG_ 1092 SMK_AlvCnt2Val 0;
BA_ "Version" SG_ 1092 SMK_AlvCnt2Val "18.11.08";
BA_ "Description" SG_ 1092 SSB_StrtStpBtnSw1Sta "StartStop button switch #1 status";
BA_ "GenSigSendType" SG_ 1092 SSB_StrtStpBtnSw1Sta 4;
BA_ "UserSigValidity" SG_ 1092 SSB_StrtStpBtnSw1Sta 0;
BA_ "Version" SG_ 1092 SSB_StrtStpBtnSw1Sta "17.12.00";
BA_ "Description" SG_ 1092 SSB_StrtStpBtnSw2Sta "StartStop button switch #2 status";
BA_ "GenSigSendType" SG_ 1092 SSB_StrtStpBtnSw2Sta 4;
BA_ "UserSigValidity" SG_ 1092 SSB_StrtStpBtnSw2Sta 0;
BA_ "Version" SG_ 1092 SSB_StrtStpBtnSw2Sta "17.12.00";
BA_ "Description" SG_ 1092 SMK_TrmnlCtrlSta "Mirror value of TerminalControlState";
BA_ "GenSigSendType" SG_ 1092 SMK_TrmnlCtrlSta 4;
BA_ "UserSigValidity" SG_ 1092 SMK_TrmnlCtrlSta 0;
BA_REL_ "GenSigTimeoutTime" BU_SG_REL_ BLTN_CAM SG_ 1092 SMK_TrmnlCtrlSta 1500;
BA_ "Version" SG_ 1092 SMK_TrmnlCtrlSta "17.12.00";
BA_ "Description" SG_ 1092 SMK_TrmnlMngrSta "Mirror valeu of TerminalsManager Stat";
BA_ "GenSigSendType" SG_ 1092 SMK_TrmnlMngrSta 4;
BA_ "UserSigValidity" SG_ 1092 SMK_TrmnlMngrSta 0;
BA_ "Version" SG_ 1092 SMK_TrmnlMngrSta "19.03.05";
BA_ "GenSigSendType" SG_ 1092 SMK_AuthSta 4;
BA_ "UserSigValidity" SG_ 1092 SMK_AuthSta 0;
BA_REL_ "GenSigTimeoutTime" BU_SG_REL_ APSU SG_ 1092 SMK_AuthSta 1500;
BA_REL_ "GenSigTimeoutTime" BU_SG_REL_ DPSU SG_ 1092 SMK_AuthSta 1500;
BA_ "Version" SG_ 1092 SMK_AuthSta "17.12.00";
BA_ "Description" SG_ 1092 SMK_Ign1InSta "Ignition1 Input Status at SMK";
BA_ "GenSigSendType" SG_ 1092 SMK_Ign1InSta 4;
BA_ "UserSigValidity" SG_ 1092 SMK_Ign1InSta 0;
BA_ "Version" SG_ 1092 SMK_Ign1InSta "17.12.00";
BA_ "Description" SG_ 1092 SMK_Ign1RlySta "Development for SMK";
BA_ "GenSigSendType" SG_ 1092 SMK_Ign1RlySta 4;
BA_ "UserSigValidity" SG_ 1092 SMK_Ign1RlySta 0;
BA_ "Version" SG_ 1092 SMK_Ign1RlySta "17.12.00";
BA_ "Description" SG_ 1092 SMK_Ign2InSta "Ignition2 Input Status at SMK";
BA_ "GenSigSendType" SG_ 1092 SMK_Ign2InSta 4;
BA_ "UserSigValidity" SG_ 1092 SMK_Ign2InSta 0;
BA_ "Version" SG_ 1092 SMK_Ign2InSta "17.12.00";
BA_ "Description" SG_ 1092 SMK_Ign2RlySta "Development for SMK";
BA_ "GenSigSendType" SG_ 1092 SMK_Ign2RlySta 4;
BA_ "UserSigValidity" SG_ 1092 SMK_Ign2RlySta 0;
BA_ "Version" SG_ 1092 SMK_Ign2RlySta "17.12.00";
BA_ "Description" SG_ 1092 SMK_StrtFdbckSta "Mirror value of L_StartFeedback";
BA_ "GenSigSendType" SG_ 1092 SMK_StrtFdbckSta 4;
BA_ "UserSigValidity" SG_ 1092 SMK_StrtFdbckSta 0;
BA_ "Version" SG_ 1092 SMK_StrtFdbckSta "17.12.00";
BA_ "Description" SG_ 1092 SMK_StrtrRlyOutSta "-(Old)C_StarterRelayStatus";
BA_ "GenSigSendType" SG_ 1092 SMK_StrtrRlyOutSta 4;
BA_ "UserSigValidity" SG_ 1092 SMK_StrtrRlyOutSta 0;
BA_ "Version" SG_ 1092 SMK_StrtrRlyOutSta "17.12.00";
BA_ "Description" SG_ 1092 SMK_AccInSta "ACC Input Status at SMK";
BA_ "GenSigSendType" SG_ 1092 SMK_AccInSta 4;
BA_ "UserSigValidity" SG_ 1092 SMK_AccInSta 0;
BA_ "Version" SG_ 1092 SMK_AccInSta "17.12.00";
BA_ "Description" SG_ 1092 SMK_AccRlySta "Development for SMK";
BA_ "GenSigSendType" SG_ 1092 SMK_AccRlySta 4;
BA_ "UserSigValidity" SG_ 1092 SMK_AccRlySta 0;
BA_ "Version" SG_ 1092 SMK_AccRlySta "17.12.00";
BA_ "Description" SG_ 1092 SMK_CLUAccIndOnReq "Request to Cluster ACC Indicator On

(This is only used for CLU)";
BA_ "GenSigSendType" SG_ 1092 SMK_CLUAccIndOnReq 4;
BA_ "UserSigValidity" SG_ 1092 SMK_CLUAccIndOnReq 0;
BA_ "Version" SG_ 1092 SMK_CLUAccIndOnReq "17.12.00";
BA_ "GenSigSendType" SG_ 1092 SMK_VDModeActSta 4;
BA_ "UserSigValidity" SG_ 1092 SMK_VDModeActSta 0;
BA_ "Version" SG_ 1092 SMK_VDModeActSta "20.07.05";
BA_ "GenSigSendType" SG_ 1092 SMK_TlEngRunSta 4;
BA_ "UserSigValidity" SG_ 1092 SMK_TlEngRunSta 0;
BA_REL_ "GenSigTimeoutTime" BU_SG_REL_ APSU SG_ 1092 SMK_TlEngRunSta 1500;
BA_REL_ "GenSigTimeoutTime" BU_SG_REL_ RLHV SG_ 1092 SMK_TlEngRunSta 1500;
BA_REL_ "GenSigTimeoutTime" BU_SG_REL_ RRHV SG_ 1092 SMK_TlEngRunSta 1500;
BA_REL_ "GenSigTimeoutTime" BU_SG_REL_ SHVU_FR SG_ 1092 SMK_TlEngRunSta 1500;
BA_REL_ "GenSigTimeoutTime" BU_SG_REL_ SHVU_RR SG_ 1092 SMK_TlEngRunSta 1500;
BA_REL_ "GenSigTimeoutTime" BU_SG_REL_ DPSU SG_ 1092 SMK_TlEngRunSta 1500;
BA_REL_ "GenSigTimeoutTime" BU_SG_REL_ RRPSU SG_ 1092 SMK_TlEngRunSta 1500;
BA_REL_ "GenSigTimeoutTime" BU_SG_REL_ RLPSU SG_ 1092 SMK_TlEngRunSta 1500;
BA_REL_ "GenSigTimeoutTime" BU_SG_REL_ ATS SG_ 1092 SMK_TlEngRunSta 1500;
BA_REL_ "GenSigTimeoutTime" BU_SG_REL_ DSAU SG_ 1092 SMK_TlEngRunSta 1500;
BA_REL_ "GenSigTimeoutTime" BU_SG_REL_ ASAU SG_ 1092 SMK_TlEngRunSta 1500;
BA_ "Version" SG_ 1092 SMK_TlEngRunSta "17.12.00";
BA_ "GenSigSendType" SG_ 1092 SMK_TlCrnkModSta 4;
BA_ "UserSigValidity" SG_ 1092 SMK_TlCrnkModSta 0;
BA_REL_ "GenSigTimeoutTime" BU_SG_REL_ SCM SG_ 1092 SMK_TlCrnkModSta 1500;
BA_REL_ "GenSigTimeoutTime" BU_SG_REL_ APSU SG_ 1092 SMK_TlCrnkModSta 1500;
BA_REL_ "GenSigTimeoutTime" BU_SG_REL_ DPSU SG_ 1092 SMK_TlCrnkModSta 1500;
BA_REL_ "GenSigTimeoutTime" BU_SG_REL_ RRPSU SG_ 1092 SMK_TlCrnkModSta 1500;
BA_REL_ "GenSigTimeoutTime" BU_SG_REL_ RLPSU SG_ 1092 SMK_TlCrnkModSta 1500;
BA_REL_ "GenSigTimeoutTime" BU_SG_REL_ ATS SG_ 1092 SMK_TlCrnkModSta 1500;
BA_REL_ "GenSigTimeoutTime" BU_SG_REL_ DSAU SG_ 1092 SMK_TlCrnkModSta 1500;
BA_REL_ "GenSigTimeoutTime" BU_SG_REL_ ASAU SG_ 1092 SMK_TlCrnkModSta 1500;
BA_ "Version" SG_ 1092 SMK_TlCrnkModSta "17.12.00";
BA_ "GenSigSendType" SG_ 1092 SMK_RmtKeyEngRunSta 4;
BA_ "UserSigValidity" SG_ 1092 SMK_RmtKeyEngRunSta 0;
BA_ "Version" SG_ 1092 SMK_RmtKeyEngRunSta "17.11.00";
BA_ "GenSigSendType" SG_ 1092 SMK_RmtKeyCrnkModSta 4;
BA_ "UserSigValidity" SG_ 1092 SMK_RmtKeyCrnkModSta 0;
BA_ "Version" SG_ 1092 SMK_RmtKeyCrnkModSta "17.11.00";
BA_ "GenMsgSendType" BO_ 1093 0;
BA_ "Description" SG_ 1093 SMK_Crc6Val "The data area for CRC calculation is based on the data length (DLC) of the message DB.

The CRC shall be calculated over the entire data block (excluding the CRC bytes) including the user data, alive counter and Data ID 

 

- CRC Polynomial (0x1D) , Initial Value : 0x00, XOR value : 0xFF, Data ID Mode : Both, Data ID : Message ID + 0xF800 

- The initial value is for CRC calculation and the message should be sent with the calculated result value. 

The mathematical expression to 8 bit CRC polynomial is given here. G(x) = x8 + x4 + x3 + x2 + 1";
BA_ "GenSigSendType" SG_ 1093 SMK_Crc6Val 4;
BA_ "GenSigStartValue" SG_ 1093 SMK_Crc6Val 255;
BA_ "UserSigValidity" SG_ 1093 SMK_Crc6Val 0;
BA_ "Version" SG_ 1093 SMK_Crc6Val "18.11.08";
BA_ "Description" SG_ 1093 SMK_AlvCnt6Val "For the first transmission request for a data element the counter shall be initialized with 0 and shall be incremented by 1

for every subsequent send request. When the counter reaches the maximum value(0xE), then it shall restart with 0 for the next send request";
BA_ "GenSigSendType" SG_ 1093 SMK_AlvCnt6Val 4;
BA_ "UserSigValidity" SG_ 1093 SMK_AlvCnt6Val 0;
BA_ "Version" SG_ 1093 SMK_AlvCnt6Val "18.11.08";
BA_ "Description" SG_ 1093 Lamp_HzrdBlnkngSta "Hazard Signal for Hands Free Trunk/Tailgate";
BA_ "GenSigSendType" SG_ 1093 Lamp_HzrdBlnkngSta 4;
BA_ "UserSigValidity" SG_ 1093 Lamp_HzrdBlnkngSta 0;
BA_ "Version" SG_ 1093 Lamp_HzrdBlnkngSta "17.12.00";
BA_ "Description" SG_ 1093 RSPA_LearntSta "IBU RSPA learnt state signal.

This signal is used only for ADAS_PRK.";
BA_ "GenSigSendType" SG_ 1093 RSPA_LearntSta 4;
BA_ "UserSigValidity" SG_ 1093 RSPA_LearntSta 0;
BA_ "Version" SG_ 1093 RSPA_LearntSta "19.07.01";
BA_ "Description" SG_ 1093 Lamp_SmrtWlcmLtOnReq "Smart Key welcome light on request.";
BA_ "GenSigSendType" SG_ 1093 Lamp_SmrtWlcmLtOnReq 4;
BA_ "UserSigValidity" SG_ 1093 Lamp_SmrtWlcmLtOnReq 0;
BA_ "NetworkRequest" SG_ 1093 Lamp_SmrtWlcmLtOnReq 0;
BA_ "NetworkRequestHoldingTime" SG_ 1093 Lamp_SmrtWlcmLtOnReq 5000;
BA_ "Version" SG_ 1093 Lamp_SmrtWlcmLtOnReq "17.12.00";
BA_ "Description" SG_ 1093 Fob_BattStaInfo "Received Fob Battery Status for Telematics Vehicle Information Service";
BA_ "GenSigSendType" SG_ 1093 Fob_BattStaInfo 4;
BA_ "UserSigValidity" SG_ 1093 Fob_BattStaInfo 0;
BA_ "Version" SG_ 1093 Fob_BattStaInfo "17.12.00";
BA_ "Description" SG_ 1093 Fob_FoundDrvWlcmArea "This Signal Indicates direction of user approach to vehicle.

If User Approach to vehicle Driver direction, This signal set On.";
BA_ "GenSigSendType" SG_ 1093 Fob_FoundDrvWlcmArea 4;
BA_ "UserSigValidity" SG_ 1093 Fob_FoundDrvWlcmArea 0;
BA_ "Version" SG_ 1093 Fob_FoundDrvWlcmArea "17.12.00";
BA_ "Description" SG_ 1093 Fob_FoundAsstWlcmArea "This Signal Indicates direction of user approach to vehicle.

If User Approach to vehicle Assistant direction, This signal set On.";
BA_ "GenSigSendType" SG_ 1093 Fob_FoundAsstWlcmArea 4;
BA_ "UserSigValidity" SG_ 1093 Fob_FoundAsstWlcmArea 0;
BA_ "Version" SG_ 1093 Fob_FoundAsstWlcmArea "17.12.00";
BA_ "Description" SG_ 1093 Fob_FoundExtrnlArea "Exterior FOB Position recognize";
BA_ "GenSigSendType" SG_ 1093 Fob_FoundExtrnlArea 4;
BA_ "UserSigValidity" SG_ 1093 Fob_FoundExtrnlArea 0;
BA_ "Version" SG_ 1093 Fob_FoundExtrnlArea "17.12.00";
BA_ "Description" SG_ 1093 Fob_FoundIntArea "Interior FOB Position recognize";
BA_ "GenSigSendType" SG_ 1093 Fob_FoundIntArea 4;
BA_ "UserSigValidity" SG_ 1093 Fob_FoundIntArea 0;
BA_ "Version" SG_ 1093 Fob_FoundIntArea "17.12.00";
BA_ "Description" SG_ 1093 Fob_LearntSta "Fob key registration status information";
BA_ "GenSigSendType" SG_ 1093 Fob_LearntSta 4;
BA_ "GenSigStartValue" SG_ 1093 Fob_LearntSta 1;
BA_ "UserSigValidity" SG_ 1093 Fob_LearntSta 0;
BA_ "NetworkRequest" SG_ 1093 Fob_LearntSta 0;
BA_ "NetworkRequestHoldingTime" SG_ 1093 Fob_LearntSta 5000;
BA_ "Version" SG_ 1093 Fob_LearntSta "17.12.00";
BA_ "Description" SG_ 1093 RSPA_RFSigErrSta "Error status of RKE_BtnReq signal.



If RF frame data from FOB defferent with CAN signal data(RKE_BtnReq), 

RSPA_RFSigErrSta signal send 0x1 Signal Invalid.";
BA_ "GenSigSendType" SG_ 1093 RSPA_RFSigErrSta 4;
BA_ "UserSigValidity" SG_ 1093 RSPA_RFSigErrSta 0;
BA_ "NetworkRequest" SG_ 1093 RSPA_RFSigErrSta 0;
BA_ "NetworkRequestHoldingTime" SG_ 1093 RSPA_RFSigErrSta 5000;
BA_ "Version" SG_ 1093 RSPA_RFSigErrSta "18.05.02";
BA_ "Description" SG_ 1093 RSPA_CanErrSta "Error status of RSPA control signals.(From ADAS_PRK)";
BA_ "GenSigSendType" SG_ 1093 RSPA_CanErrSta 4;
BA_ "UserSigValidity" SG_ 1093 RSPA_CanErrSta 0;
BA_ "Version" SG_ 1093 RSPA_CanErrSta "18.05.02";
BA_ "Description" SG_ 1093 LFAnt_FltSta "This signal represents LF ANT's Error condition. 

If one of LF ANT has Fault(ex, timeout), signal has fault value.";
BA_ "GenSigSendType" SG_ 1093 LFAnt_FltSta 4;
BA_ "UserSigValidity" SG_ 1093 LFAnt_FltSta 0;
BA_ "Version" SG_ 1093 LFAnt_FltSta "17.12.00";
BA_ "Description" SG_ 1093 LFAnt_SrchSta "SMK LF Searching Status



This signal indicates that SMK operates LF searching for finding FOB.

WPC uses this signal for suspending wirless charging.";
BA_ "GenSigSendType" SG_ 1093 LFAnt_SrchSta 4;
BA_ "UserSigValidity" SG_ 1093 LFAnt_SrchSta 0;
BA_REL_ "GenSigTimeoutTime" BU_SG_REL_ WPC SG_ 1093 LFAnt_SrchSta 1500;
BA_REL_ "GenSigTimeoutTime" BU_SG_REL_ RWPC SG_ 1093 LFAnt_SrchSta 1500;
BA_ "Version" SG_ 1093 LFAnt_SrchSta "17.12.00";
BA_ "Description" SG_ 1093 Auth_ISKLearnSta "This signal is State of IAU Learning";
BA_ "GenSigSendType" SG_ 1093 Auth_ISKLearnSta 4;
BA_ "UserSigValidity" SG_ 1093 Auth_ISKLearnSta 0;
BA_ "Version" SG_ 1093 Auth_ISKLearnSta "19.02.07";
BA_ "Description" SG_ 1093 RSPA_ModSta_SMK "State of RSPA system operate";
BA_ "GenSigSendType" SG_ 1093 RSPA_ModSta_SMK 4;
BA_ "UserSigValidity" SG_ 1093 RSPA_ModSta_SMK 0;
BA_REL_ "GenSigTimeoutTime" BU_SG_REL_ DPSU SG_ 1093 RSPA_ModSta_SMK 1500;
BA_ "Version" SG_ 1093 RSPA_ModSta_SMK "19.03.08";
BA_ "Description" SG_ 1093 RSPA_FobBattSta "FOB Battery's Low Battery(discharge) state.

Low Battery condition is same with 'C_KeyBATDischargeWarn' Signal";
BA_ "GenSigSendType" SG_ 1093 RSPA_FobBattSta 4;
BA_ "UserSigValidity" SG_ 1093 RSPA_FobBattSta 0;
BA_ "Version" SG_ 1093 RSPA_FobBattSta "17.12.00";
BA_ "Description" SG_ 1093 Fob_BtnReleasedSta "this signal indicate fob butten released state during RSPA mode. 

##2G##IBU##SMK18##C_FobButtenReleased";
BA_ "GenSigSendType" SG_ 1093 Fob_BtnReleasedSta 4;
BA_ "UserSigValidity" SG_ 1093 Fob_BtnReleasedSta 0;
BA_ "Version" SG_ 1093 Fob_BtnReleasedSta "18.10.09";
BA_ "GenSigSendType" SG_ 1093 USM_SmrtTrnkTlgtModSta 4;
BA_ "UserSigValidity" SG_ 1093 USM_SmrtTrnkTlgtModSta 0;
BA_ "Version" SG_ 1093 USM_SmrtTrnkTlgtModSta "18.05.01";
BA_ "Description" SG_ 1093 USM_WALModSta "Current USM Setting value of Walk Away Lock(WAL) mode";
BA_ "GenSigSendType" SG_ 1093 USM_WALModSta 4;
BA_ "UserSigValidity" SG_ 1093 USM_WALModSta 0;
BA_ "Version" SG_ 1093 USM_WALModSta "17.12.00";
BA_ "Description" SG_ 1093 Fob_FoundWlcmArea "This signal indicates that there is Fob around the welcome area. 

 -to inform the door handle (Lock/Unlock touch sensor)";
BA_ "GenSigSendType" SG_ 1093 Fob_FoundWlcmArea 4;
BA_ "UserSigValidity" SG_ 1093 Fob_FoundWlcmArea 0;
BA_ "Version" SG_ 1093 Fob_FoundWlcmArea "19.03.09";
BA_ "GenMsgSendType" BO_ 1096 0;
BA_ "Description" SG_ 1096 SWRC_Crc1Val "The data area for CRC calculation is based on the data length (DLC) of the message DB.

The CRC shall be calculated over the entire data block (excluding the CRC bytes) including the user data, alive counter and Data ID 

 

- CRC Polynomial (0x1D) , Initial Value : 0x00, XOR value : 0xFF, Data ID Mode : Both, Data ID : Message ID + 0xF800 

- The initial value is for CRC calculation and the message should be sent with the calculated result value. 

The mathematical expression to 8 bit CRC polynomial is given here. G(x) = x8 + x4 + x3 + x2 + 1";
BA_ "GenSigSendType" SG_ 1096 SWRC_Crc1Val 4;
BA_ "GenSigStartValue" SG_ 1096 SWRC_Crc1Val 255;
BA_ "UserSigValidity" SG_ 1096 SWRC_Crc1Val 0;
BA_ "Version" SG_ 1096 SWRC_Crc1Val "19.11.02";
BA_ "Description" SG_ 1096 SWRC_AlvCnt1Val "For the first transmission request for a data element the counter shall be initialized with 0 and shall be incremented by 1

for every subsequent send request. When the counter reaches the maximum value(0xE), then it shall restart with 0 for the next send request";
BA_ "GenSigSendType" SG_ 1096 SWRC_AlvCnt1Val 4;
BA_ "UserSigValidity" SG_ 1096 SWRC_AlvCnt1Val 0;
BA_REL_ "GenSigTimeoutTime" BU_SG_REL_ CGW_CCU SG_ 1096 SWRC_AlvCnt1Val 1500;
BA_ "Version" SG_ 1096 SWRC_AlvCnt1Val "19.11.02";
BA_ "Description" SG_ 1096 Audio_VcRecSwSta "Audio Voice recognition switch



MM-CAN Gateway needed";
BA_ "GenSigSendType" SG_ 1096 Audio_VcRecSwSta 4;
BA_ "UserSigValidity" SG_ 1096 Audio_VcRecSwSta 0;
BA_REL_ "GenSigTimeoutTime" BU_SG_REL_ CGW_CCU SG_ 1096 Audio_VcRecSwSta 1500;
BA_ "NetworkRequest" SG_ 1096 Audio_VcRecSwSta 0;
BA_ "NetworkRequestHoldingTime" SG_ 1096 Audio_VcRecSwSta 5000;
BA_ "Version" SG_ 1096 Audio_VcRecSwSta "21.07.05";
BA_ "Description" SG_ 1096 Audio_BluetoothPhnClSwSta "Bluetooth phone call switch on/off



MM-CAN Gateway needed";
BA_ "GenSigSendType" SG_ 1096 Audio_BluetoothPhnClSwSta 4;
BA_ "UserSigValidity" SG_ 1096 Audio_BluetoothPhnClSwSta 0;
BA_REL_ "GenSigTimeoutTime" BU_SG_REL_ CGW_CCU SG_ 1096 Audio_BluetoothPhnClSwSta 1500;
BA_ "NetworkRequest" SG_ 1096 Audio_BluetoothPhnClSwSta 0;
BA_ "NetworkRequestHoldingTime" SG_ 1096 Audio_BluetoothPhnClSwSta 5000;
BA_ "Version" SG_ 1096 Audio_BluetoothPhnClSwSta "21.07.05";
BA_ "Description" SG_ 1096 Audio_BluetoothPhnHangUpSwSta "Bluetooth phone hang up switch on/off



MM-CAN Gateway needed";
BA_ "GenSigSendType" SG_ 1096 Audio_BluetoothPhnHangUpSwSta 4;
BA_ "UserSigValidity" SG_ 1096 Audio_BluetoothPhnHangUpSwSta 0;
BA_REL_ "GenSigTimeoutTime" BU_SG_REL_ CGW_CCU SG_ 1096 Audio_BluetoothPhnHangUpSwSta 1500;
BA_ "NetworkRequest" SG_ 1096 Audio_BluetoothPhnHangUpSwSta 0;
BA_ "NetworkRequestHoldingTime" SG_ 1096 Audio_BluetoothPhnHangUpSwSta 5000;
BA_ "Version" SG_ 1096 Audio_BluetoothPhnHangUpSwSta "19.11.02";
BA_ "Description" SG_ 1096 Audio_ModSwSta "Audio Mode switch



MM-CAN Gateway needed";
BA_ "GenSigSendType" SG_ 1096 Audio_ModSwSta 4;
BA_ "UserSigValidity" SG_ 1096 Audio_ModSwSta 0;
BA_REL_ "GenSigTimeoutTime" BU_SG_REL_ CGW_CCU SG_ 1096 Audio_ModSwSta 1500;
BA_ "NetworkRequest" SG_ 1096 Audio_ModSwSta 0;
BA_ "NetworkRequestHoldingTime" SG_ 1096 Audio_ModSwSta 5000;
BA_ "Version" SG_ 1096 Audio_ModSwSta "21.07.05";
BA_ "Description" SG_ 1096 Audio_MutSwSta "Audio Mute switch



MM-CAN Gateway needed";
BA_ "GenSigSendType" SG_ 1096 Audio_MutSwSta 4;
BA_ "UserSigValidity" SG_ 1096 Audio_MutSwSta 0;
BA_REL_ "GenSigTimeoutTime" BU_SG_REL_ CGW_CCU SG_ 1096 Audio_MutSwSta 1500;
BA_ "NetworkRequest" SG_ 1096 Audio_MutSwSta 0;
BA_ "NetworkRequestHoldingTime" SG_ 1096 Audio_MutSwSta 5000;
BA_ "Version" SG_ 1096 Audio_MutSwSta "19.11.02";
BA_ "Description" SG_ 1096 Audio_SeekDnSwSta "Audio Seek Down switch



MM-CAN Gateway needed";
BA_ "GenSigSendType" SG_ 1096 Audio_SeekDnSwSta 4;
BA_ "UserSigValidity" SG_ 1096 Audio_SeekDnSwSta 0;
BA_REL_ "GenSigTimeoutTime" BU_SG_REL_ CGW_CCU SG_ 1096 Audio_SeekDnSwSta 1500;
BA_ "NetworkRequest" SG_ 1096 Audio_SeekDnSwSta 0;
BA_ "NetworkRequestHoldingTime" SG_ 1096 Audio_SeekDnSwSta 5000;
BA_ "Version" SG_ 1096 Audio_SeekDnSwSta "19.11.02";
BA_ "Description" SG_ 1096 Audio_SeekUpSwSta "Audio Seek Up switch



MM-CAN Gateway needed";
BA_ "GenSigSendType" SG_ 1096 Audio_SeekUpSwSta 4;
BA_ "UserSigValidity" SG_ 1096 Audio_SeekUpSwSta 0;
BA_REL_ "GenSigTimeoutTime" BU_SG_REL_ CGW_CCU SG_ 1096 Audio_SeekUpSwSta 1500;
BA_ "NetworkRequest" SG_ 1096 Audio_SeekUpSwSta 0;
BA_ "NetworkRequestHoldingTime" SG_ 1096 Audio_SeekUpSwSta 5000;
BA_ "Version" SG_ 1096 Audio_SeekUpSwSta "19.11.02";
BA_ "Description" SG_ 1096 Audio_VolDnSwSta "Audio Volume Down switch



MM-CAN Gateway needed";
BA_ "GenSigSendType" SG_ 1096 Audio_VolDnSwSta 4;
BA_ "UserSigValidity" SG_ 1096 Audio_VolDnSwSta 0;
BA_REL_ "GenSigTimeoutTime" BU_SG_REL_ CGW_CCU SG_ 1096 Audio_VolDnSwSta 1500;
BA_ "NetworkRequest" SG_ 1096 Audio_VolDnSwSta 0;
BA_ "NetworkRequestHoldingTime" SG_ 1096 Audio_VolDnSwSta 5000;
BA_ "Version" SG_ 1096 Audio_VolDnSwSta "19.11.02";
BA_ "Description" SG_ 1096 Audio_VolUpSwSta "Audio Volume Up switch



MM-CAN Gateway needed";
BA_ "GenSigSendType" SG_ 1096 Audio_VolUpSwSta 4;
BA_ "UserSigValidity" SG_ 1096 Audio_VolUpSwSta 0;
BA_REL_ "GenSigTimeoutTime" BU_SG_REL_ CGW_CCU SG_ 1096 Audio_VolUpSwSta 1500;
BA_ "NetworkRequest" SG_ 1096 Audio_VolUpSwSta 0;
BA_ "NetworkRequestHoldingTime" SG_ 1096 Audio_VolUpSwSta 5000;
BA_ "Version" SG_ 1096 Audio_VolUpSwSta "19.11.02";
BA_ "Description" SG_ 1096 Cluster_ModeSwSta "Cluster Mode switch";
BA_ "GenSigSendType" SG_ 1096 Cluster_ModeSwSta 4;
BA_ "UserSigValidity" SG_ 1096 Cluster_ModeSwSta 0;
BA_REL_ "GenSigTimeoutTime" BU_SG_REL_ CGW_CCU SG_ 1096 Cluster_ModeSwSta 1500;
BA_ "NetworkRequest" SG_ 1096 Cluster_ModeSwSta 0;
BA_ "NetworkRequestHoldingTime" SG_ 1096 Cluster_ModeSwSta 5000;
BA_ "Version" SG_ 1096 Cluster_ModeSwSta "21.07.05";
BA_ "GenSigSendType" SG_ 1096 Cluster_ScrlDnSwSta 4;
BA_ "UserSigValidity" SG_ 1096 Cluster_ScrlDnSwSta 0;
BA_REL_ "GenSigTimeoutTime" BU_SG_REL_ CGW_CCU SG_ 1096 Cluster_ScrlDnSwSta 1500;
BA_ "NetworkRequest" SG_ 1096 Cluster_ScrlDnSwSta 0;
BA_ "NetworkRequestHoldingTime" SG_ 1096 Cluster_ScrlDnSwSta 5000;
BA_ "Version" SG_ 1096 Cluster_ScrlDnSwSta "19.11.02";
BA_ "GenSigSendType" SG_ 1096 Cluster_ScrlOkSwSta 4;
BA_ "UserSigValidity" SG_ 1096 Cluster_ScrlOkSwSta 0;
BA_REL_ "GenSigTimeoutTime" BU_SG_REL_ CGW_CCU SG_ 1096 Cluster_ScrlOkSwSta 1500;
BA_ "NetworkRequest" SG_ 1096 Cluster_ScrlOkSwSta 0;
BA_ "NetworkRequestHoldingTime" SG_ 1096 Cluster_ScrlOkSwSta 5000;
BA_ "Version" SG_ 1096 Cluster_ScrlOkSwSta "19.11.02";
BA_ "GenSigSendType" SG_ 1096 Cluster_ScrlUpSwSta 4;
BA_ "UserSigValidity" SG_ 1096 Cluster_ScrlUpSwSta 0;
BA_REL_ "GenSigTimeoutTime" BU_SG_REL_ CGW_CCU SG_ 1096 Cluster_ScrlUpSwSta 1500;
BA_ "NetworkRequest" SG_ 1096 Cluster_ScrlUpSwSta 0;
BA_ "NetworkRequestHoldingTime" SG_ 1096 Cluster_ScrlUpSwSta 5000;
BA_ "Version" SG_ 1096 Cluster_ScrlUpSwSta "19.11.02";
BA_ "Description" SG_ 1096 Audio_CustomSwSta "Audio Custom switch MM-CAN Gateway needed";
BA_ "GenSigSendType" SG_ 1096 Audio_CustomSwSta 4;
BA_ "UserSigValidity" SG_ 1096 Audio_CustomSwSta 0;
BA_REL_ "GenSigTimeoutTime" BU_SG_REL_ CGW_CCU SG_ 1096 Audio_CustomSwSta 1500;
BA_ "NetworkRequest" SG_ 1096 Audio_CustomSwSta 0;
BA_ "NetworkRequestHoldingTime" SG_ 1096 Audio_CustomSwSta 5000;
BA_ "Version" SG_ 1096 Audio_CustomSwSta "21.07.05";
BA_ "Description" SG_ 1096 Cluster_ModeCCW "Cluster Menu Control (Back Key)";
BA_ "GenSigSendType" SG_ 1096 Cluster_ModeCCW 4;
BA_ "UserSigValidity" SG_ 1096 Cluster_ModeCCW 0;
BA_REL_ "GenSigTimeoutTime" BU_SG_REL_ CGW_CCU SG_ 1096 Cluster_ModeCCW 1500;
BA_ "NetworkRequest" SG_ 1096 Cluster_ModeCCW 0;
BA_ "NetworkRequestHoldingTime" SG_ 1096 Cluster_ModeCCW 5000;
BA_ "Version" SG_ 1096 Cluster_ModeCCW "21.07.05";
BA_ "Description" SG_ 1096 Cluster_TripDnSwSta "Cluster Menu Control(Down)

 - tumbler, button type";
BA_ "GenSigSendType" SG_ 1096 Cluster_TripDnSwSta 4;
BA_ "UserSigValidity" SG_ 1096 Cluster_TripDnSwSta 0;
BA_REL_ "GenSigTimeoutTime" BU_SG_REL_ CGW_CCU SG_ 1096 Cluster_TripDnSwSta 1500;
BA_ "NetworkRequest" SG_ 1096 Cluster_TripDnSwSta 0;
BA_ "NetworkRequestHoldingTime" SG_ 1096 Cluster_TripDnSwSta 5000;
BA_ "Version" SG_ 1096 Cluster_TripDnSwSta "19.11.02";
BA_ "Description" SG_ 1096 Cluster_TripUpSwSta "Cluster Menu Control(Up)

 - Tumbler, button type";
BA_ "GenSigSendType" SG_ 1096 Cluster_TripUpSwSta 4;
BA_ "UserSigValidity" SG_ 1096 Cluster_TripUpSwSta 0;
BA_REL_ "GenSigTimeoutTime" BU_SG_REL_ CGW_CCU SG_ 1096 Cluster_TripUpSwSta 1500;
BA_ "NetworkRequest" SG_ 1096 Cluster_TripUpSwSta 0;
BA_ "NetworkRequestHoldingTime" SG_ 1096 Cluster_TripUpSwSta 5000;
BA_ "Version" SG_ 1096 Cluster_TripUpSwSta "19.11.02";
BA_ "Description" SG_ 1096 Cluster_TripOkSwSta "Cluter Menu Control(OK)

 - tumbler, button type";
BA_ "GenSigSendType" SG_ 1096 Cluster_TripOkSwSta 4;
BA_ "UserSigValidity" SG_ 1096 Cluster_TripOkSwSta 0;
BA_REL_ "GenSigTimeoutTime" BU_SG_REL_ CGW_CCU SG_ 1096 Cluster_TripOkSwSta 1500;
BA_ "NetworkRequest" SG_ 1096 Cluster_TripOkSwSta 0;
BA_ "NetworkRequestHoldingTime" SG_ 1096 Cluster_TripOkSwSta 5000;
BA_ "Version" SG_ 1096 Cluster_TripOkSwSta "19.11.02";
BA_ "Description" SG_ 1096 SWRC_OpticalSwSnstvtSta "Current setting value for Optical Switch Sensitivity";
BA_ "GenSigSendType" SG_ 1096 SWRC_OpticalSwSnstvtSta 4;
BA_ "GenSigStartValue" SG_ 1096 SWRC_OpticalSwSnstvtSta 3;
BA_ "UserSigValidity" SG_ 1096 SWRC_OpticalSwSnstvtSta 0;
BA_REL_ "GenSigTimeoutTime" BU_SG_REL_ CGW_CCU SG_ 1096 SWRC_OpticalSwSnstvtSta 1500;
BA_ "Version" SG_ 1096 SWRC_OpticalSwSnstvtSta "19.12.00";
BA_ "GenSigSendType" SG_ 1096 SWRC_RhOpticalSwSta 4;
BA_ "UserSigValidity" SG_ 1096 SWRC_RhOpticalSwSta 0;
BA_REL_ "GenSigTimeoutTime" BU_SG_REL_ CGW_CCU SG_ 1096 SWRC_RhOpticalSwSta 1500;
BA_ "Version" SG_ 1096 SWRC_RhOpticalSwSta "19.11.02";
BA_ "Description" SG_ 1096 Audio_CustomSw3Sta "Audio Custom switch MM-CAN Gateway needed";
BA_ "GenSigSendType" SG_ 1096 Audio_CustomSw3Sta 4;
BA_ "UserSigValidity" SG_ 1096 Audio_CustomSw3Sta 0;
BA_REL_ "GenSigTimeoutTime" BU_SG_REL_ CGW_CCU SG_ 1096 Audio_CustomSw3Sta 1500;
BA_ "NetworkRequest" SG_ 1096 Audio_CustomSw3Sta 0;
BA_ "NetworkRequestHoldingTime" SG_ 1096 Audio_CustomSw3Sta 5000;
BA_ "Version" SG_ 1096 Audio_CustomSw3Sta "21.07.05";
BA_ "GenMsgSendType" BO_ 1099 0;
BA_ "Description" SG_ 1099 USM_CmdWPCSta "USM request value of WPC";
BA_ "GenSigSendType" SG_ 1099 USM_CmdWPCSta 4;
BA_ "UserSigValidity" SG_ 1099 USM_CmdWPCSta 0;
BA_REL_ "GenSigTimeoutTime" BU_SG_REL_ CGW_CCU SG_ 1099 USM_CmdWPCSta 1500;
BA_ "NetworkRequest" SG_ 1099 USM_CmdWPCSta 0;
BA_ "NetworkRequestHoldingTime" SG_ 1099 USM_CmdWPCSta 5000;
BA_ "Version" SG_ 1099 USM_CmdWPCSta "17.11.00";
BA_ "Description" SG_ 1099 WPC_SWVerMajor1 "Indicate the WPC software version as follows:

- The software version is displayed in three digits.

- The Major and Minor digits are separated by '.'

- Signal values are transmitted to ASCII codes.



¡Ø Example

WPC_SWVerMajor1 : 0x41 (HEX) -> ASCII CODE : 'A' 

WPC_SWVerMinor1 : 0x30 (HEX) -> ASCII CODE : '0'

WPC_SWVerMinor2 : 0x33 (HEX) -> ASCII CODE : '3'

=> WPC S/W Ver is displayed 'A.03'";
BA_ "GenSigSendType" SG_ 1099 WPC_SWVerMajor1 4;
BA_ "UserSigValidity" SG_ 1099 WPC_SWVerMajor1 0;
BA_REL_ "GenSigTimeoutTime" BU_SG_REL_ CGW_CCU SG_ 1099 WPC_SWVerMajor1 1500;
BA_ "Version" SG_ 1099 WPC_SWVerMajor1 "20.12.04";
BA_ "Description" SG_ 1099 WPC_PhnLftWrngSta "Warning by WPC for User (Phone left in vehicle)";
BA_ "GenSigSendType" SG_ 1099 WPC_PhnLftWrngSta 4;
BA_ "UserSigValidity" SG_ 1099 WPC_PhnLftWrngSta 0;
BA_REL_ "GenSigTimeoutTime" BU_SG_REL_ CGW_CCU SG_ 1099 WPC_PhnLftWrngSta 1500;
BA_ "NetworkRequest" SG_ 1099 WPC_PhnLftWrngSta 0;
BA_ "NetworkRequestHoldingTime" SG_ 1099 WPC_PhnLftWrngSta 5000;
BA_ "Version" SG_ 1099 WPC_PhnLftWrngSta "18.02.03";
BA_ "Description" SG_ 1099 WPC_SWVerMinor1 "Indicate the WPC software version as follows:

- The software version is displayed in three digits.

- The Major and Minor digits are separated by '.'

- Signal values are transmitted to ASCII codes.



¡Ø Example

WPC_SWVerMajor1 : 0x41 (HEX) -> ASCII CODE : 'A' 

WPC_SWVerMinor1 : 0x30 (HEX) -> ASCII CODE : '0'

WPC_SWVerMinor2 : 0x33 (HEX) -> ASCII CODE : '3'

=> WPC S/W Ver is displayed 'A.03'";
BA_ "GenSigSendType" SG_ 1099 WPC_SWVerMinor1 4;
BA_ "UserSigValidity" SG_ 1099 WPC_SWVerMinor1 0;
BA_REL_ "GenSigTimeoutTime" BU_SG_REL_ CGW_CCU SG_ 1099 WPC_SWVerMinor1 1500;
BA_ "Version" SG_ 1099 WPC_SWVerMinor1 "18.10.06";
BA_ "Description" SG_ 1099 WPC_SWVerMinor2 "Indicate the WPC software version as follows:

- The software version is displayed in three digits.

- The Major and Minor digits are separated by '.'

- Signal values are transmitted to ASCII codes.



¡Ø Example

WPC_SWVerMajor1 : 0x41 (HEX) -> ASCII CODE : 'A' 

WPC_SWVerMinor1 : 0x30 (HEX) -> ASCII CODE : '0'

WPC_SWVerMinor2 : 0x33 (HEX) -> ASCII CODE : '3'

=> WPC S/W Ver is displayed 'A.03'";
BA_ "GenSigSendType" SG_ 1099 WPC_SWVerMinor2 4;
BA_ "UserSigValidity" SG_ 1099 WPC_SWVerMinor2 0;
BA_REL_ "GenSigTimeoutTime" BU_SG_REL_ CGW_CCU SG_ 1099 WPC_SWVerMinor2 1500;
BA_ "Version" SG_ 1099 WPC_SWVerMinor2 "18.10.06";
VAL_ 2223057410 FCA_LO_WrnSta 0 "No Warning" 1 "Left Warning" 2 "Right Warning" 3 "Left Control" 4 "Right Control" 5 "Reserved" 6 "Reserved" 7 "Error indicator" ;
VAL_ 2223057410 LKA_UsmMod 0 "NONE" 1 "LKA 1 mode" 2 "Reserved" 3 "LDW" ;
VAL_ 2223057410 ELK_SysFlrSta 0 "No Warning" 1 "Temp, Unavailable by Camera" 2 "Temp, Unavailable by Radar" 3 "Service Required" 4 "Reserved" 5 "Reserved" 6 "Reserved" 7 "Reserved" ;
VAL_ 2223057410 ELK_SymbDisp 0 "Default" 1 "No warning" 2 "ELK Amber warning on" 3 "ELK Red warning blingking" 4 "ELK Gray warning on" 5 "Reserved" 6 "Reserved" 7 "Reserved" ;
VAL_ 2223057410 FCA_ESA_WrnSta 0 "No Warning" 1 "Reserved" 2 "Reserved" 3 "Left Control" 4 "Right Control" 5 "Reserved" 6 "Reserved" 7 "Error Indicator" ;
VAL_ 2223057410 ADAS_ActAciSta 0 "Reserved" 1 "Standby" 2 "Active" 3 "Redundancy" 4 "Abort" 5 "Fail" ;
VAL_ 2223057410 FCA_ESA_CtrlSta 0 "No Control" 1 "FCA 1st Warning" 2 "FCA w/ ESA Driver Initiated Control" 3 "FCA w/ ESA Auto Control Step 1" 4 "FCA w/ ESA Auto Control Step 2" 5 "FCA w/ ESA Auto Control Step 3" 6 "Reserved" 7 "Error Indicator" ;
VAL_ 2223057410 FCA_LS_WrnSta 0 "No Warning" 1 "Left Warning" 2 "Right Warning" 3 "Left Control" 4 "Right Control" 5 "Reserved" 6 "Reserved" 7 "Error indicator" ;
VAL_ 2223057410 ADAS_Damping_Gain 0 "Reserved" 1 "Reserved" 2 "Reserved" 3 "0x3~0xC8:3 ~ 200%" 200 "0x3~0xC8:3 ~ 200%" 201 "Reserved" 202 "Reserved" 203 "Reserved" 204 "Reserved" 205 "Reserved" 206 "Reserved" 207 "Reserved" 208 "Reserved" 209 "Reserved" 210 "Reserved" 211 "Reserved" 212 "Reserved" 213 "Reserved" 214 "Reserved" 215 "Reserved" 216 "Reserved" 217 "Reserved" 218 "Reserved" 219 "Reserved" 220 "Reserved" 221 "Reserved" 222 "Reserved" 223 "Reserved" 224 "Reserved" 225 "Reserved" 226 "Reserved" 227 "Reserved" 228 "Reserved" 229 "Reserved" 230 "Reserved" 231 "Reserved" 232 "Reserved" 233 "Reserved" 234 "Reserved" 235 "Reserved" 236 "Reserved" 237 "Reserved" 238 "Reserved" 239 "Reserved" 240 "Reserved" 241 "Reserved" 242 "Reserved" 243 "Reserved" 244 "Reserved" 245 "Reserved" 246 "Reserved" 247 "Reserved" 248 "Reserved" 249 "Reserved" 250 "Reserved" 251 "Reserved" 252 "Reserved" 253 "Reserved" 254 "Reserved" 255 "Reserved" ;
VAL_ 2223057410 LKA_OnOffEquip2Sta 0 "Default" 1 "Off" 2 "On" 3 "Invalid" ;
VAL_ 1119 APSS_SldTch 0 "Off" 1 "On" 2 "Not Used" 3 "Error" ;
VAL_ 1119 APSS_RclTch 0 "Off" 1 "On" 2 "Not Used" 3 "Error" ;
VAL_ 1119 APSS_LmbrTch 0 "Off" 1 "On" 2 "Not Used" 3 "Error" ;
VAL_ 1119 APSS_ExtTch 0 "Default" 1 "Off" 2 "On" 3 "Invalid" ;
VAL_ 1133 APSU_AstStEsyAcsUSMSta 0 "Default Value" 1 "Off (Disable)" 2 "50mmOn (Enable)" 3 "75mmOn (Enable)" 4 "Reserved" 5 "Reserved" 6 "Reserved" 7 "Invalid" ;
VAL_ 1133 APSU_AstReturnModeSta 0 "Default" 1 "Off" 2 "Stop" 3 "Moving" 4 "Finish" 5 "Invalid" ;
VAL_ 1133 APSU_CntryConfigTyp 0 "Dom" 1 "Na" 2 "Eu" 3 "Aus" 4 "China" 5 "Gen,Mes" 6 "India" 7 "RESERVED" 8 "RESERVED" 9 "RESERVED" 10 "RESERVED" 11 "RESERVED" 12 "RESERVED" 13 "RESERVED" 15 "Error Indicator" ;
VAL_ 1133 APSU_AutoHtrCtrlUSMSta 0 "Default" 1 "Off" 2 "On" 3 "Invalid" ;
VAL_ 1133 APSU_HtBlcUSMSta 0 "Default" 1 "Normal" 2 "Back 1" 3 "Back 2" 4 "Back 3" 5 "Cush 1" 6 "Cush 2" 7 "Cush 3" 8 "Reserved" 9 "Reserved" 10 "Reserved" 11 "Reserved" 12 "Reserved" 13 "Reserved" 14 "Reserved" 15 "Invalid" ;
VAL_ 1133 APSU_AstAntPncMod 0 "Default" 1 "Off" 2 "On" 3 "Invalid" ;
VAL_ 1133 APSU_AstOneTchFldModSta 0 "Default" 1 "Off" 2 "Reclining FWD" 3 "Reclining BWD" 4 "Folding Mode" 5 "Unfolding Mode" 6 "Reserved" 7 "Invalid" ;
VAL_ 1133 APSU_AstOneTchOperSta 0 "Default" 1 "Off" 2 "Ready" 3 "Move" 4 "Finished" 5 "Reserved" 6 "Reserved" 7 "Invalid" ;
VAL_ 1133 APSU_AstRelaxModeSta 0 "Default" 1 "Off" 2 "Stop" 3 "Moving" 4 "Finish" 5 "Invalid" ;
VAL_ 1134 APSU_AstStSldFwdDis 0 "default" 1 "off" 2 "on" 3 "invalid" ;
VAL_ 1134 APSU_AstStTiltDnDis 0 "default" 1 "off" 2 "on" 3 "invalid" ;
VAL_ 1134 APSU_AstStHghtUpDis 0 "default" 1 "off" 2 "on" 3 "invalid" ;
VAL_ 1134 APSU_AstStHghtDnDis 0 "default" 1 "off" 2 "on" 3 "invalid" ;
VAL_ 1134 APSU_AstStLegUpDis 0 "default" 1 "off" 2 "on" 3 "invalid" ;
VAL_ 1134 APSU_AstStLegtDnDis 0 "default" 1 "off" 2 "on" 3 "invalid" ;
VAL_ 1134 APSU_AstStSldBckwdDis 0 "default" 1 "off" 2 "on" 3 "invalid" ;
VAL_ 1134 APSU_AstStRlxTiltUpDis 0 "default" 1 "off" 2 "on" 3 "invalid" ;
VAL_ 1134 APSU_AstStRlxTiltDnDis 0 "default" 1 "off" 2 "on" 3 "invalid" ;
VAL_ 1134 APSU_AstStCushExtBckwdDis 0 "default" 1 "off" 2 "on" 3 "invalid" ;
VAL_ 1134 APSU_AstStCushExtFwdDis 0 "default" 1 "off" 2 "on" 3 "invalid" ;
VAL_ 1134 APSU_AstStLmbrDefDis 0 "default" 1 "off" 2 "on" 3 "invalid" ;
VAL_ 1134 APSU_AstStLmbrLoDis 0 "default" 1 "off" 2 "on" 3 "invalid" ;
VAL_ 1134 APSU_AstStLmbrMdlDis 0 "default" 1 "off" 2 "on" 3 "invalid" ;
VAL_ 1134 APSU_AstStLmbrUpDis 0 "default" 1 "off" 2 "on" 3 "invalid" ;
VAL_ 1134 APSU_AstStReclneFwdDis 0 "default" 1 "off" 2 "on" 3 "invalid" ;
VAL_ 1134 APSU_LmbrSigSrcTyp 0 "not APSU" 1 "APSU" 2 "reserved" 3 "invalid" ;
VAL_ 1134 APSU_APSUOpt 0 "Default" 1 "Non-APSU" 2 "APSU" 3 "Invalid" ;
VAL_ 1134 APSU_AstStReclneBckwdDis 0 "default" 1 "off" 2 "on" 3 "invalid" ;
VAL_ 1134 APSU_AstStTiltUpDis 0 "default" 1 "off" 2 "on" 3 "invalid" ;
VAL_ 1095 ATS_BeepSound 0 "Off" 1 "On" 2 "Reserved" 3 "Invalid" ;
VAL_ 1095 ATS_RRMsgTimeSW 0 "Default" 1 "Short" 2 "Medium" 3 "Long" 4 "Reserved" 5 "Reserved" 6 "Reserved" 7 "Invalid" ;
VAL_ 1095 ATS_FAUMsgModeSW 0 "Default" 1 "Off" 2 "On" 3 "Invalid" ;
VAL_ 1095 ATS_FAUMsgHeatModeSW 0 "Default" 1 "Off" 2 "On" 3 "Invalid" ;
VAL_ 1095 ATS_RLMsgMod1SW 0 "Default" 1 "Short On" 2 "Long On" 3 "Invalid" ;
VAL_ 1095 ATS_RWPC_RWPCNValueSet 0 "Default" 1 "Off" 2 "On" 3 "Invalid" ;
VAL_ 1095 ATS_RLMsgMod2SW 0 "Default" 1 "Short On" 2 "Long On" 3 "Invalid" ;
VAL_ 1095 ATS_RLMsgMod3SW 0 "Default" 1 "Short On" 2 "Long On" 3 "Invalid" ;
VAL_ 1095 ATS_RLMsgMod4SW 0 "Default" 1 "Short On" 2 "Long On" 3 "Invalid" ;
VAL_ 1095 ATS_RRMsgMod1SW 0 "Default" 1 "Short On" 2 "Long On" 3 "Invalid" ;
VAL_ 1095 ATS_RRMsgMod2SW 0 "Default" 1 "Short On" 2 "Long On" 3 "Invalid" ;
VAL_ 1095 ATS_RRMsgMod3SW 0 "Default" 1 "Short On" 2 "Long On" 3 "Invalid" ;
VAL_ 1095 ATS_RRMsgMod4SW 0 "Default" 1 "Short On" 2 "Long On" 3 "Invalid" ;
VAL_ 1095 ATS_RLEasyAccessSW 0 "Default" 1 "Off" 2 "On" 3 "Invalid" ;
VAL_ 1095 ATS_RREasyAccessSW 0 "Default" 1 "Off" 2 "On" 3 "Invalid" ;
VAL_ 1095 ATS_RLMsgTimeSW 0 "Default" 1 "Short" 2 "Medium" 3 "Long" 4 "Reserved" 5 "Reserved" 6 "Reserved" 7 "Invalid" ;
VAL_ 1090 BCM_SmkOptTyp 0 "Non SMK Option" 1 "SMK Option" 2 "Not Used" 3 "Error Indicator" ;
VAL_ 1090 PHEV_FuelDrOpnSta 0 "Close" 1 "Open" 2 "Not Used" 3 "Error Indicator" ;
VAL_ 1090 BCM_SunRoofOptTyp 0 "NONE" 1 "Sunroof applied" 2 "reserved" 3 "Invalid" ;
VAL_ 1090 Window_DrvrSdWdwSta_BCM 0 "Window Close" 1 "Window Open" 2 "Not Used" 3 "Error Indicator" ;
VAL_ 1090 Window_AsstSdWdwSta_BCM 0 "Window Close" 1 "Window Open" 2 "Not Used" 3 "Error Indicator" ;
VAL_ 1090 Window_RrLftWdwSta_BCM 0 "Window Close" 1 "Window Open" 2 "Not Used" 3 "Error Indicator" ;
VAL_ 1090 Window_RrRtWdwSta_BCM 0 "Window Close" 1 "Window Open" 2 "Not Used" 3 "Error Indicator" ;
VAL_ 1090 SunRoof_GlassPosSta 0 "Glass Tilt up" 1 "Glass Vent area" 2 "Glass Anti pinch in vent" 3 "Glass Fully close" 4 "Glass Anti pinch in partially slide" 5 "Glass Partially slide" 6 "Glass Fully open" 7 "Glass Uninitialized" 8 "Reserved" 9 "Reserved" 10 "Reserved" 11 "Reserved" 12 "Reserved" 13 "Reserved" 14 "Reserved" 15 "invalid" ;
VAL_ 1090 PHEV_FuelDrDis 0 "Off" 1 "Fuel Door Open Wait" 2 "Refueling Ready(Fuel Door Open)" 3 "Check Fuel Door" 4 "Charging" 5 "Fuel Door Not Open" 6 "Not Used" 7 "Error Indicator" ;
VAL_ 1090 SunRoof_BlindPosSta 0 "BLIND_HALF_OPEN" 1 "BLIND_LESS_THEN_HALF_OPEN" 2 "BLIND_ANTIPINCH_LESS_THAN_HALF_OPEN" 3 "BLIND_FULLY_CLOSE" 4 "BLIND_ANTIPINCH_MORE_THAN_HALF_OPEN" 5 "BLIND_MORE_THAN_HALF_OPEN" 6 "BLIND_FULLY_OPEN" 7 "BLIND_UNINITIALIZED" 8 "Reserved" 9 "Reserved" 10 "Reserved" 11 "Reserved" 12 "Reserved" 13 "Reserved" 14 "Reserved" 15 "invalid" ;
VAL_ 1090 SunRoof_GlassErrSta 0 "Glass No error" 1 "Glass Thermal Protection Active" 2 "Glass Initialized Status" 3 "Glass Undefined ECU Error" 4 "Glass Switch Error" 5 "Glass Voltage error" 6 "Complex Error" 7 "invalid" ;
VAL_ 1090 SunRoof_BlindErrSta 0 "Roll Blind No error" 1 "Roll Blind Thermal Protection Active" 2 "Roll Blind Initialized Status" 3 "Roll Blind Undefined ECU Error" 4 "Roll Blind Switch Error" 5 "Roll Blind Voltage error" 6 "Complex Error" 7 "invalid" ;
VAL_ 1097 StrWhlWrmr_HtngCmd 0 "Off" 1 "1 Step On" 2 "2 Step On" 3 "Error Indicator" ;
VAL_ 1097 StrWhlWrmr_HtngReqState 0 "Off" 1 "ManualOn" 2 "MKBDOn" 3 "VoiceOn" 4 "CCSOn" 5 "DATCOn" 6 "DATCToNormalOn" 7 "Not Used" 8 "Not Used" 9 "Not Used" 10 "Not Used" 11 "Not Used" 12 "Not Used" 13 "Not Used" 14 "Not Used" 15 "Error Indicator" ;
VAL_ 1097 StrWhlWrmr_IndCmd 0 "Off" 1 "1 Step On" 2 "2 Step On" 3 "Error Indicator" ;
VAL_ 1097 PHEV_FuelDrCtrlFlag 0 "Default (Fuel Door Open Control Not Running)" 1 "Fuel Door Open Control Running" 2 "Not Used" 3 "Error Indicator" ;
VAL_ 1097 Haptic_USMCurState_OnOff 0 "Default" 1 "On" 2 "Off" 3 "Error Indicator" ;
VAL_ 1097 Haptic_ADASAutoOnSetReq 0 "Default" 1 "Active" 2 "Not Used" 3 "Error Indicator" ;
VAL_ 1097 HeatedSteerWheel_StrWhlHtrSwSta_BCM 0 "Off" 1 "On" 2 "Not Used" 3 "Error Indicator" ;
VAL_ 1097 Haptic_WrngCmd 0 "Off" 1 "On" 2 "Not Used" 3 "Error Indicator" ;
VAL_ 2202063617 CCU_OTA_Update_time 0 "Default" 1 "0x0001~0xFFFF:update time" 65535 "0x0001~0xFFFF:update time" ;
VAL_ 2202063617 CCU_OTA_Update_Current 0 "Default" 1 "0x0001~0xFFFF:current" 65535 "0x0001~0xFFFF:current" ;
VAL_ 2202063617 CCU_Update_Calfactor 0 "Default" 1 "Target SOC" 2 "Target SOC" 3 "Target SOC" 4 "Target SOC" 5 "Target SOC" 6 "Target SOC" 7 "Target SOC" 8 "Target SOC" 9 "Target SOC" 10 "Target SOC" 11 "Target SOC" 12 "Target SOC" 13 "Target SOC" 14 "Target SOC" 15 "Target SOC" 16 "Target SOC" 17 "Target SOC" 18 "Target SOC" 19 "Target SOC" 20 "Target SOC" 21 "Target SOC" 22 "Target SOC" 23 "Target SOC" 24 "Target SOC" 25 "Target SOC" 26 "Target SOC" 27 "Target SOC" 28 "Target SOC" 29 "Target SOC" 30 "Target SOC" 31 "Target SOC" 32 "Target SOC" 33 "Target SOC" 34 "Target SOC" 35 "Target SOC" 36 "Target SOC" 37 "Target SOC" 38 "Target SOC" 39 "Target SOC" 40 "Target SOC" 41 "Target SOC" 42 "Target SOC" 43 "Target SOC" 44 "Target SOC" 45 "Target SOC" 46 "Target SOC" 47 "Target SOC" 48 "Target SOC" 49 "Target SOC" 50 "Target SOC" 51 "Target SOC" 52 "Target SOC" 53 "Target SOC" 54 "Target SOC" 55 "Target SOC" 56 "Target SOC" 57 "Target SOC" 58 "Target SOC" 59 "Target SOC" 60 "Target SOC" 61 "Target SOC" 62 "Target SOC" 63 "Target SOC" 64 "Target SOC" 65 "Target SOC" 66 "Target SOC" 67 "Target SOC" 68 "Target SOC" 69 "Target SOC" 70 "Target SOC" 71 "Target SOC" 72 "Target SOC" 73 "Target SOC" 74 "Target SOC" 75 "Target SOC" 76 "Target SOC" 77 "Target SOC" 78 "Target SOC" 79 "Target SOC" 80 "Target SOC" 81 "Target SOC" 82 "Target SOC" 83 "Target SOC" 84 "Target SOC" 85 "Target SOC" 86 "Target SOC" 87 "Target SOC" 88 "Target SOC" 89 "Target SOC" 90 "Target SOC" 91 "Target SOC" 92 "Target SOC" 93 "Target SOC" 94 "Target SOC" 95 "Target SOC" 96 "Target SOC" 97 "Target SOC" 98 "Target SOC" 99 "Target SOC" 100 "Target SOC" 101 "0x65~0xFF:Reserved" 255 "0x65~0xFF:Reserved" ;
VAL_ 2395189505 DATC_FragranceStrhSta 0 "Default" 1 "Off" 2 "Low" 3 "Medium" 4 "High" 5 "Reserved" 6 "Reserved" 7 "Error Indicator" ;
VAL_ 2395189505 DATC_FragranceKindSta 0 "Default" 1 "First" 2 "Second" 3 "Reserved" 4 "Reserved" 5 "Reserved" 6 "Reserved" 7 "Error Indicator" ;
VAL_ 2395189505 DATC_AfterBlowOpSta 0 "Default" 1 "Not Operation Status" 2 "Operation Status" 3 "Error Indicator" ;
VAL_ 2395189505 DATC_RrBlwDis 0 "OFF" 1 "Blank Display(Blower ´Ü¼ö ¹ÌÇ¥½Ã, ¿¹)Auto ½Ã)" 2 "1 Step" 3 "2 Step" 4 "3 Step" 5 "4 Step" 6 "5 Step" 7 "6 Step" 8 "7 Step" 9 "8 Step" 10 "BLOWER AUTO" 11 "Reserved" 12 "Reserved" 13 "Reserved" 14 "Reserved" 15 "Error Indicator" ;
VAL_ 2395189505 DATC_RrClmtAutoOffUSMSta 0 "Default" 1 "Off" 2 "On" 3 "Error Indicator" ;
VAL_ 2395189505 DATC_ArClnSysOSD 0 "Default (Initial Value)" 1 "AirCleaning SYS ON" 2 "AirCleaning SYS OFF" 3 "High Dust AirCleaning ON" 4 "High Dust AirCleaning OFF" 5 "Sensor AirCleaning SYS ON & Closing Window" 6 "Opening Warning" 7 "Reserved" 8 "Reserved" 9 "Reserved" 10 "Reserved" 11 "Reserved" 12 "Reserved" 13 "Reserved" 14 "Reserved" 15 "Invalid" ;
VAL_ 2395189505 DATC_ArClnStepClr 0 "Default (Initial Value)" 1 "Mono Color" 2 "Blue Color" 3 "Green Color" 4 "Orange Color" 5 "Red Color" 6 "Yellow Color" 7 "Reserved" 8 "Reserved" 9 "Reserved" 10 "Reserved" 11 "Reserved" 12 "Reserved" 13 "Reserved" 14 "Gray Color (Deactivate)" 15 "Invalid" ;
VAL_ 2395189505 DATC_ArClnSmblTyp 0 "Default" 1 "Blank (Initial Display)" 2 "Wood" 3 "Wood & Fixed Arrow" 4 "Wood & Rotating Arrow" 5 "White Wood & Fixed Arrow" 6 "White Wood & Rotating Arrow" 7 "Invaild" ;
VAL_ 2395189505 DATC_AfterBlowUSMSta 0 "Default" 1 "After Blow USM OFF" 2 "After Blow USM ON" 3 "Error Indicator" ;
VAL_ 2395189505 DATC_SchdldVntUSMSta 0 "Default" 1 "OFF" 2 "ON" 3 "Error Indicator" ;
VAL_ 2395189505 DATC_SchdldVntHrSta 0 "Default" 1 "0hr" 2 "1hr" 3 "2hr" 4 "3hr" 5 "4hr" 6 "5hr" 7 "6hr" 8 "7hr" 9 "8hr" 10 "9hr" 11 "10hr" 12 "11hr" 13 "12hr" 14 "13hr" 15 "14hr" 16 "15hr" 17 "16hr" 18 "17hr" 19 "18hr" 20 "19hr" 21 "20hr" 22 "21hr" 23 "22hr" 24 "23hr" 25 "Reserved" 26 "Reserved" 27 "Reserved" 28 "Reserved" 29 "Reserved" 30 "Reserved" 31 "Error Indicator" ;
VAL_ 2395189505 DATC_SchdldVntMinSta 0 "Default" 1 "0 Min" 2 "10 Min" 3 "20 Min" 4 "30 Min" 5 "40 Min" 6 "50 Min" 7 "Error Indicator" ;
VAL_ 1130 DLBCU_LumbarUpDis 0 "default" 1 "off" 2 "on" 3 "invalid" ;
VAL_ 1130 DLBCU_LumbarMidDis 0 "default" 1 "off" 2 "on" 3 "invalid" ;
VAL_ 1130 DLBCU_LumbarLowDis 0 "default" 1 "off" 2 "on" 3 "invalid" ;
VAL_ 1130 DLBCU_LumbarDefDis 0 "default" 1 "off" 2 "on" 3 "invalid" ;
VAL_ 1131 DLBCU_BolsterInfDis 0 "default" 1 "off" 2 "on" 3 "invalid" ;
VAL_ 1131 DLBCU_BolsterDefDis 0 "default" 1 "off" 2 "on" 3 "invalid" ;
VAL_ 1132 DLBCU_CushInfDis 0 "default" 1 "off" 2 "on" 3 "invalid" ;
VAL_ 1132 DLBCU_CushDefDis 0 "default" 1 "off" 2 "on" 3 "invalid" ;
VAL_ 1127 DPSS_Crc1Val 0 "0x0x0~0xFF:CRCValue" 255 "0x0x0~0xFF:CRCValue" ;
VAL_ 1127 DPSS_AlvCnt1Val 0 "AlvCntValue" 1 "AlvCntValue" 2 "AlvCntValue" 3 "AlvCntValue" 4 "AlvCntValue" 5 "AlvCntValue" 6 "AlvCntValue" 7 "AlvCntValue" 8 "AlvCntValue" 9 "AlvCntValue" 10 "AlvCntValue" 11 "AlvCntValue" 12 "AlvCntValue" 13 "AlvCntValue" 14 "AlvCntValue" 15 "AlvCntValue" ;
VAL_ 1127 DPSS_StExtFwdMvBtn 0 "Default" 1 "Off" 2 "On" 3 "Invalid" ;
VAL_ 1127 DPSS_StExtBwdMvBtn 0 "Default" 1 "Off" 2 "On" 3 "Invaild" ;
VAL_ 1127 DPSS_StSldFwdMvBtn 0 "Default" 1 "Off" 2 "On" 3 "Invalid" ;
VAL_ 1127 DPSS_StSldBwdMvBtn 0 "Default" 1 "Off" 2 "On" 3 "Invalid" ;
VAL_ 1127 DPSS_StRclFwdMvBtn 0 "Default" 1 "Off" 2 "On" 3 "Invaild" ;
VAL_ 1127 DPSS_StRclBwdMvBtn 0 "Default" 1 "Off" 2 "On" 3 "Invalid" ;
VAL_ 1127 DPSS_StHgtUpMvBtn 0 "Default" 1 "Off" 2 "On" 3 "Invaild" ;
VAL_ 1127 DPSS_StHgtDnMvBtn 0 "Default" 1 "Off" 2 "On" 3 "Invalid" ;
VAL_ 1127 DPSS_StTltUpMvBtn 0 "Default" 1 "Off" 2 "On" 3 "Invalid" ;
VAL_ 1127 DPSS_StTltDnMvBtn 0 "Default" 1 "Off" 2 "On" 3 "Invalid" ;
VAL_ 1127 DPSS_StHRestUpMvBtn 0 "Default" 1 "Off" 2 "On" 3 "Invalid" ;
VAL_ 1127 DPSS_StHRestDnMvBtn 0 "Default" 1 "Off" 2 "On" 3 "Invalid" ;
VAL_ 1127 DPSS_StHRestFwdMvBtn 0 "Default" 1 "Off" 2 "On" 3 "Invalid" ;
VAL_ 1127 DPSS_StHRestBwdMvBtn 0 "Default" 1 "Off" 2 "On" 3 "Invalid" ;
VAL_ 1127 DPSS_StLegUpMvBtn 0 "Default" 1 "Off" 2 "On" 3 "Invalid" ;
VAL_ 1127 DPSS_StLegDnMvBtn 0 "Default" 1 "Off" 2 "On" 3 "Invalid" ;
VAL_ 1127 DPSS_StRlxModeBtn 0 "Default" 1 "Off" 2 "On" 3 "Invalid" ;
VAL_ 1127 DPSS_StRlxReturnBtn 0 "Default" 1 "Off" 2 "On" 3 "Invalid" ;
VAL_ 1127 DPSS_StRlxTltUpMvBtn 0 "Default" 1 "Off" 2 "On" 3 "Invalid" ;
VAL_ 1127 DPSS_StRlxTltDnMvBtn 0 "Default" 1 "Off" 2 "On" 3 "Invalid" ;
VAL_ 1128 DPSS_LumbarUpSw 0 "Default" 1 "Off" 2 "On" 3 "Invalid" ;
VAL_ 1128 DPSS_LumbarMidSw 0 "Default" 1 "Off" 2 "On" 3 "Invalid" ;
VAL_ 1128 DPSS_LumbarLowSw 0 "Default" 1 "Off" 2 "On" 3 "Invalid" ;
VAL_ 1128 DPSS_LumbarDefSw 0 "Default" 1 "Off" 2 "On" 3 "Invalid" ;
VAL_ 1128 DPSS_BolsterInfSw 0 "Default" 1 "Off" 2 "On" 3 "Invalid" ;
VAL_ 1128 DPSS_BolsterDefSw 0 "Default" 1 "Off" 2 "On" 3 "Invalid" ;
VAL_ 1128 DPSS_ActiveSw 0 "Default" 1 "Off" 2 "On" 3 "Invalid" ;
VAL_ 1128 DPSS_CushInfSw 0 "Default" 1 "Off" 2 "On" 3 "Invaild" ;
VAL_ 1128 DPSS_CushDefSw 0 "Default" 1 "Off" 2 "On" 3 "Invalid" ;
VAL_ 1129 DPSS_SldTch 0 "Default" 1 "Off" 2 "On" 3 "Invalid" ;
VAL_ 1129 DPSS_RclTch 0 "Default" 1 "Off" 2 "On" 3 "Invalid" ;
VAL_ 1129 DPSS_ExtTch 0 "Default" 1 "Off" 2 "On" 3 "Invalid" ;
VAL_ 1129 DPSS_LmbrTch 0 "Default" 1 "Off" 2 "On" 3 "Invalid" ;
VAL_ 1129 DPSS_CushOnOffTch 0 "Default" 1 "Off" 2 "On(Off State)" 3 "On(Mode1 State)" 4 "On(Mode2 State)" 5 "On(Mode3 State)" 6 "Reserved" 7 "Invalid" ;
VAL_ 1129 DPSS_HRestTch 0 "Default" 1 "Off" 2 "On" 3 "Invalid" ;
VAL_ 1129 DPSS_RelaxTch 0 "Default" 1 "Off" 2 "On" 3 "Invalid" ;
VAL_ 1105 FCS_FrLftStClrSwSta 0 "Default" 1 "Off" 2 "On" 3 "Error Indicator" ;
VAL_ 1105 HeatedSteerWheel_SwSta 0 "Default" 1 "Off" 2 "On" 3 "Error Indicator" ;
VAL_ 1105 FCS_DrvDrAtClsSwSta 0 "Default" 1 "OFF" 2 "ON" 3 "Error Indicator" ;
VAL_ 1105 FCS_AstDrAtClsSwSta 0 "Default" 1 "Off" 2 "On" 3 "Error Indicator" ;
VAL_ 1105 FCS_DrvModeSwSta 0 "Default" 1 "Off" 2 "On" 3 "Error Indicator" ;
VAL_ 1105 FCS_PDWSwSta 0 "Default" 1 "Off" 2 "On" 3 "Error Indicator" ;
VAL_ 1105 FCS_FrLftStHtrSwSta 0 "Default" 1 "Off" 2 "On" 3 "Error Indicator" ;
VAL_ 1105 FCS_Beep1Sound 0 "Default" 1 "Off" 2 "On" 3 "Error Indicator" ;
VAL_ 1105 FCS_LockTrayMsgDisp 0 "Default" 1 "Message Initial Pw Set" 2 "Message Pw 2nd Input" 3 "Message Pw Re-Input" 4 "Message Pw Input" 5 "Message Pw Error" 6 "Message Current Pw" 7 "Message Reset Pw" 10 "Reserved" 11 "Reserved" 12 "Reserved" 13 "Reserved" 14 "Reserved" 15 "Invalid" ;
VAL_ 1105 FCS_LockTrayStatDisp 0 "Default" 1 "Pw Set" 2 "Tray Lock" 3 "Tray Unlock" 4 "Pw Reset" 5 "Reserved" 6 "Reserved" 7 "Invalid" ;
VAL_ 1105 FCS_LockTrayPwNoDisp 0 "Default" 1 "Pw 1st Number" 2 "Pw 2nd Number" 3 "Pw 3rd Number" 4 "Pw 4th Number" 5 "Reserved" 6 "Reserved" 7 "Invalid" ;
VAL_ 1105 FCS_LockTrayTxtPopupReq 0 "Off" 1 "TEXT POP-UP Request On" 2 "Reserved" 3 "Error Indicator" ;
VAL_ 1105 FCS_LockTrayOSD 0 "Default" 1 "Message Pw Saved" 2 "Message Tray Lock" 3 "Message Tray Unlock" 4 "Message Pw Changed" 5 "Message Pw Reset" 6 "Message Tray Error" 7 "Invalid" ;
VAL_ 1105 FCS_FrRtStClrSwSta 0 "Default" 1 "Off" 2 "On" 3 "Error Indicator" ;
VAL_ 1105 FCS_FrRtStHtrSwSta 0 "Default" 1 "Off" 2 "On" 3 "Error Indicator" ;
VAL_ 1105 FCS_RrCurtainSwSta 0 "Default" 1 "Off" 2 "On" 3 "Error Indicator" ;
VAL_ 2378399489 GATEWAY_HS_B1_STS 0 "Default" 1 "Inactive" 2 "Active" 3 "Bus Off" 4 "Reserved" 5 "Reserved" 6 "Reserved" 7 "Error" ;
VAL_ 2378399489 GATEWAY_HS_B2_STS 0 "Default" 1 "Inactive" 2 "Active" 3 "Bus Off" 4 "Reserved" 5 "Reserved" 6 "Reserved" 7 "Error" ;
VAL_ 2378399489 GATEWAY_HS_D_STS 0 "Default" 1 "DiagMsgNotExist" 2 "DiagMsgExist" 3 "Reserved" 4 "Reserved" 5 "Reserved" 6 "Reserved" 7 "Error" ;
VAL_ 2378399489 GATEWAY_HS_I_STS 0 "Default" 1 "Inactive" 2 "Active" 3 "Bus Off" 4 "Reserved" 5 "Reserved" 6 "Reserved" 7 "Error" ;
VAL_ 2378399489 GATEWAY_HS_M_STS 0 "Default" 1 "Inactive" 2 "Active" 3 "Bus Off" 4 "Reserved" 5 "Reserved" 6 "Reserved" 7 "Error" ;
VAL_ 2378399489 GATEWAY_FD_C_STS 0 "Default" 1 "Inactive" 2 "Active" 3 "Bus Off" 4 "Reserved" 5 "Reserved" 6 "Reserved" 7 "Error" ;
VAL_ 2378399489 GATEWAY_FD_P1_STS 0 "Default" 1 "Inactive" 2 "Active" 3 "Bus Off" 4 "Reserved" 5 "Reserved" 6 "Reserved" 7 "Error" ;
VAL_ 2378399489 GATEWAY_FD_P2_STS 0 "Default" 1 "Inactive" 2 "Active" 3 "Bus Off" 4 "Reserved" 5 "Reserved" 6 "Reserved" 7 "Error" ;
VAL_ 2378399489 GATEWAY_FD_E_STS 0 "Default" 1 "Inactive" 2 "Active" 3 "Bus Off" 4 "Reserved" 5 "Reserved" 6 "Reserved" 7 "Error" ;
VAL_ 2378399489 GATEWAY_FD_I_STS 0 "Default" 1 "Inactive" 2 "Active" 3 "Bus Off" 4 "Reserved" 5 "Reserved" 6 "Reserved" 7 "Error" ;
VAL_ 2449771009 ODS_OccClassSta 1 "Class1" 2 "Class2" 4 "Indeterminate" ;
VAL_ 2449771009 ODS_SBRClassSta 0 "Empty / Indeterminate" 1 "Occupied" ;
VAL_ 1113 C_LH_Folding_State_PopUp 0 "Default" 1 "Folded (Finished)" 2 "Unfolded (Finished)" 3 "Mode-Fail (Anti-Pinch)" 4 "Mode-Fail (TGS & Break Condition)" 5 "Mode-Fail (System Error)" 6 "Unused" 7 "Invalid" ;
VAL_ 1113 C_RH_Folding_State_PopUp 0 "Default" 1 "Folded (Finish)" 2 "UnFolded (Finish)" 3 "Mode-Fail (Anti-Pinch)" 4 "Mode-Fail (TGS & Break Condition)" 5 "Mode-Fail (System Error)" 6 "Unused" 7 "Invalid" ;
VAL_ 1111 C_LH_Folding_Position 0 "Default" 1 "Folded" 2 "UnFolded" 3 "Folding (Moving)" 4 "UnFolding (Moving)" 5 "Unknown" 6 "Unused" 7 "Invalid" ;
VAL_ 1111 PFSU_RH_ReclMtrPos 0 "Default" 1 "Zone1" 2 "Zone2" 3 "Invalid" ;
VAL_ 1111 PFSU_RL_Folding_SW 0 "Default" 1 "OFF" 2 "ON" 3 "Invalid" ;
VAL_ 1111 PFSU_RR_Folding_SW 0 "Default" 1 "OFF" 2 "ON" 3 "Invalid" ;
VAL_ 1111 PFSU_RL_Unfolding_SW 0 "Default" 1 "OFF" 2 "ON" 3 "Invalid" ;
VAL_ 1111 PFSU_RR_Unfolding_SW 0 "Default" 1 "OFF" 2 "ON" 3 "Invalid" ;
VAL_ 1111 C_RH_Folding_Position 0 "Default" 1 "Folded" 2 "UnFolded" 3 "Folding (Moving)" 4 "UnFolding (Moving)" 5 "Unknown" 6 "Unused" 7 "Invalid" ;
VAL_ 1111 PFSU_RR_FoldingDis 0 "default" 1 "Off" 2 "On" 3 "Invalid" ;
VAL_ 1111 PFSU_RR_UnfoldingDis 0 "default" 1 "Off" 2 "On" 3 "Invalid" ;
VAL_ 1111 PFSU_RL_FoldingDis 0 "default" 1 "Off" 2 "On" 3 "Invalid" ;
VAL_ 1111 PFSU_RL_UnfoldingDis 0 "default" 1 "Off" 2 "On" 3 "Invalid" ;
VAL_ 1111 PFSU_RR_HrstFoldingDis 0 "default" 1 "Off" 2 "On" 3 "Invalid" ;
VAL_ 1111 PFSU_RL_HrstFoldingDis 0 "default" 1 "Off" 2 "On" 3 "Invalid" ;
VAL_ 1111 PFSU_RR_SlideFwdDis 0 "default" 1 "Off" 2 "On" 3 "Invalid" ;
VAL_ 1111 PFSU_RR_SlidBwdDis 0 "default" 1 "Off" 2 "On" 3 "Invalid" ;
VAL_ 1111 PFSU_RL_SlideFwdDis 0 "default" 1 "Off" 2 "On" 3 "Invalid" ;
VAL_ 1111 PFSU_RL_SlideBwdDis 0 "default" 1 "Off" 2 "On" 3 "Invalid" ;
VAL_ 1111 PFSU_Opt 0 "default" 1 "PFSU" 2 "Reserved" 3 "Invalid" ;
VAL_ 1111 PFSU_LH_ReclMtrPos 0 "Default" 1 "Zone1" 2 "Zone2" 3 "Invalid" ;
VAL_ 1089 RRPSM_SeatTyp 0 "Default" 1 "SEDAN" 2 "LIMOUSINE" 3 "Ivalid" ;
VAL_ 1089 RRPSM_RRStEsyAcsUSMSta 0 "Default" 1 "Off" 2 "On" 3 "Invalid" ;
VAL_ 1089 RRPSM_RRSlidePosition 0 "0x0x00~0xFE:POSITION" 254 "0x0x00~0xFE:POSITION" 255 "invalid" ;
VAL_ 1089 RRPSM_SeatPos_Sta 0 "Default" 1 "Memory1" 2 "Memory2" 3 "Memory3" 4 "Not Used" 5 "Not Used" 6 "Not Used" 7 "Any Postion" ;
VAL_ 1089 RRPSM_SeatPosSldLmt_Sta 0 "Default" 1 "Slide Fwd Limit" 2 "Slide Bwd Limit" 3 "Not Initialized" ;
VAL_ 1089 RRPSM_RearModeState 0 "Default" 1 "Off" 2 "Relax Mode" 3 "Relax Mode(rear only)" 4 "Return Mode" 5 "Monitor Mode" 6 "Reading Mode" 7 "Reserved" 8 "Reserved" 9 "Reserved" 10 "Reserved" 11 "Reserved" 12 "Reserved" 13 "Reserved" 14 "Reserved" 15 "Invalid" ;
VAL_ 1089 RRPSM_RRLegRestPosition 0 "0x0x00~0xFE:POSITION" 254 "0x0x00~0xFE:POSITION" 255 "invalid" ;
VAL_ 1107 RR_SHVU_SeatOptSta 0 "Init" 1 "Heater only 2step" 2 "Heater only 3step" 3 "Vent only 2step" 4 "Vent only 3step" 5 "Heater and Vent 2step" 6 "Heater and Vent 3step" 7 "Invalid" ;
VAL_ 1107 RR_SHVU_SeatHtOperSta 0 "Init" 1 "RESERVED" 2 "Heater & Vent OFF" 3 "Vent Low" 4 "Vent Mid" 5 "Vent High" 6 "Heater Low" 7 "Heater Mid" 8 "Heater High" 9 "RESERVED" 10 "RESERVED" 11 "RESERVED" 12 "RESERVED" 13 "RESERVED" 14 "RESERVED" 15 "Invalid" ;
VAL_ 1094 SLB_PlyBckSta 0 "Stop" 1 "Play 1" 2 "Play 2" 3 "Invalid" ;
VAL_ 1092 SSB_StrtStpBtnSw1Sta 0 "Released" 1 "Pressed" 2 "Not Used" 3 "Error Indicator" ;
VAL_ 1092 SSB_StrtStpBtnSw2Sta 0 "Released" 1 "Pressed" 2 "Not Used" 3 "Error Indicator" ;
VAL_ 1092 SMK_TrmnlCtrlSta 0 "Off" 1 "ACC" 2 "IGN" 3 "START" 4 "Reserved/" 5 "Reseved" 6 "Reseved" 7 "Reserved" 8 "Reserved" 9 "Reserved" 10 "Reserved" 11 "Reserved" 12 "Reserved" 13 "Reserved" 14 "Not Used" 15 "Error Indicator" ;
VAL_ 1092 SMK_TrmnlMngrSta 0 "Off" 1 "OFF_TO_START" 16 "ENGINE_RUNNING" 17 "Reserved" 18 "Reserved" 19 "Reserved" 20 "Reserved" 21 "Reserved" 22 "Reserved" 23 "Reserved" 24 "Reserved" 25 "Reserved" 26 "Reserved" 27 "Reserved" 28 "Reserved" 29 "Reserved" 30 "Not Used" 31 "Error Indicator" 2 "WAIT_ESCL_UNLOCK_ACC" 3 "ACC" 4 "ACC_SEARCH" 5 "ACC_TO_START" 6 "IGN" 7 "IGN_SEARCH" 8 "WAIT_ESCL_UNLOCK_OFF_TO_START" 9 "WAIT_ESCL_UNLOCK_START" 10 "WAIT_IGN1_ACC" 11 "WAIT_IGN1_ACC_SEARCH" 12 "WAIT_IGN1_ACC_TO_START" 13 "WAIT_IGN1_UNLOCK_OFF_TO_START" 14 "WAIT_IGN1_UNLOCK_START" 15 "START" ;
VAL_ 1092 SMK_AuthSta 0 "No Auth" 1 "Preauthentication" 2 "Authentication" 3 "Fast Restart" 4 "Reserved" 5 "Reseved" 6 "Not Used" 7 "Error Indicator" ;
VAL_ 1092 SMK_Ign1InSta 0 "IGN1 Off" 1 "IGN1 On" 2 "Not Used" 3 "Error Indicator" ;
VAL_ 1092 SMK_Ign1RlySta 0 "Off" 1 "On" 2 "Not Used" 3 "Error Indicator" ;
VAL_ 1092 SMK_Ign2InSta 0 "IGN2 Off" 1 "IGN2 On" 2 "Not Used" 3 "Error Indicator" ;
VAL_ 1092 SMK_Ign2RlySta 0 "Off" 1 "On" 2 "Not Used" 3 "Error Indicator" ;
VAL_ 1092 SMK_StrtFdbckSta 0 "Off" 1 "On" 2 "Not Used" 3 "Error Indicator" ;
VAL_ 1092 SMK_StrtrRlyOutSta 0 "Starter Relay Output Off" 1 "Starter Relay Output On" 2 "Not Used" 3 "Error Indicator" ;
VAL_ 1092 SMK_AccInSta 0 "ACC OFF" 1 "ACC ON" 2 "Not Used" 3 "Error Indicator" ;
VAL_ 1092 SMK_AccRlySta 0 "Off" 1 "On" 2 "Not Used" 3 "Error Indicator" ;
VAL_ 1092 SMK_CLUAccIndOnReq 0 "Cluster ACC Indicator Off" 1 "Cluster ACC Indicator On" 2 "Not Used" 3 "Error Indicator" ;
VAL_ 1092 SMK_VDModeActSta 0 "Off" 1 "On" 2 "Not Used" 3 "Error Indicator" ;
VAL_ 1092 SMK_TlEngRunSta 0 "Off" 1 "Tele Engine Running" 2 "Not Used" 3 "Error Indicator" ;
VAL_ 1092 SMK_TlCrnkModSta 0 "Normal Mode" 1 "Tele Cranking Mode" 2 "Not Used" 3 "Error Indicator" ;
VAL_ 1092 SMK_RmtKeyEngRunSta 0 "Off" 1 "Remote Key Engine Running" 2 "Not Used" 3 "Error Indicator" ;
VAL_ 1092 SMK_RmtKeyCrnkModSta 0 "Normal Mode" 1 "Remote Key Cranking Mode" 2 "Not Used" 3 "Error Indicator" ;
VAL_ 1093 Lamp_HzrdBlnkngSta 0 "Off" 1 "Single Blinking" 2 "Double Blinking" 3 "Reserved" 4 "Reserved" 5 "Reseved" 6 "Not Used" 7 "Error Indicator" ;
VAL_ 1093 RSPA_LearntSta 0 "Non-RSPA Learnt" 1 "RSPA Learnt" 2 "Reserved" 3 "Error Indicator" ;
VAL_ 1093 Lamp_SmrtWlcmLtOnReq 0 "Off" 1 "On" 2 "Not Used" 3 "Error Indicator" ;
VAL_ 1093 Fob_BattStaInfo 0 "Normal or No Information" 1 "Recent used FOB is in discharge warning voltage level" 2 "Not Used" 3 "Error Indicator" ;
VAL_ 1093 Fob_FoundDrvWlcmArea 0 "Default" 1 "Fob Found(Drv)" 2 "Not Used" 3 "Error Indicator" ;
VAL_ 1093 Fob_FoundAsstWlcmArea 0 "Default" 1 "Fob Found(Ast)" 2 "Not Used" 3 "Error Indicator" ;
VAL_ 1093 Fob_FoundExtrnlArea 0 "Default" 1 "Can't recognize" 2 "Fob recognized" 3 "Search in progress" ;
VAL_ 1093 Fob_FoundIntArea 0 "Default" 1 "Can't recognize" 2 "Fob recognized" 3 "Search in progress" ;
VAL_ 1093 Fob_LearntSta 0 "Learnt" 1 "Virgin" 2 "Not Used" 3 "Error Indicator" ;
VAL_ 1093 RSPA_RFSigErrSta 0 "Default" 1 "Signal Invalid" 2 "In Progress" 3 "Error Indicator" ;
VAL_ 1093 RSPA_CanErrSta 0 "Default" 1 "RSPA CAN Error" 2 "Not Used" 3 "Error Indicator" ;
VAL_ 1093 LFAnt_FltSta 0 "Normal" 1 "Fault" 2 "Not Used" 3 "Error Indicator" ;
VAL_ 1093 LFAnt_SrchSta 0 "Off" 1 "On (LF Searching)" 2 "Not Used" 3 "Error Indicator" ;
VAL_ 1093 Auth_ISKLearnSta 0 "Default(Normal)" 1 "Learning" 2 "Invalid" 3 "Neutral" 4 "Reserved" 5 "Reserved" 6 "Not used" 7 "Error Indicator" ;
VAL_ 1093 RSPA_ModSta_SMK 0 "RSPA Off" 1 "RSPA On" 2 "Reserved" 3 "Reserved" 4 "Reserved" 5 "Reseved" 6 "Not Used" 7 "Error Indicator" ;
VAL_ 1093 RSPA_FobBattSta 0 "Normal" 1 "Low Battery" 2 "Reserved" 3 "Reserved" 4 "Reserved" 5 "Reseved" 6 "Not Used" 7 "Error Indicator" ;
VAL_ 1093 Fob_BtnReleasedSta 0 "Default" 1 "Butten Released" 2 "Not used" 3 "Error Indicator" ;
VAL_ 1093 USM_SmrtTrnkTlgtModSta 0 "Default Value" 1 "HandsFree Off" 2 "HandsFree On" 3 "Reserved" 4 "Invalid" 5 "Reserved" 6 "Not Used" 7 "Error Indicator" ;
VAL_ 1093 USM_WALModSta 0 "Default" 1 "WAL Off" 2 "WAL On" 3 "Invalid" 4 "Reserved" 5 "Reseved" 6 "Not Used" 7 "Error Indicator" ;
VAL_ 1093 Fob_FoundWlcmArea 0 "Default (Off)" 1 "Fob Found" 2 "Not Used" 3 "Error Indicator" ;
VAL_ 1096 Audio_VcRecSwSta 0 "Off" 1 "Key On" 2 "RESERVED" 3 "Invalid" ;
VAL_ 1096 Audio_BluetoothPhnClSwSta 0 "Off" 1 "Key On" 2 "RESERVED" 3 "Invalid" ;
VAL_ 1096 Audio_BluetoothPhnHangUpSwSta 0 "Off" 1 "Key On" 2 "Reserved" 3 "Invalid" ;
VAL_ 1096 Audio_ModSwSta 0 "Off" 1 "Key On" 2 "RESERVED" 3 "Invalid" ;
VAL_ 1096 Audio_MutSwSta 0 "Off" 1 "Key On" 2 "Reserved" 3 "Invalid" ;
VAL_ 1096 Audio_SeekDnSwSta 0 "Off" 1 "Key On" 2 "Reserved" 3 "Invalid" ;
VAL_ 1096 Audio_SeekUpSwSta 0 "Off" 1 "Key On" 2 "Reserved" 3 "Invalid" ;
VAL_ 1096 Audio_VolDnSwSta 0 "Off" 1 "Key On" 2 "Reserved" 3 "Invalid" ;
VAL_ 1096 Audio_VolUpSwSta 0 "Off" 1 "Key On" 2 "Reserved" 3 "Invalid" ;
VAL_ 1096 Cluster_ModeSwSta 0 "Off" 1 "Key On" 2 "RESERVED" 3 "Invalid" ;
VAL_ 1096 Cluster_ScrlDnSwSta 0 "Idle" 1 "State1" 2 "State2" 3 "Invalid" ;
VAL_ 1096 Cluster_ScrlOkSwSta 0 "Off" 1 "Key On" 2 "Reserved" 3 "Invalid" ;
VAL_ 1096 Cluster_ScrlUpSwSta 0 "Idle" 1 "State1" 2 "State2" 3 "Invalid" ;
VAL_ 1096 Audio_CustomSwSta 0 "Off" 1 "Key On" 2 "RESERVED" 3 "Invalid" ;
VAL_ 1096 Cluster_ModeCCW 0 "Off" 1 "Key On" 2 "RESERVED" 3 "Invalid" ;
VAL_ 1096 Cluster_TripDnSwSta 0 "Off" 1 "Key On" 2 "Reserved" 3 "Invalid" ;
VAL_ 1096 Cluster_TripUpSwSta 0 "Off" 1 "Key On" 2 "Reserved" 3 "Invalid" ;
VAL_ 1096 Cluster_TripOkSwSta 0 "Off" 1 "Key On" 2 "Reserved" 3 "Invalid" ;
VAL_ 1096 SWRC_OpticalSwSnstvtSta 0 "Medium(default)" 1 "Low" 2 "High" 3 "Invalid" ;
VAL_ 1096 SWRC_RhOpticalSwSta 0 "Off" 1 "Swipe Up" 2 "Swipe Down" 3 "Swipe Left" 4 "Swipe Right" 5 "Swipe Fast Up" 6 "Swipe Fast Down" 7 "Swipe Fast Left" 8 "Swipe Fast Right" 9 "Drag Up" 10 "Drag Down" 11 "Drag Left" 12 "Drag Right" 13 "Touch" 14 "OK" 15 "Invalid" ;
VAL_ 1096 Audio_CustomSw3Sta 0 "Off" 1 "Key On" 2 "RESERVED" 3 "Invalid" ;
VAL_ 1099 USM_CmdWPCSta 0 "Default" 1 "Off(Disable)" 2 "On(Enable)" 3 "Invalid" ;
VAL_ 1099 WPC_SWVerMajor1 0 "0x0x0~0x7F:ASCII Code Value (HEX)" 127 "0x0x0~0x7F:ASCII Code Value (HEX)" ;
VAL_ 1099 WPC_PhnLftWrngSta 0 "Off" 1 "Cellphone on the pad" 2 "Charging" 3 "Charging complete" 4 "Cellphone reminder" 5 "Error" 6 "Reserved" 7 "Invalid" ;
VAL_ 1099 WPC_SWVerMinor1 0 "0x0x0~0x7F:ASCII Code Value (HEX)" 127 "0x0x0~0x7F:ASCII Code Value (HEX)" ;
VAL_ 1099 WPC_SWVerMinor2 0 "0x0x0~0x7F:ASCII Code Value (HEX)" 127 "0x0x0~0x7F:ASCII Code Value (HEX)" ;
